VERSION "HNNBNNNYNNNNNNNNNNNNNNNNNNNNNNNNNNNNNNNNNN/4/%%%/4/'%**4NNN///"

NS_ :

BS_:

BU_: BAP_Tester BedienDisp_mi BedienDisp_vo_mi CDI ConMod_CD DashCAM Gateway_Max ICC_IO_Node LSH OCU RDK_RS3 Sound_MIB_ab_Gen3 STH ZR_MIB_EINSTIEG_ab_Gen3 ZR_MIB_OPTION_ab_Gen3 ZR_MIB_TOP_ab_Gen3

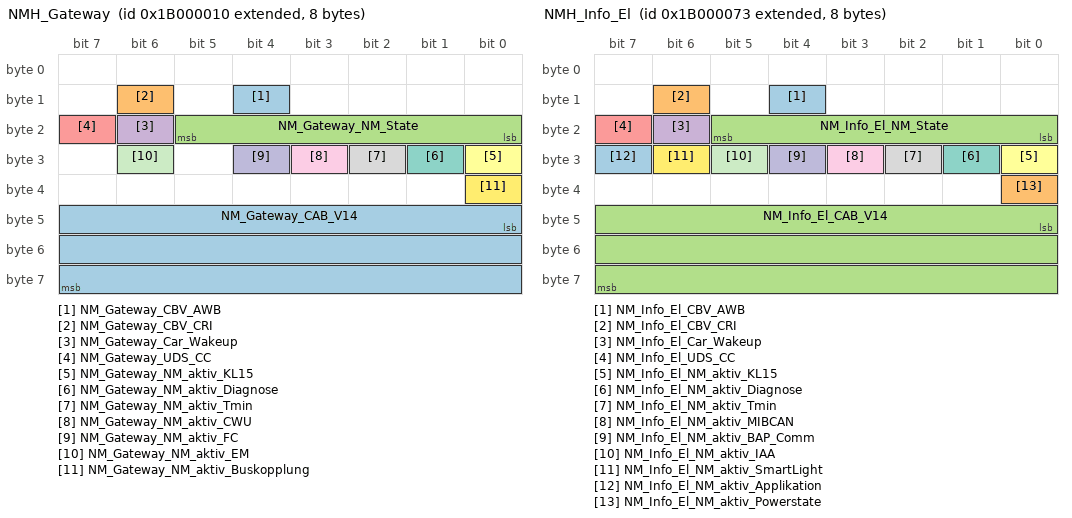
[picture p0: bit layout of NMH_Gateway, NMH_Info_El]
BO_ 2600468496 NMH_Gateway: 8 Gateway_Max
 SG_ NM_Gateway_CBV_AWB : 12|1@1+ (1.0,0.0) [0.0|1] ""  Vector__XXX
 SG_ NM_Gateway_CBV_CRI : 14|1@1+ (1.0,0.0) [0.0|1] ""  Vector__XXX
 SG_ NM_Gateway_NM_State : 16|6@1+ (1.0,0.0) [0.0|63] ""  BedienDisp_mi,BedienDisp_vo_mi,CDI,ConMod_CD,DashCAM,ICC_IO_Node,LSH,OCU,RDK_RS3,Sound_MIB_ab_Gen3,STH,ZR_MIB_EINSTIEG_ab_Gen3,ZR_MIB_OPTION_ab_Gen3,ZR_MIB_TOP_ab_Gen3
 SG_ NM_Gateway_Car_Wakeup : 22|1@1+ (1.0,0.0) [0.0|1] ""  ICC_IO_Node,ZR_MIB_EINSTIEG_ab_Gen3,ZR_MIB_OPTION_ab_Gen3,ZR_MIB_TOP_ab_Gen3
 SG_ NM_Gateway_UDS_CC : 23|1@1+ (1.0,0.0) [0.0|1] ""  Vector__XXX
 SG_ NM_Gateway_NM_aktiv_KL15 : 24|1@1+ (1.0,0.0) [0.0|1] ""  Vector__XXX
 SG_ NM_Gateway_NM_aktiv_Diagnose : 25|1@1+ (1.0,0.0) [0.0|1] ""  Vector__XXX
 SG_ NM_Gateway_NM_aktiv_Tmin : 26|1@1+ (1.0,0.0) [0.0|1] ""  Vector__XXX
 SG_ NM_Gateway_NM_aktiv_CWU : 27|1@1+ (1.0,0.0) [0.0|1] ""  Vector__XXX
 SG_ NM_Gateway_NM_aktiv_FC : 28|1@1+ (1.0,0.0) [0.0|1] ""  Vector__XXX
 SG_ NM_Gateway_NM_aktiv_EM : 30|1@1+ (1.0,0.0) [0.0|1] ""  Vector__XXX
 SG_ NM_Gateway_NM_aktiv_Buskopplung : 32|1@1+ (1.0,0.0) [0.0|1] ""  Vector__XXX
 SG_ NM_Gateway_CAB_V14 : 40|24@1+ (1.0,0.0) [0.0|16777215] ""  Vector__XXX

BO_ 2600468595 NMH_Info_El: 8 ICC_IO_Node
 SG_ NM_Info_El_CBV_AWB : 12|1@1+ (1.0,0.0) [0.0|1] ""  Gateway_Max
 SG_ NM_Info_El_CBV_CRI : 14|1@1+ (1.0,0.0) [0.0|1] ""  Gateway_Max
 SG_ NM_Info_El_NM_State : 16|6@1+ (1.0,0.0) [0.0|63] ""  BedienDisp_mi,BedienDisp_vo_mi,CDI,ConMod_CD,DashCAM,LSH,OCU,RDK_RS3,Sound_MIB_ab_Gen3,STH
 SG_ NM_Info_El_Car_Wakeup : 22|1@1+ (1.0,0.0) [0.0|1] ""  Gateway_Max
 SG_ NM_Info_El_UDS_CC : 23|1@1+ (1.0,0.0) [0.0|1] ""  Vector__XXX
 SG_ NM_Info_El_NM_aktiv_KL15 : 24|1@1+ (1.0,0.0) [0.0|1] ""  Vector__XXX
 SG_ NM_Info_El_NM_aktiv_Diagnose : 25|1@1+ (1.0,0.0) [0.0|1] ""  Vector__XXX
 SG_ NM_Info_El_NM_aktiv_Tmin : 26|1@1+ (1.0,0.0) [0.0|1] ""  Vector__XXX
 SG_ NM_Info_El_NM_aktiv_MIBCAN : 27|1@1+ (1.0,0.0) [0.0|1] ""  Vector__XXX
 SG_ NM_Info_El_NM_aktiv_BAP_Comm : 28|1@1+ (1.0,0.0) [0.0|1] ""  Vector__XXX
 SG_ NM_Info_El_NM_aktiv_IAA : 29|1@1+ (1.0,0.0) [0.0|1] ""  Vector__XXX
 SG_ NM_Info_El_NM_aktiv_SmartLight : 30|1@1+ (1.0,0.0) [0.0|1] ""  Vector__XXX
 SG_ NM_Info_El_NM_aktiv_Applikation : 31|1@1+ (1.0,0.0) [0.0|1] ""  Vector__XXX
 SG_ NM_Info_El_NM_aktiv_Powerstate : 32|1@1+ (1.0,0.0) [0.0|1] ""  Vector__XXX
 SG_ NM_Info_El_CAB_V14 : 40|24@1+ (1.0,0.0) [0.0|16777215] ""  Gateway_Max

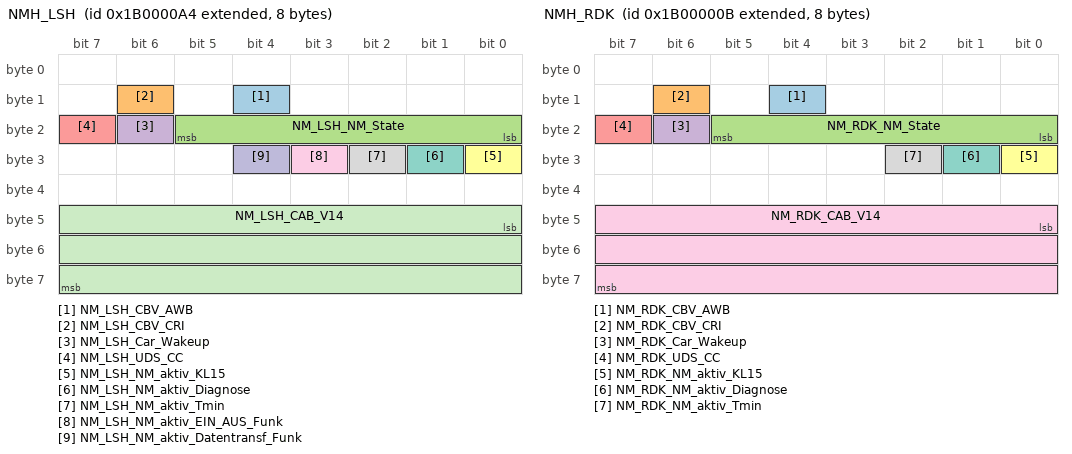
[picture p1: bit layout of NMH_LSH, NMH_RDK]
BO_ 2600468644 NMH_LSH: 8 LSH
 SG_ NM_LSH_CBV_AWB : 12|1@1+ (1.0,0.0) [0.0|1] ""  Gateway_Max
 SG_ NM_LSH_CBV_CRI : 14|1@1+ (1.0,0.0) [0.0|1] ""  Gateway_Max
 SG_ NM_LSH_NM_State : 16|6@1+ (1.0,0.0) [0.0|63] ""  BedienDisp_mi,BedienDisp_vo_mi,CDI,ConMod_CD,DashCAM,ICC_IO_Node,OCU,RDK_RS3,Sound_MIB_ab_Gen3,STH,ZR_MIB_EINSTIEG_ab_Gen3,ZR_MIB_OPTION_ab_Gen3,ZR_MIB_TOP_ab_Gen3
 SG_ NM_LSH_Car_Wakeup : 22|1@1+ (1.0,0.0) [0.0|1] ""  Gateway_Max
 SG_ NM_LSH_UDS_CC : 23|1@1+ (1.0,0.0) [0.0|1] ""  Vector__XXX
 SG_ NM_LSH_NM_aktiv_KL15 : 24|1@1+ (1.0,0.0) [0.0|1] ""  Vector__XXX
 SG_ NM_LSH_NM_aktiv_Diagnose : 25|1@1+ (1.0,0.0) [0.0|1] ""  Vector__XXX
 SG_ NM_LSH_NM_aktiv_Tmin : 26|1@1+ (1.0,0.0) [0.0|1] ""  Vector__XXX
 SG_ NM_LSH_NM_aktiv_EIN_AUS_Funk : 27|1@1+ (1.0,0.0) [0.0|1] ""  Vector__XXX
 SG_ NM_LSH_NM_aktiv_Datentransf_Funk : 28|1@1+ (1.0,0.0) [0.0|1] ""  Vector__XXX
 SG_ NM_LSH_CAB_V14 : 40|24@1+ (1.0,0.0) [0.0|16777215] ""  Gateway_Max

BO_ 2600468491 NMH_RDK: 8 RDK_RS3
 SG_ NM_RDK_CBV_AWB : 12|1@1+ (1.0,0.0) [0.0|1] ""  Gateway_Max
 SG_ NM_RDK_CBV_CRI : 14|1@1+ (1.0,0.0) [0.0|1] ""  Gateway_Max
 SG_ NM_RDK_NM_State : 16|6@1+ (1.0,0.0) [0.0|63] ""  BedienDisp_mi,BedienDisp_vo_mi,CDI,ConMod_CD,DashCAM,ICC_IO_Node,LSH,OCU,Sound_MIB_ab_Gen3,STH,ZR_MIB_EINSTIEG_ab_Gen3,ZR_MIB_OPTION_ab_Gen3,ZR_MIB_TOP_ab_Gen3
 SG_ NM_RDK_Car_Wakeup : 22|1@1+ (1.0,0.0) [0.0|1] ""  Gateway_Max
 SG_ NM_RDK_UDS_CC : 23|1@1+ (1.0,0.0) [0.0|1] ""  Vector__XXX
 SG_ NM_RDK_NM_aktiv_KL15 : 24|1@1+ (1.0,0.0) [0.0|1] ""  Vector__XXX
 SG_ NM_RDK_NM_aktiv_Diagnose : 25|1@1+ (1.0,0.0) [0.0|1] ""  Vector__XXX
 SG_ NM_RDK_NM_aktiv_Tmin : 26|1@1+ (1.0,0.0) [0.0|1] ""  Vector__XXX
 SG_ NM_RDK_CAB_V14 : 40|24@1+ (1.0,0.0) [0.0|16777215] ""  Gateway_Max

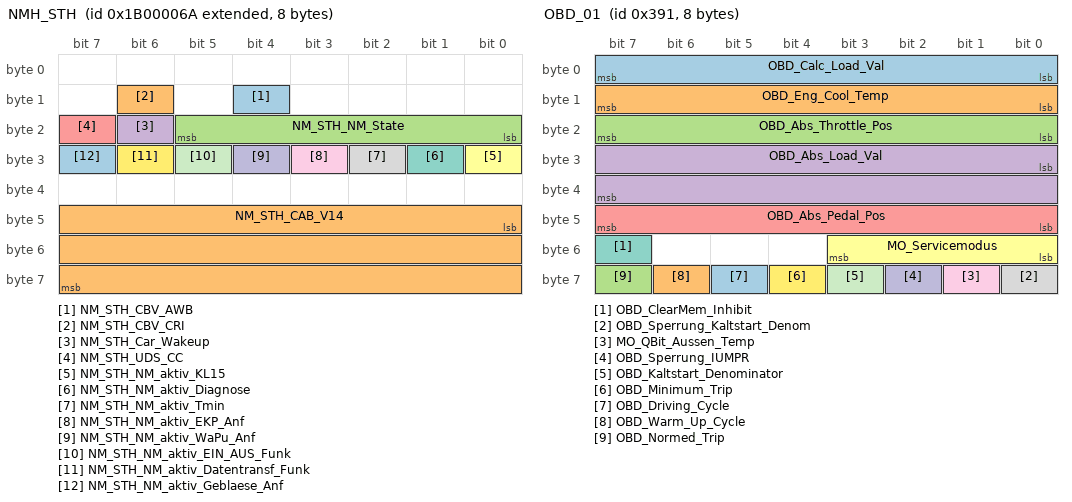
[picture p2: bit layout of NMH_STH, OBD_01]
BO_ 2600468586 NMH_STH: 8 STH
 SG_ NM_STH_CBV_AWB : 12|1@1+ (1.0,0.0) [0.0|1] ""  Gateway_Max
 SG_ NM_STH_CBV_CRI : 14|1@1+ (1.0,0.0) [0.0|1] ""  Gateway_Max
 SG_ NM_STH_NM_State : 16|6@1+ (1.0,0.0) [0.0|63] ""  BedienDisp_mi,BedienDisp_vo_mi,CDI,ConMod_CD,DashCAM,ICC_IO_Node,LSH,OCU,RDK_RS3,Sound_MIB_ab_Gen3,ZR_MIB_EINSTIEG_ab_Gen3,ZR_MIB_OPTION_ab_Gen3,ZR_MIB_TOP_ab_Gen3
 SG_ NM_STH_Car_Wakeup : 22|1@1+ (1.0,0.0) [0.0|1] ""  Gateway_Max
 SG_ NM_STH_UDS_CC : 23|1@1+ (1.0,0.0) [0.0|1] ""  Vector__XXX
 SG_ NM_STH_NM_aktiv_KL15 : 24|1@1+ (1.0,0.0) [0.0|1] ""  Vector__XXX
 SG_ NM_STH_NM_aktiv_Diagnose : 25|1@1+ (1.0,0.0) [0.0|1] ""  Vector__XXX
 SG_ NM_STH_NM_aktiv_Tmin : 26|1@1+ (1.0,0.0) [0.0|1] ""  Vector__XXX
 SG_ NM_STH_NM_aktiv_EKP_Anf : 27|1@1+ (1.0,0.0) [0.0|1] ""  Vector__XXX
 SG_ NM_STH_NM_aktiv_WaPu_Anf : 28|1@1+ (1.0,0.0) [0.0|1] ""  Vector__XXX
 SG_ NM_STH_NM_aktiv_EIN_AUS_Funk : 29|1@1+ (1.0,0.0) [0.0|1] ""  Vector__XXX
 SG_ NM_STH_NM_aktiv_Datentransf_Funk : 30|1@1+ (1.0,0.0) [0.0|1] ""  Vector__XXX
 SG_ NM_STH_NM_aktiv_Geblaese_Anf : 31|1@1+ (1.0,0.0) [0.0|1] ""  Vector__XXX
 SG_ NM_STH_CAB_V14 : 40|24@1+ (1.0,0.0) [0.0|16777215] ""  Gateway_Max

BO_ 2589283909 NR_01_CAL_Text_01: 8 Gateway_Max
 SG_ NR_01_CAL_Text_Request : 0|1@1+ (1.0,0.0) [0.0|1] ""  ZR_MIB_EINSTIEG_ab_Gen3,ZR_MIB_OPTION_ab_Gen3,ZR_MIB_TOP_ab_Gen3
 SG_ NR_01_CAL_Text_Data_1 : 8|56@1+ (1.0,0.0) [0.0|72057594037927935] ""  ZR_MIB_EINSTIEG_ab_Gen3,ZR_MIB_OPTION_ab_Gen3,ZR_MIB_TOP_ab_Gen3

BO_ 2589283910 NR_01_CAL_Text_02: 8 Gateway_Max
 SG_ NR_01_CAL_Text_Data_2 : 0|64@1+ (1.0,0.0) [0.0|18446744073709551615] ""  ZR_MIB_EINSTIEG_ab_Gen3,ZR_MIB_OPTION_ab_Gen3,ZR_MIB_TOP_ab_Gen3

BO_ 2589283911 NR_01_CAL_Text_03: 8 Gateway_Max
 SG_ NR_01_CAL_Text_Data_3 : 0|64@1+ (1.0,0.0) [0.0|18446744073709551615] ""  ZR_MIB_EINSTIEG_ab_Gen3,ZR_MIB_OPTION_ab_Gen3,ZR_MIB_TOP_ab_Gen3

BO_ 2589283912 NR_02_CAL_Text_01: 8 Gateway_Max
 SG_ NR_02_CAL_Text_Request : 0|1@1+ (1.0,0.0) [0.0|1] ""  ZR_MIB_EINSTIEG_ab_Gen3,ZR_MIB_OPTION_ab_Gen3,ZR_MIB_TOP_ab_Gen3
 SG_ NR_02_CAL_Text_Data_1 : 8|56@1+ (1.0,0.0) [0.0|72057594037927935] ""  ZR_MIB_EINSTIEG_ab_Gen3,ZR_MIB_OPTION_ab_Gen3,ZR_MIB_TOP_ab_Gen3

BO_ 2589283913 NR_02_CAL_Text_02: 8 Gateway_Max
 SG_ NR_02_CAL_Text_Data_2 : 0|64@1+ (1.0,0.0) [0.0|18446744073709551615] ""  ZR_MIB_EINSTIEG_ab_Gen3,ZR_MIB_OPTION_ab_Gen3,ZR_MIB_TOP_ab_Gen3

BO_ 2589283914 NR_02_CAL_Text_03: 8 Gateway_Max
 SG_ NR_02_CAL_Text_Data_3 : 0|64@1+ (1.0,0.0) [0.0|18446744073709551615] ""  ZR_MIB_EINSTIEG_ab_Gen3,ZR_MIB_OPTION_ab_Gen3,ZR_MIB_TOP_ab_Gen3

BO_ 2589283915 NR_03_CAL_Text_01: 8 Gateway_Max
 SG_ NR_03_CAL_Text_Request : 0|1@1+ (1.0,0.0) [0.0|1] ""  ZR_MIB_EINSTIEG_ab_Gen3,ZR_MIB_OPTION_ab_Gen3,ZR_MIB_TOP_ab_Gen3
 SG_ NR_03_CAL_Text_Data_1 : 8|56@1+ (1.0,0.0) [0.0|72057594037927935] ""  ZR_MIB_EINSTIEG_ab_Gen3,ZR_MIB_OPTION_ab_Gen3,ZR_MIB_TOP_ab_Gen3

BO_ 2589283916 NR_03_CAL_Text_02: 8 Gateway_Max
 SG_ NR_03_CAL_Text_Data_2 : 0|64@1+ (1.0,0.0) [0.0|18446744073709551615] ""  ZR_MIB_EINSTIEG_ab_Gen3,ZR_MIB_OPTION_ab_Gen3,ZR_MIB_TOP_ab_Gen3

BO_ 2589283917 NR_03_CAL_Text_03: 8 Gateway_Max
 SG_ NR_03_CAL_Text_Data_3 : 0|64@1+ (1.0,0.0) [0.0|18446744073709551615] ""  ZR_MIB_EINSTIEG_ab_Gen3,ZR_MIB_OPTION_ab_Gen3,ZR_MIB_TOP_ab_Gen3

BO_ 2589283918 NR_04_CAL_Text_01: 8 Gateway_Max
 SG_ NR_04_CAL_Text_Request : 0|1@1+ (1.0,0.0) [0.0|1] ""  ZR_MIB_EINSTIEG_ab_Gen3,ZR_MIB_OPTION_ab_Gen3,ZR_MIB_TOP_ab_Gen3
 SG_ NR_04_CAL_Text_Data_1 : 8|56@1+ (1.0,0.0) [0.0|72057594037927935] ""  ZR_MIB_EINSTIEG_ab_Gen3,ZR_MIB_OPTION_ab_Gen3,ZR_MIB_TOP_ab_Gen3

BO_ 2589283919 NR_04_CAL_Text_02: 8 Gateway_Max
 SG_ NR_04_CAL_Text_Data_2 : 0|64@1+ (1.0,0.0) [0.0|18446744073709551615] ""  ZR_MIB_EINSTIEG_ab_Gen3,ZR_MIB_OPTION_ab_Gen3,ZR_MIB_TOP_ab_Gen3

BO_ 2589283920 NR_04_CAL_Text_03: 8 Gateway_Max
 SG_ NR_04_CAL_Text_Data_3 : 0|64@1+ (1.0,0.0) [0.0|18446744073709551615] ""  ZR_MIB_EINSTIEG_ab_Gen3,ZR_MIB_OPTION_ab_Gen3,ZR_MIB_TOP_ab_Gen3

BO_ 2589284036 NR_05_CAL_Text_01: 8 Gateway_Max
 SG_ NR_05_CAL_Text_Request : 0|1@1+ (1.0,0.0) [0.0|1] ""  ZR_MIB_EINSTIEG_ab_Gen3,ZR_MIB_OPTION_ab_Gen3,ZR_MIB_TOP_ab_Gen3
 SG_ NR_05_CAL_Text_Data_1 : 8|56@1+ (1.0,0.0) [0.0|72057594037927935] ""  ZR_MIB_EINSTIEG_ab_Gen3,ZR_MIB_OPTION_ab_Gen3,ZR_MIB_TOP_ab_Gen3

BO_ 2589284037 NR_05_CAL_Text_02: 8 Gateway_Max
 SG_ NR_05_CAL_Text_Data_2 : 0|64@1+ (1.0,0.0) [0.0|18446744073709551615] ""  ZR_MIB_EINSTIEG_ab_Gen3,ZR_MIB_OPTION_ab_Gen3,ZR_MIB_TOP_ab_Gen3

BO_ 2589284038 NR_05_CAL_Text_03: 8 Gateway_Max
 SG_ NR_05_CAL_Text_Data_3 : 0|64@1+ (1.0,0.0) [0.0|18446744073709551615] ""  ZR_MIB_EINSTIEG_ab_Gen3,ZR_MIB_OPTION_ab_Gen3,ZR_MIB_TOP_ab_Gen3

BO_ 2589284039 NR_06_CAL_Text_01: 8 Gateway_Max
 SG_ NR_06_CAL_Text_Request : 0|1@1+ (1.0,0.0) [0.0|1] ""  ZR_MIB_EINSTIEG_ab_Gen3,ZR_MIB_OPTION_ab_Gen3,ZR_MIB_TOP_ab_Gen3
 SG_ NR_06_CAL_Text_Data_1 : 8|56@1+ (1.0,0.0) [0.0|72057594037927935] ""  ZR_MIB_EINSTIEG_ab_Gen3,ZR_MIB_OPTION_ab_Gen3,ZR_MIB_TOP_ab_Gen3

BO_ 2589284040 NR_06_CAL_Text_02: 8 Gateway_Max
 SG_ NR_06_CAL_Text_Data_2 : 0|64@1+ (1.0,0.0) [0.0|18446744073709551615] ""  ZR_MIB_EINSTIEG_ab_Gen3,ZR_MIB_OPTION_ab_Gen3,ZR_MIB_TOP_ab_Gen3

BO_ 2589284041 NR_06_CAL_Text_03: 8 Gateway_Max
 SG_ NR_06_CAL_Text_Data_3 : 0|64@1+ (1.0,0.0) [0.0|18446744073709551615] ""  ZR_MIB_EINSTIEG_ab_Gen3,ZR_MIB_OPTION_ab_Gen3,ZR_MIB_TOP_ab_Gen3

BO_ 913 OBD_01: 8 Gateway_Max
 SG_ OBD_Calc_Load_Val : 0|8@1+ (0.39215686274509803,0) [0E-17|99.99999999999999765] "Unit_PerCent"  OCU
 SG_ OBD_Eng_Cool_Temp : 8|8@1+ (1,-40) [-40|215] "Unit_DegreCelsi"  Vector__XXX
 SG_ OBD_Abs_Throttle_Pos : 16|8@1+ (0.39215686274509803,0) [0E-17|99.99999999999999765] "Unit_PerCent"  OCU
 SG_ OBD_Abs_Load_Val : 24|16@1+ (0.39215686274509803,0) [0E-17|25699.99999999999939605] "Unit_PerCent"  OCU
 SG_ OBD_Abs_Pedal_Pos : 40|8@1+ (0.39215686274509803,0) [0E-17|99.99999999999999765] "Unit_PerCent"  OCU
 SG_ MO_Servicemodus : 48|4@1+ (1.0,0.0) [0.0|15] ""  OCU
 SG_ OBD_ClearMem_Inhibit : 55|1@1+ (1.0,0.0) [0.0|1] ""  Vector__XXX
 SG_ OBD_Sperrung_Kaltstart_Denom : 56|1@1+ (1.0,0.0) [0.0|1] ""  Vector__XXX
 SG_ MO_QBit_Aussen_Temp : 57|1@1+ (1.0,0.0) [0.0|1] ""  OCU
 SG_ OBD_Sperrung_IUMPR : 58|1@1+ (1.0,0.0) [0.0|1] ""  Vector__XXX
 SG_ OBD_Kaltstart_Denominator : 59|1@1+ (1.0,0.0) [0.0|1] ""  ConMod_CD
 SG_ OBD_Minimum_Trip : 60|1@1+ (1.0,0.0) [0.0|1] ""  Vector__XXX
 SG_ OBD_Driving_Cycle : 61|1@1+ (1.0,0.0) [0.0|1] ""  BedienDisp_mi,ConMod_CD,DashCAM,ICC_IO_Node,ZR_MIB_EINSTIEG_ab_Gen3,ZR_MIB_OPTION_ab_Gen3,ZR_MIB_TOP_ab_Gen3
 SG_ OBD_Warm_Up_Cycle : 62|1@1+ (1.0,0.0) [0.0|1] ""  ConMod_CD,ICC_IO_Node,OCU
 SG_ OBD_Normed_Trip : 63|1@1+ (1.0,0.0) [0.0|1] ""  Vector__XXX

BO_ 2550399540 OBDC_BedienDisp_m_Req: 8 Gateway_Max
 SG_ OBDC_BedienDisp_m_Req_Data : 0|64@1+ (1.0,0.0) [0.0|18446744073709551615] ""  BedienDisp_mi

BO_ 2550530612 OBDC_BedienDisp_m_Resp: 8 BedienDisp_mi
 SG_ OBDC_BedienDisp_m_Resp_Data : 0|64@1+ (1.0,0.0) [0.0|18446744073709551615] ""  Gateway_Max

BO_ 2549875362 OBDC_BedienDisp_vm_Req: 8 Gateway_Max
 SG_ OBDC_BedienDisp_vm_Req_Data : 0|64@1+ (1.0,0.0) [0.0|18446744073709551615] ""  BedienDisp_vo_mi

BO_ 2550006434 OBDC_BedienDisp_vm_Resp: 8 BedienDisp_vo_mi
 SG_ OBDC_BedienDisp_vm_Resp_Data : 0|64@1+ (1.0,0.0) [0.0|18446744073709551615] ""  Gateway_Max

BO_ 2549875303 OBDC_eCall_Req: 8 Gateway_Max
 SG_ OBDC_eCall_Req_Data : 0|64@1+ (1.0,0.0) [0.0|18446744073709551615] ""  ConMod_CD,OCU

BO_ 2550006375 OBDC_eCall_Resp: 8 ConMod_CD
 SG_ OBDC_eCall_Resp_Data : 0|64@1+ (1.0,0.0) [0.0|18446744073709551615] ""  Gateway_Max

BO_ 2549940736 OBDC_Funktionaler_Req_All: 8 Gateway_Max
 SG_ OBDC_Funktionaler_Req_All_Data : 0|64@1+ (1.0,0.0) [0.0|18446744073709551615] ""  BedienDisp_mi,BedienDisp_vo_mi,ConMod_CD,ICC_IO_Node,LSH,OCU,RDK_RS3,STH,ZR_MIB_EINSTIEG_ab_Gen3,ZR_MIB_OPTION_ab_Gen3,ZR_MIB_TOP_ab_Gen3

BO_ 2549875315 OBDC_Info_El_Req: 8 Gateway_Max
 SG_ OBDC_Info_El_Req_Data : 0|64@1+ (1.0,0.0) [0.0|18446744073709551615] ""  ZR_MIB_EINSTIEG_ab_Gen3,ZR_MIB_OPTION_ab_Gen3,ZR_MIB_TOP_ab_Gen3

BO_ 2550006387 OBDC_Info_El_Resp: 8 ZR_MIB_EINSTIEG_ab_Gen3
 SG_ OBDC_Info_El_Resp_Data : 0|64@1+ (1.0,0.0) [0.0|18446744073709551615] ""  Gateway_Max

BO_ 2549875364 OBDC_LSH_Req: 8 Gateway_Max
 SG_ OBDC_LSH_Req_Data : 0|64@1+ (1.0,0.0) [0.0|18446744073709551615] ""  LSH

BO_ 2550006436 OBDC_LSH_Resp: 8 LSH
 SG_ OBDC_LSH_Resp_Data : 0|64@1+ (1.0,0.0) [0.0|18446744073709551615] ""  Gateway_Max

BO_ 2549875211 OBDC_RDK_Req: 8 Gateway_Max
 SG_ OBDC_RDK_Req_Data : 0|64@1+ (1.0,0.0) [0.0|18446744073709551615] ""  RDK_RS3

BO_ 2550006283 OBDC_RDK_Resp: 8 RDK_RS3
 SG_ OBDC_RDK_Resp_Data : 0|64@1+ (1.0,0.0) [0.0|18446744073709551615] ""  Gateway_Max

BO_ 2549903374 OBDC_SSN_ABT_1_Req: 8 Gateway_Max
 SG_ OBDC_SSN_ABT_1_Req_Data : 0|64@1+ (1.0,0.0) [0.0|18446744073709551615] ""  ICC_IO_Node,ZR_MIB_EINSTIEG_ab_Gen3,ZR_MIB_OPTION_ab_Gen3

BO_ 2550034446 OBDC_SSN_ABT_1_Resp: 8 ICC_IO_Node
 SG_ OBDC_SSN_ABT_1_Resp_Data : 0|64@1+ (1.0,0.0) [0.0|18446744073709551615] ""  Gateway_Max

BO_ 2549875306 OBDC_STH_Req: 8 Gateway_Max
 SG_ OBDC_STH_Req_Data : 0|64@1+ (1.0,0.0) [0.0|18446744073709551615] ""  STH

BO_ 2550006378 OBDC_STH_Resp: 8 STH
 SG_ OBDC_STH_Resp_Data : 0|64@1+ (1.0,0.0) [0.0|18446744073709551615] ""  Gateway_Max

BO_ 2549875309 OBDC_TV_Tuner_Req: 8 Gateway_Max
 SG_ OBDC_TV_Tuner_Req_Data : 0|64@1+ (1.0,0.0) [0.0|18446744073709551615] ""  ZR_MIB_TOP_ab_Gen3

BO_ 2550006381 OBDC_TV_Tuner_Resp: 8 ZR_MIB_TOP_ab_Gen3
 SG_ OBDC_TV_Tuner_Resp_Data : 0|64@1+ (1.0,0.0) [0.0|18446744073709551615] ""  Gateway_Max

BO_ 2549875365 OBDC_WLC1_Req: 8 Gateway_Max
 SG_ OBDC_WLC1_Req_Data : 0|64@1+ (1,0) [0|18446744073709551615] "Unit_None"  ZR_MIB_OPTION_ab_Gen3,ZR_MIB_TOP_ab_Gen3

BO_ 2550006437 OBDC_WLC1_Resp: 8 ZR_MIB_OPTION_ab_Gen3
 SG_ OBDC_WLC1_Resp_Data : 0|64@1+ (1,0) [0|18446744073709551615] "Unit_None"  Gateway_Max

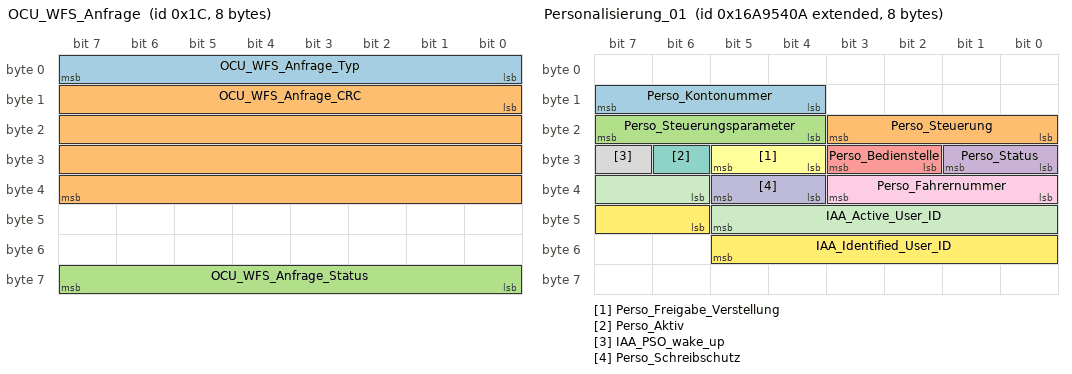
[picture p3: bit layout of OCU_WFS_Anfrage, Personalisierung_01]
BO_ 28 OCU_WFS_Anfrage: 8 OCU
 SG_ OCU_WFS_Anfrage_Typ : 0|8@1+ (1.0,0.0) [0.0|255] ""  Gateway_Max
 SG_ OCU_WFS_Anfrage_CRC : 8|32@1+ (1.0,0.0) [0.0|4294967295] ""  Gateway_Max
 SG_ OCU_WFS_Anfrage_Status : 56|8@1+ (1.0,0.0) [0.0|255] ""  Gateway_Max

BO_ 2589283656 ORU_01: 8 Gateway_Max
 SG_ ORU_Warnung : 58|2@1+ (1.0,0.0) [0.0|3] ""  ICC_IO_Node,ZR_MIB_EINSTIEG_ab_Gen3,ZR_MIB_OPTION_ab_Gen3,ZR_MIB_TOP_ab_Gen3
 SG_ ORU_Status : 61|3@1+ (1.0,0.0) [0.0|7] ""  ConMod_CD,ICC_IO_Node,OCU,ZR_MIB_EINSTIEG_ab_Gen3,ZR_MIB_OPTION_ab_Gen3,ZR_MIB_TOP_ab_Gen3

BO_ 2549909095 ORU_eCall_Req: 8 ICC_IO_Node
 SG_ ORU_eCall_Req_Data : 0|64@1+ (1.0,0.0) [0.0|18446744073709551615] ""  ConMod_CD

BO_ 2550040167 ORU_eCall_Resp: 8 ConMod_CD
 SG_ ORU_eCall_Resp_Data : 0|64@1+ (1.0,0.0) [0.0|18446744073709551615] ""  ICC_IO_Node

BO_ 1175 Parkhilfe_01: 8 Gateway_Max
 SG_ PH_Visualisierung : 0|3@1+ (1.0,0.0) [0.0|7] ""  Vector__XXX
 SG_ PDC_Tonausgabe_Front : 4|4@1+ (1.0,0.0) [0.0|15] ""  Vector__XXX
 SG_ PDC_Tonausgabe_Heck : 8|4@1+ (1.0,0.0) [0.0|15] ""  Vector__XXX
 SG_ PH_nachtr_Stopp_Anf : 12|1@1+ (1.0,0.0) [0.0|1] ""  Vector__XXX
 SG_ PH_Abschaltursache : 13|3@1+ (1.0,0.0) [0.0|7] ""  Vector__XXX
 SG_ PH_Opt_Anzeige_V_ein : 16|1@1+ (1.0,0.0) [0.0|1] ""  Vector__XXX
 SG_ PH_Opt_Anzeige_H_ein : 17|1@1+ (1.0,0.0) [0.0|1] ""  Vector__XXX
 SG_ PH_Opt_Anz_V_Hindernis : 18|1@1+ (1.0,0.0) [0.0|1] ""  Vector__XXX
 SG_ PH_Opt_Anz_H_Hindernis : 19|1@1+ (1.0,0.0) [0.0|1] ""  Vector__XXX
 SG_ PH_Tongeber_V_aktiv : 20|1@1+ (1.0,0.0) [0.0|1] ""  Vector__XXX
 SG_ PH_Tongeber_H_aktiv : 21|1@1+ (1.0,0.0) [0.0|1] ""  Vector__XXX
 SG_ PH_Tongeber_mute : 22|1@1+ (1.0,0.0) [0.0|1] ""  Vector__XXX
 SG_ PH_Anf_Audioabsenkung : 23|1@1+ (1.0,0.0) [0.0|1] ""  OCU,ZR_MIB_EINSTIEG_ab_Gen3,ZR_MIB_OPTION_ab_Gen3,ZR_MIB_TOP_ab_Gen3
 SG_ PH_Tongeber_H_verfuegbar : 24|1@1+ (1.0,0.0) [0.0|1] ""  Vector__XXX
 SG_ PLA_Anf_Aufschaltung_RVC : 25|1@1+ (1.0,0.0) [0.0|1] ""  Vector__XXX
 SG_ PH_Taster : 28|2@1+ (1.0,0.0) [0.0|3] ""  Vector__XXX
 SG_ PH_Anf_Verdeck : 30|2@1+ (1.0,0.0) [0.0|3] ""  Vector__XXX
 SG_ PH_Frequenz_hinten : 32|4@1+ (1,0) [0|15] ""  Vector__XXX
 SG_ PH_Lautstaerke_hinten : 36|4@1+ (1,0) [0|15] ""  Vector__XXX
 SG_ PH_Frequenz_vorn : 40|4@1+ (1,0) [0|15] ""  Vector__XXX
 SG_ PH_Lautstaerke_vorn : 44|4@1+ (1,0) [0|15] ""  Vector__XXX
 SG_ PH_StartStopp_Info : 49|2@1+ (1.0,0.0) [0.0|3] ""  Vector__XXX
 SG_ PH_Stoermeldung : 52|4@1+ (1.0,0.0) [0.0|15] ""  Vector__XXX
 SG_ PH_defekt : 56|1@1+ (1.0,0.0) [0.0|1] ""  Vector__XXX
 SG_ PH_gestoert : 57|1@1+ (1.0,0.0) [0.0|1] ""  Vector__XXX
 SG_ PH_Systemzustand : 58|3@1+ (1.0,0.0) [0.0|7] ""  Vector__XXX
 SG_ PH_Display_Kundenwunsch : 61|2@1+ (1.0,0.0) [0.0|3] ""  Vector__XXX

BO_ 1355 Parkhilfe_04: 8 Gateway_Max
 SG_ RBFMA_PaCo_BrakeIntervention : 0|3@1+ (1.0,0.0) [0.0|7] ""  OCU
 SG_ RBFMA_PaCo_MainState : 3|3@1+ (1.0,0.0) [0.0|7] ""  OCU
 SG_ RAB_PaCo_FunctionState : 6|3@1+ (1.0,0.0) [0.0|7] ""  Vector__XXX
 SG_ RBF_Anf_Meldungen : 9|3@1+ (1.0,0.0) [0.0|7] ""  Vector__XXX
 SG_ PH_Verschmutzungsmeldung : 12|4@1+ (1.0,0.0) [0.0|15] ""  OCU
 SG_ PH_Aufschaltursache : 16|5@1+ (1.0,0.0) [0.0|31] ""  Vector__XXX
 SG_ PH_Ton_Ausgabe : 21|3@1+ (1.0,0.0) [0.0|7] ""  OCU,ZR_MIB_EINSTIEG_ab_Gen3,ZR_MIB_OPTION_ab_Gen3,ZR_MIB_TOP_ab_Gen3
 SG_ PH_Ton_Pausenlaenge : 24|8@1+ (1.0,0.0) [0.0|255] ""  OCU,ZR_MIB_EINSTIEG_ab_Gen3,ZR_MIB_OPTION_ab_Gen3,ZR_MIB_TOP_ab_Gen3
 SG_ APSOPS_PaCo_ObstacleDetectRear : 32|3@1+ (1.0,0.0) [0.0|7] ""  OCU
 SG_ APSOPS_PaCo_ObstacleDetectFront : 35|3@1+ (1.0,0.0) [0.0|7] ""  OCU
 SG_ APSOPS_PaCo_Button : 38|2@1+ (1.0,0.0) [0.0|3] ""  OCU
 SG_ APSOPS_PaCo_MainState : 40|3@1+ (1.0,0.0) [0.0|7] ""  OCU
 SG_ APSOPS_PaCo_FunctionState : 43|3@1+ (1.0,0.0) [0.0|7] ""  OCU
 SG_ APSOPS_PaCo_ApproachingRear : 46|1@1+ (1.0,0.0) [0.0|1] ""  OCU
 SG_ APSOPS_PaCo_ApproachingFront : 47|1@1+ (1.0,0.0) [0.0|1] ""  OCU
 SG_ APS_PaCo_WarningTones : 48|1@1+ (1.0,0.0) [0.0|1] ""  OCU
 SG_ PH_Ton_Richtung : 49|3@1+ (1.0,0.0) [0.0|7] ""  OCU,ZR_MIB_EINSTIEG_ab_Gen3,ZR_MIB_OPTION_ab_Gen3,ZR_MIB_TOP_ab_Gen3
 SG_ PH_Ton_Lautstaerke : 52|3@1+ (1.0,0.0) [0.0|7] ""  OCU,ZR_MIB_EINSTIEG_ab_Gen3,ZR_MIB_OPTION_ab_Gen3,ZR_MIB_TOP_ab_Gen3
 SG_ PH_WAH_Meldung : 55|3@1+ (1.0,0.0) [0.0|7] ""  Vector__XXX
 SG_ RBF_PaCo_Anf_Meldungen : 58|3@1+ (1.0,0.0) [0.0|7] ""  Vector__XXX
 SG_ RBF_PMO_Bereich_erkannt : 61|1@1+ (1.0,0.0) [0.0|1] ""  Vector__XXX

BO_ 2527679498 Personalisierung_01: 8 Gateway_Max
 SG_ Perso_Kontonummer : 12|4@1+ (1.0,0.0) [0.0|15] ""  OCU,ZR_MIB_EINSTIEG_ab_Gen3,ZR_MIB_OPTION_ab_Gen3,ZR_MIB_TOP_ab_Gen3
 SG_ Perso_Steuerung : 16|4@1+ (1.0,0.0) [0.0|15] ""  OCU,ZR_MIB_EINSTIEG_ab_Gen3,ZR_MIB_OPTION_ab_Gen3,ZR_MIB_TOP_ab_Gen3
 SG_ Perso_Steuerungsparameter : 20|4@1+ (1.0,0.0) [0.0|15] ""  OCU,ZR_MIB_EINSTIEG_ab_Gen3,ZR_MIB_OPTION_ab_Gen3,ZR_MIB_TOP_ab_Gen3
 SG_ Perso_Status : 24|2@1+ (1.0,0.0) [0.0|3] ""  OCU,ZR_MIB_EINSTIEG_ab_Gen3,ZR_MIB_OPTION_ab_Gen3,ZR_MIB_TOP_ab_Gen3
 SG_ Perso_Bedienstelle : 26|2@1+ (1.0,0.0) [0.0|3] ""  OCU
 SG_ Perso_Freigabe_Verstellung : 28|2@1+ (1.0,0.0) [0.0|3] ""  OCU
 SG_ Perso_Aktiv : 30|1@1+ (1.0,0.0) [0.0|1] ""  OCU
 SG_ IAA_PSO_wake_up : 31|1@1+ (1.0,0.0) [0.0|1] ""  OCU,ZR_MIB_EINSTIEG_ab_Gen3,ZR_MIB_OPTION_ab_Gen3,ZR_MIB_TOP_ab_Gen3
 SG_ Perso_Fahrernummer : 32|4@1+ (1.0,0.0) [0.0|15] ""  OCU,ZR_MIB_TOP_ab_Gen3
 SG_ Perso_Schreibschutz : 36|2@1+ (1.0,0.0) [0.0|3] ""  OCU
 SG_ IAA_Active_User_ID : 38|8@1+ (1,0) [0|255] "Unit_None"  OCU,ZR_MIB_EINSTIEG_ab_Gen3,ZR_MIB_OPTION_ab_Gen3,ZR_MIB_TOP_ab_Gen3
 SG_ IAA_Identified_User_ID : 46|8@1+ (1,0) [0|255] "Unit_None"  OCU,ZR_MIB_EINSTIEG_ab_Gen3,ZR_MIB_OPTION_ab_Gen3,ZR_MIB_TOP_ab_Gen3

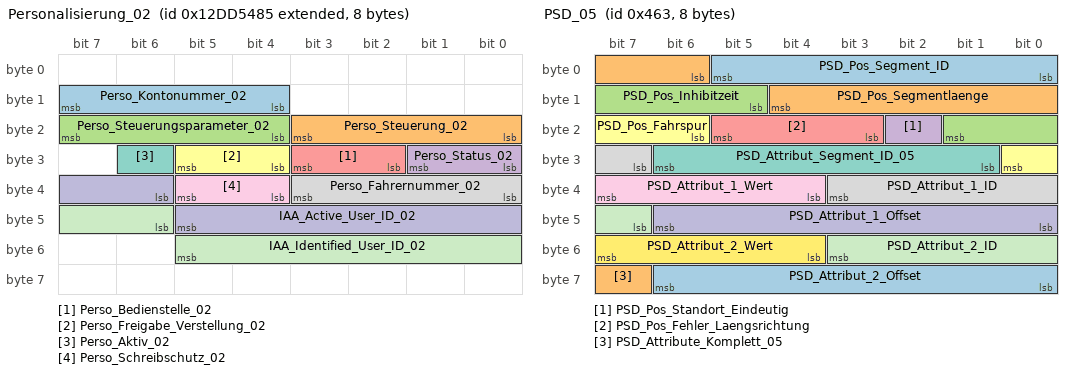
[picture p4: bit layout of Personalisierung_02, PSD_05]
BO_ 2463978629 Personalisierung_02: 8 Gateway_Max
 SG_ Perso_Kontonummer_02 : 12|4@1+ (1.0,0.0) [0.0|15] ""  Gateway_Max,ZR_MIB_EINSTIEG_ab_Gen3,ZR_MIB_TOP_ab_Gen3
 SG_ Perso_Steuerung_02 : 16|4@1+ (1.0,0.0) [0.0|15] ""  Gateway_Max,ZR_MIB_EINSTIEG_ab_Gen3,ZR_MIB_TOP_ab_Gen3
 SG_ Perso_Steuerungsparameter_02 : 20|4@1+ (1.0,0.0) [0.0|15] ""  Gateway_Max,ZR_MIB_EINSTIEG_ab_Gen3,ZR_MIB_TOP_ab_Gen3
 SG_ Perso_Status_02 : 24|2@1+ (1.0,0.0) [0.0|3] ""  Gateway_Max,ZR_MIB_EINSTIEG_ab_Gen3,ZR_MIB_TOP_ab_Gen3
 SG_ Perso_Bedienstelle_02 : 26|2@1+ (1.0,0.0) [0.0|3] ""  Gateway_Max
 SG_ Perso_Freigabe_Verstellung_02 : 28|2@1+ (1.0,0.0) [0.0|3] ""  Gateway_Max
 SG_ Perso_Aktiv_02 : 30|1@1+ (1.0,0.0) [0.0|1] ""  Gateway_Max
 SG_ Perso_Fahrernummer_02 : 32|4@1+ (1.0,0.0) [0.0|15] ""  Gateway_Max
 SG_ Perso_Schreibschutz_02 : 36|2@1+ (1.0,0.0) [0.0|3] ""  Gateway_Max
 SG_ IAA_Active_User_ID_02 : 38|8@1+ (1,0) [0|255] "Unit_None"  Gateway_Max,ZR_MIB_EINSTIEG_ab_Gen3,ZR_MIB_OPTION_ab_Gen3,ZR_MIB_TOP_ab_Gen3
 SG_ IAA_Identified_User_ID_02 : 46|8@1+ (1,0) [0|255] "Unit_None"  Gateway_Max,ZR_MIB_EINSTIEG_ab_Gen3,ZR_MIB_OPTION_ab_Gen3,ZR_MIB_TOP_ab_Gen3

BO_ 319 PreCrash_02: 8 Gateway_Max
 SG_ PreCrash_Charisma_FahrPr : 12|4@1+ (1.0,0.0) [0.0|15] ""  Vector__XXX
 SG_ PreCrash_Charisma_Status : 16|2@1+ (1.0,0.0) [0.0|3] ""  Vector__XXX
 SG_ PreCrash_Schiebedach_schliessen : 18|1@1+ (1.0,0.0) [0.0|1] ""  Vector__XXX
 SG_ PreCrash_Fenster_schliessen : 19|1@1+ (1.0,0.0) [0.0|1] ""  Vector__XXX
 SG_ PreCrash_Blinken : 20|3@1+ (1.0,0.0) [0.0|7] ""  Vector__XXX
 SG_ SC_PreSense_FCWP : 23|1@1+ (1.0,0.0) [0.0|1] ""  Vector__XXX
 SG_ PreCrash_Tueren_Verriegeln : 24|1@1+ (1.0,0.0) [0.0|1] ""  Vector__XXX
 SG_ PreCrash_FS_Laengsverstellung : 25|1@1+ (1.0,0.0) [0.0|1] ""  Vector__XXX
 SG_ PreCrash_Anforderung_AFR : 26|3@1+ (1.0,0.0) [0.0|7] ""  Vector__XXX
 SG_ SC_PreCrash_LED : 29|2@1+ (1.0,0.0) [0.0|3] ""  Vector__XXX
 SG_ PreCrash_FS_Pneumatik_ansteuern : 31|1@1+ (1.0,0.0) [0.0|1] ""  Vector__XXX
 SG_ PreCrash_BFS_Pneumatik_ansteuern : 32|1@1+ (1.0,0.0) [0.0|1] ""  Vector__XXX
 SG_ PreCrash_Fo_Pneumatik_ansteuern : 33|1@1+ (1.0,0.0) [0.0|1] ""  Vector__XXX
 SG_ PreCrash_FS_Sitzlehne_verfahren : 34|3@1+ (1.0,0.0) [0.0|7] ""  Vector__XXX
 SG_ PreCrash_BFS_Sitzlehne_verfahren : 37|3@1+ (1.0,0.0) [0.0|7] ""  Vector__XXX
 SG_ PreCrash_Fo_Sitzlehne_verfahren : 40|3@1+ (1.0,0.0) [0.0|7] ""  Vector__XXX
 SG_ PreCrash_FS_KSV_verfahren : 43|4@1+ (1.0,0.0) [0.0|15] ""  Vector__XXX
 SG_ PreCrash_BFS_KSV_verfahren : 47|4@1+ (1.0,0.0) [0.0|15] ""  Vector__XXX
 SG_ PreCrash_Fo_KSV_verfahren : 51|4@1+ (1.0,0.0) [0.0|15] ""  Vector__XXX
 SG_ PreCrash_BFS_Laengsverstellung : 55|1@1+ (1.0,0.0) [0.0|1] ""  Vector__XXX
 SG_ SC_PreCrash_Warnung : 56|4@1+ (1.0,0.0) [0.0|15] ""  OCU
 SG_ SC_PreCrash_Texte : 60|4@1+ (1.0,0.0) [0.0|15] ""  Vector__XXX

BO_ 1122 PSD_04: 8 ZR_MIB_EINSTIEG_ab_Gen3
 SG_ PSD_Segment_ID : 0|6@1+ (1,0) [2|63] ""  Gateway_Max,OCU
 SG_ PSD_Vorgaenger_Segment_ID : 6|6@1+ (1,0) [2|63] ""  Gateway_Max,OCU
 SG_ PSD_Segmentlaenge : 12|7@1+ (2,0) [0|254] "Unit_Meter"  Gateway_Max,OCU
 SG_ PSD_Strassenkategorie : 19|3@1+ (1.0,0.0) [0.0|7] ""  Gateway_Max,OCU
 SG_ PSD_Endkruemmung : 22|8@1+ (1,0) [0|254] "Unit_None"  Gateway_Max,OCU
 SG_ PSD_Endkruemmung_Vorz : 30|1@1+ (1.0,0.0) [0.0|1] ""  Gateway_Max,OCU
 SG_ PSD_Idenditaets_ID : 31|6@1+ (1,0) [2|63] ""  Gateway_Max,OCU
 SG_ PSD_ADAS_Qualitaet : 37|1@1+ (1.0,0.0) [0.0|1] ""  Gateway_Max,OCU
 SG_ PSD_wahrscheinlichster_Pfad : 38|1@1+ (1.0,0.0) [0.0|1] ""  Gateway_Max,OCU
 SG_ PSD_Geradester_Pfad : 39|1@1+ (1.0,0.0) [0.0|1] ""  Gateway_Max,OCU
 SG_ PSD_Fahrspuren_Anzahl : 40|3@1+ (1.0,0.0) [0.0|7] ""  Gateway_Max,OCU
 SG_ PSD_Bebauung : 43|1@1+ (1.0,0.0) [0.0|1] ""  Gateway_Max,OCU
 SG_ PSD_Segment_Komplett : 44|1@1+ (1.0,0.0) [0.0|1] ""  Gateway_Max,OCU
 SG_ PSD_Rampe : 45|2@1+ (1.0,0.0) [0.0|3] ""  Gateway_Max,OCU
 SG_ PSD_Anfangskruemmung : 47|8@1+ (1,0) [0|254] ""  Gateway_Max,OCU
 SG_ PSD_Anfangskruemmung_Vorz : 55|1@1+ (1.0,0.0) [0.0|1] ""  Gateway_Max,OCU
 SG_ PSD_Abzweigerichtung : 56|1@1+ (1.0,0.0) [0.0|1] ""  Gateway_Max,OCU
 SG_ PSD_Abzweigewinkel : 57|7@1+ (1.417323,0) [0.000000|180.000021] ""  Gateway_Max,OCU

BO_ 1123 PSD_05: 8 ZR_MIB_EINSTIEG_ab_Gen3
 SG_ PSD_Pos_Segment_ID : 0|6@1+ (1,0) [2|63] ""  Gateway_Max,OCU
 SG_ PSD_Pos_Segmentlaenge : 6|7@1+ (2,0) [0|254] "Unit_Meter"  Gateway_Max
 SG_ PSD_Pos_Inhibitzeit : 13|5@1+ (10,0) [0|310] "Unit_MilliSecon"  Gateway_Max
 SG_ PSD_Pos_Standort_Eindeutig : 18|1@1+ (1.0,0.0) [0.0|1] ""  Gateway_Max
 SG_ PSD_Pos_Fehler_Laengsrichtung : 19|3@1+ (1.0,0.0) [0.0|7] ""  Gateway_Max
 SG_ PSD_Pos_Fahrspur : 22|3@1+ (1.0,0.0) [0.0|7] ""  Gateway_Max,OCU
 SG_ PSD_Attribut_Segment_ID_05 : 25|6@1+ (1,0) [2|63] ""  Gateway_Max
 SG_ PSD_Attribut_1_ID : 31|5@1+ (1,0) [1|31] ""  Gateway_Max
 SG_ PSD_Attribut_1_Wert : 36|4@1+ (1,0) [0|15] "Unit_None"  Gateway_Max
 SG_ PSD_Attribut_1_Offset : 40|7@1+ (2,0) [0|254] "Unit_Meter"  Gateway_Max
 SG_ PSD_Attribut_2_ID : 47|5@1+ (1,0) [1|31] ""  Gateway_Max
 SG_ PSD_Attribut_2_Wert : 52|4@1+ (1,0) [0|15] "Unit_None"  Gateway_Max
 SG_ PSD_Attribut_2_Offset : 56|7@1+ (2,0) [0|254] "Unit_Meter"  Gateway_Max
 SG_ PSD_Attribute_Komplett_05 : 63|1@1+ (1.0,0.0) [0.0|1] ""  Gateway_Max

BO_ 1124 PSD_06: 8 ZR_MIB_EINSTIEG_ab_Gen3
 SG_ PSD_06_Mux M  : 0|3@1+ (1.0,0.0) [0.0|7] ""  Gateway_Max,OCU
 SG_ PSD_Sys_Segment_ID m0  : 3|6@1+ (1,0) [2|63] ""  Gateway_Max,OCU
 SG_ PSD_Attribut_Segment_ID m1  : 3|6@1+ (1,0) [2|63] ""  Gateway_Max,OCU
 SG_ PSD_Ges_Segment_ID m2  : 3|6@1+ (1,0) [2|63] ""  Gateway_Max,OCU
 SG_ PSD_Baum_Laenge_VZ m3  : 3|1@1+ (1.0,0.0) [0.0|1] ""  Gateway_Max,OCU
 SG_ PSD_Steigung_1_Segment_ID m4  : 3|6@1+ (1,0) [2|63] ""  Gateway_Max,OCU
 SG_ PSD_Baum_Laenge m3  : 4|25@1+ (0.00001,0) [0.00000|180.00000] "Unit_DegreOfArc"  Gateway_Max,OCU
 SG_ PSD_Sys_Laendercode m0  : 9|8@1+ (1,0) [0|255] "Unit_None"  Gateway_Max,OCU
 SG_ PSD_Attribut_3_ID m1  : 9|5@1+ (1,0) [1|31] ""  Gateway_Max,OCU
 SG_ PSD_Ges_Offset m2  : 9|7@1+ (2,0) [0|254] "Unit_Meter"  Gateway_Max,OCU
 SG_ PSD_Steigung_1_A_Steigung m4  : 9|7@1+ (0.12,0) [0.00|15.00] "Unit_PerCent"  Gateway_Max,OCU
 SG_ PSD_Attribut_3_Offset m1  : 14|7@1+ (2,0) [0|254] "Unit_Meter"  Gateway_Max,OCU
 SG_ PSD_Ges_Geschwindigkeit m2  : 16|5@1+ (1.0,0.0) [0.0|31] ""  Gateway_Max,OCU
 SG_ PSD_Steigung_1_A_Vorz m4  : 16|1@1+ (1.0,0.0) [0.0|1] ""  Gateway_Max,OCU
 SG_ PSD_Sys_Geschwindigkeit_Einheit m0  : 17|1@1+ (1.0,0.0) [0.0|1] ""  Gateway_Max,OCU
 SG_ PSD_Steigung_1_A_Offset m4  : 17|7@1+ (2,0) [0|254] "Unit_Meter"  Gateway_Max,OCU
 SG_ PSD_Sys_Verkehrsrichtung m0  : 18|1@1+ (1.0,0.0) [0.0|1] ""  Gateway_Max,OCU
 SG_ PSD_Sys_Geometrieguete m0  : 19|2@1+ (1.0,0.0) [0.0|3] ""  Gateway_Max,OCU
 SG_ PSD_Sys_Mapmatchingguete m0  : 21|2@1+ (1.0,0.0) [0.0|3] ""  Gateway_Max,OCU
 SG_ PSD_Attribut_3_Wert m1  : 21|4@1+ (1,0) [0|15] "Unit_None"  Gateway_Max,OCU
 SG_ PSD_Ges_Typ m2  : 21|2@1+ (1.0,0.0) [0.0|3] ""  Gateway_Max,OCU
 SG_ PSD_Sys_Alter_Karte m0  : 23|3@1+ (1.0,0.0) [0.0|7] ""  Gateway_Max,OCU
 SG_ PSD_Ges_Spur_Geschw_Begrenzung m2  : 23|6@1+ (1.0,0.0) [0.0|63] ""  Gateway_Max,OCU
 SG_ PSD_Steigung_1_B_Steigung m4  : 24|7@1+ (0.12,0) [0.00|15.00] "Unit_PerCent"  Gateway_Max,OCU
 SG_ PSD_Attribut_4_ID m1  : 25|5@1+ (1,0) [1|31] ""  Gateway_Max,OCU
 SG_ PSD_Sys_Zielfuehrung m0  : 26|1@1+ (1.0,0.0) [0.0|1] ""  Gateway_Max,OCU
 SG_ PSD_Sys_US_State m0  : 27|6@1+ (1.0,0.0) [0.0|63] ""  Gateway_Max,OCU
 SG_ PSD_Ges_Geschwindigkeit_Gespann m2  : 29|2@1+ (1.0,0.0) [0.0|3] ""  Gateway_Max,OCU
 SG_ PSD_Baum_Breite_VZ m3  : 29|1@1+ (1.0,0.0) [0.0|1] ""  Gateway_Max,OCU
 SG_ PSD_Attribut_4_Wert m1  : 30|4@1+ (1,0) [0|15] ""  Gateway_Max,OCU
 SG_ PSD_Baum_Breite m3  : 30|24@1+ (0.00001,0) [0.00000|90.00000] "Unit_DegreOfArc"  Gateway_Max,OCU
 SG_ PSD_Ges_Geschwindigkeit_Witter m2  : 31|2@1+ (1.0,0.0) [0.0|3] ""  Gateway_Max,OCU
 SG_ PSD_Steigung_1_B_Vorz m4  : 31|1@1+ (1.0,0.0) [0.0|1] ""  Gateway_Max,OCU
 SG_ PSD_Steigung_1_B_Offset m4  : 32|7@1+ (2,0) [0|254] "Unit_Meter"  Gateway_Max,OCU
 SG_ PSD_Sys_Quali_Geometrien m0  : 33|3@1+ (1,0) [0|7] "Unit_None"  Gateway_Max,OCU
 SG_ PSD_Ges_Geschwindigkeit_Tag_Anf m2  : 33|3@1+ (1.0,0.0) [0.0|7] ""  Gateway_Max,OCU
 SG_ PSD_Attribut_4_Offset m1  : 34|7@1+ (2,0) [0|254] "Unit_Meter"  Gateway_Max,OCU
 SG_ PSD_Sys_Quali_Ortsinfo m0  : 36|2@1+ (1,0) [0|3] "Unit_None"  Gateway_Max,OCU
 SG_ PSD_Ges_Geschwindigkeit_Tag_Ende m2  : 36|3@1+ (1.0,0.0) [0.0|7] ""  Gateway_Max,OCU
 SG_ PSD_Sys_Quali_verfuegbar m0  : 38|1@1+ (1.0,0.0) [0.0|1] ""  Gateway_Max,OCU
 SG_ PSD_Sys_Zielfuehrung_geaendert m0  : 39|1@1+ (1.0,0.0) [0.0|1] ""  Gateway_Max,OCU
 SG_ PSD_Ges_Geschwindigkeit_Std_Anf m2  : 39|5@1+ (1,0) [0|24] "Unit_Hours"  Gateway_Max,OCU
 SG_ PSD_Steigung_1_Attribute_kompl m4  : 39|1@1+ (1.0,0.0) [0.0|1] ""  Gateway_Max,OCU
 SG_ PSD_Sys_Geometrieguete_erweitert m0  : 40|8@1+ (1.0,0.0) [0.0|255] ""  Gateway_Max,OCU
 SG_ PSD_Steigung_2_Segment_ID m4  : 40|6@1+ (1,0) [2|63] ""  Gateway_Max,OCU
 SG_ PSD_Attribut_5_ID m1  : 41|5@1+ (1,0) [1|31] ""  Gateway_Max,OCU
 SG_ PSD_Ges_Geschwindigkeit_Std_Ende m2  : 44|5@1+ (1,0) [0|24] "Unit_Hours"  Gateway_Max,OCU
 SG_ PSD_Attribut_5_Offset m1  : 46|7@1+ (2,0) [0|254] "Unit_Meter"  Gateway_Max,OCU
 SG_ PSD_Steigung_2_Steigung m4  : 46|7@1+ (0.12,0) [0.00|15.00] "Unit_PerCent"  Gateway_Max,OCU
 SG_ PSD_Sys_Quali_sonstige_Attribute m0  : 48|3@1+ (1,0) [0|7] "Unit_None"  Gateway_Max,OCU
 SG_ PSD_Ges_Ueberholverbot m2  : 49|2@1+ (1.0,0.0) [0.0|3] ""  Gateway_Max,OCU
 SG_ PSD_Sys_Quali_Steigungen m0  : 51|3@1+ (1,0) [0|7] ""  Gateway_Max,OCU
 SG_ PSD_Ges_Wechselverkehrszeichen m2  : 51|3@1+ (1.0,0.0) [0.0|7] ""  Gateway_Max,OCU
 SG_ PSD_Attribut_5_Wert m1  : 53|4@1+ (1,0) [0|15] ""  Gateway_Max,OCU
 SG_ PSD_Steigung_2_Vorz m4  : 53|1@1+ (1.0,0.0) [0.0|1] ""  Gateway_Max,OCU
 SG_ PSD_Sys_Quali_Strassenkennz m0  : 54|3@1+ (1,0) [0|7] "Unit_None"  Gateway_Max,OCU
 SG_ PSD_Wechselverkehrszeichen_Typ m2  : 54|2@1+ (1.0,0.0) [0.0|3] ""  Gateway_Max,OCU
 SG_ PSD_Baum_Ausrichtung m3  : 54|10@1+ (0.3515625,0) [0E-7|359.6484375] "Unit_DegreOfArc"  Gateway_Max,OCU
 SG_ PSD_Steigung_2_Offset m4  : 54|7@1+ (2,0) [0|254] "Unit_Meter"  Gateway_Max,OCU
 SG_ PSD_Ges_Gesetzlich_Kategorie m2  : 56|3@1+ (1.0,0.0) [0.0|7] ""  Gateway_Max,OCU
 SG_ PSD_Sys_Quali_Tempolimits m0  : 57|3@1+ (1,0) [0|7] "Unit_None"  Gateway_Max,OCU
 SG_ PSD_Attribute_Komplett_06 m1  : 57|1@1+ (1.0,0.0) [0.0|1] ""  Gateway_Max,OCU
 SG_ PSD_Ges_Gesetzlich_Zusatz m2  : 59|2@1+ (1.0,0.0) [0.0|3] ""  Gateway_Max,OCU
 SG_ PSD_Sys_Quali_Vorfahrtsregelung m0  : 60|3@1+ (1,0) [0|7] "Unit_None"  Gateway_Max,OCU
 SG_ PSD_Ges_Verkehrszeichen_Quelle m2  : 61|2@1+ (1.0,0.0) [0.0|3] ""  Gateway_Max,OCU
 SG_ PSD_Steigung_2_Attribute_kompl m4  : 61|1@1+ (1.0,0.0) [0.0|1] ""  Gateway_Max,OCU
 SG_ PSD_Ges_Attribute_Komplett m2  : 63|1@1+ (1.0,0.0) [0.0|1] ""  Gateway_Max,OCU

BO_ 1125 PSD_LR_01: 8 ZR_MIB_EINSTIEG_ab_Gen3
 SG_ PSD_LR_Profil_Nummer : 0|2@1+ (1,0) [0|3] ""  Gateway_Max
 SG_ PSD_LR_01_MUX M  : 2|2@1+ (1.0,0.0) [0.0|3] ""  Gateway_Max
 SG_ PSD_LR_Profil_Laenge m0  : 4|14@1+ (0.25,0) [0.00|4095.75] "Unit_KiloMeter"  Gateway_Max
 SG_ PSD_LR_Koeffizientensatz_Nr m1  : 4|6@1+ (1,0) [0|63] ""  Gateway_Max
 SG_ PSD_LR_Attribut_1_Offset m2  : 4|12@1+ (0.0244140625,0) [0E-10|99.9755859375] "Unit_PerCent"  Gateway_Max
 SG_ PSD_LR_Steigung_1_Offset m3  : 4|12@1+ (0.0244140625,0) [0E-10|99.9755859375] "Unit_PerCent"  Gateway_Max
 SG_ PSD_LR_Koeff_1_Amp m1  : 10|9@1+ (0.01956947162,0) [0E-11|9.99999999782] "Unit_PerCent"  Gateway_Max
 SG_ PSD_LR_Attribut_1_Wert m2  : 16|8@1+ (1.0,0.0) [0.0|255] ""  Gateway_Max
 SG_ PSD_LR_Steigung_1_Vorz m3  : 16|1@1+ (1.0,0.0) [0.0|1] ""  Gateway_Max
 SG_ PSD_LR_Steigung_1_Wert m3  : 17|7@1+ (0.12,0) [0.00|15.24] "Unit_PerCent"  Gateway_Max
 SG_ PSD_LR_Fahrzeug_Pos m0  : 18|14@1+ (0.006103888,0) [0E-9|99.999997104] "Unit_PerCent"  Gateway_Max
 SG_ PSD_LR_Koeff_1_Phase m1  : 19|9@1+ (0.0122958616,0) [0E-10|6.2831852776] "Unit_DegreOfArc"  Gateway_Max
 SG_ PSD_LR_Attribut_2_Offset m2  : 24|12@1+ (0.0244140625,0) [0E-10|99.9755859375] "Unit_PerCent"  Gateway_Max
 SG_ PSD_LR_Steigung_2_Offset m3  : 24|12@1+ (0.0244140625,0) [0E-10|99.9755859375] "Unit_PerCent"  Gateway_Max
 SG_ PSD_LR_Koeff_2_Amp m1  : 28|9@1+ (0.01956947162,0) [0E-11|9.99999999782] "Unit_PerCent"  Gateway_Max
 SG_ PSD_LR_Globale_Steigung_Vorz m0  : 32|1@1+ (1.0,0.0) [0.0|1] ""  Gateway_Max
 SG_ PSD_LR_Globale_Steigung m0  : 33|19@1+ (0.00002861028406197,0) [0E-17|14.99999999999806539] "Unit_PerCent"  Gateway_Max
 SG_ PSD_LR_Attribut_2_Wert m2  : 36|8@1+ (1.0,0.0) [0.0|255] ""  Gateway_Max
 SG_ PSD_LR_Steigung_2_Vorz m3  : 36|1@1+ (1.0,0.0) [0.0|1] ""  Gateway_Max
 SG_ PSD_LR_Koeff_2_Phase m1  : 37|9@1+ (0.0122958616,0) [0E-10|6.2831852776] "Unit_DegreOfArc"  Gateway_Max
 SG_ PSD_LR_Steigung_2_Wert m3  : 37|7@1+ (0.12,0) [0.00|15.24] "Unit_PerCent"  Gateway_Max
 SG_ PSD_LR_Attribut_3_Offset m2  : 44|12@1+ (0.0244140625,0) [0E-10|99.9755859375] "Unit_PerCent"  Gateway_Max
 SG_ PSD_LR_Steigung_3_Offset m3  : 44|12@1+ (0.0244140625,0) [0E-10|99.9755859375] "Unit_PerCent"  Gateway_Max
 SG_ PSD_LR_Koeff_3_Amp m1  : 46|9@1+ (0.01956947162,0) [0E-11|9.99999999782] "Unit_PerCent"  Gateway_Max
 SG_ PSD_LR_Max_Koeff_Amp m0  : 52|11@1+ (2,0) [0|4094] "Unit_Meter"  Gateway_Max
 SG_ PSD_LR_Koeff_3_Phase m1  : 55|9@1+ (0.0122958616,0) [0E-10|6.2831852776] "Unit_DegreOfArc"  Gateway_Max
 SG_ PSD_LR_Attribut_3_Wert m2  : 56|8@1+ (1.0,0.0) [0.0|255] ""  Gateway_Max
 SG_ PSD_LR_Steigung_3_Vorz m3  : 56|1@1+ (1.0,0.0) [0.0|1] ""  Gateway_Max
 SG_ PSD_LR_Steigung_3_Wert m3  : 57|7@1+ (0.12,0) [0.00|15.24] "Unit_PerCent"  Gateway_Max
 SG_ PSD_LR_Reset m0  : 63|1@1+ (1.0,0.0) [0.0|1] ""  Gateway_Max

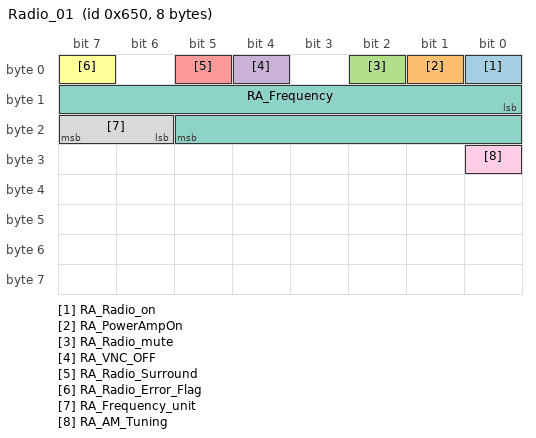
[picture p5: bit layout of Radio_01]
BO_ 1616 Radio_01: 8 Gateway_Max
 SG_ RA_Radio_on : 0|1@1+ (1,0) [0|1] ""  BedienDisp_vo_mi,Gateway_Max,OCU
 SG_ RA_PowerAmpOn : 1|1@1+ (1,0) [0|1] ""  Gateway_Max
 SG_ RA_Radio_mute : 2|1@1+ (1,0) [0|1] ""  Gateway_Max
 SG_ RA_VNC_OFF : 4|1@1+ (1,0) [0|1] ""  Gateway_Max
 SG_ RA_Radio_Surround : 5|1@1+ (1,0) [0|1] ""  Gateway_Max
 SG_ RA_Radio_Error_Flag : 7|1@1+ (1.0,0.0) [0.0|1] ""  Gateway_Max
 SG_ RA_Frequency : 8|14@1+ (1,0) [0|16383] "Unit_None"  Gateway_Max,OCU
 SG_ RA_Frequency_unit : 22|2@1+ (1.0,0.0) [0.0|3] ""  Gateway_Max
 SG_ RA_AM_Tuning : 24|1@1+ (1.0,0.0) [0.0|1] ""  Gateway_Max

BO_TX_BU_ 2600468595 :ICC_IO_Node,ZR_MIB_EINSTIEG_ab_Gen3,ZR_MIB_OPTION_ab_Gen3,ZR_MIB_TOP_ab_Gen3;
BO_TX_BU_ 2550006375 :ConMod_CD,OCU;
BO_TX_BU_ 2550006387 :ZR_MIB_EINSTIEG_ab_Gen3,ZR_MIB_OPTION_ab_Gen3,ZR_MIB_TOP_ab_Gen3;
BO_TX_BU_ 2550034446 :ICC_IO_Node,ZR_MIB_EINSTIEG_ab_Gen3,ZR_MIB_OPTION_ab_Gen3;
BO_TX_BU_ 2550006437 :ZR_MIB_OPTION_ab_Gen3,ZR_MIB_TOP_ab_Gen3;
BO_TX_BU_ 2463978629 :Gateway_Max,OCU;
BO_TX_BU_ 1122 :ZR_MIB_EINSTIEG_ab_Gen3,ZR_MIB_OPTION_ab_Gen3,ZR_MIB_TOP_ab_Gen3;
BO_TX_BU_ 1123 :ZR_MIB_EINSTIEG_ab_Gen3,ZR_MIB_OPTION_ab_Gen3,ZR_MIB_TOP_ab_Gen3;
BO_TX_BU_ 1124 :ZR_MIB_EINSTIEG_ab_Gen3,ZR_MIB_OPTION_ab_Gen3,ZR_MIB_TOP_ab_Gen3;
BO_TX_BU_ 1125 :ZR_MIB_EINSTIEG_ab_Gen3,ZR_MIB_OPTION_ab_Gen3,ZR_MIB_TOP_ab_Gen3;
BO_TX_BU_ 1616 :Gateway_Max,ZR_MIB_EINSTIEG_ab_Gen3,ZR_MIB_OPTION_ab_Gen3,ZR_MIB_TOP_ab_Gen3;
CM_ BO_ 2549940736 "VDC funktionaler Request auf CANHS";
CM_ BO_ 1175 "neue Struktur ab MQB ohne KD-Fehler";
CM_ BO_ 1355 "neue Struktur ab MQB ohne KD-Fehler";

CM_ SG_ 2600468496 NM_Gateway_CAB_V14 "CAB = Clusteraktivbits (V14)

Cluster CAB_01_Antrieb
-Innenraumklimatisierung starten
-Ladevorbedingung, Beginn des Ladens, Ende
-Lademodusänderung, Timer-Laden vs. Sofort Laden

Cluster CAB_02_Hybrid_Laden
-Laden an oder ausschalten
-Ladevorbedi";
CM_ SG_ 2600468496 NM_Gateway_Car_Wakeup "Car Wakeup (Subbusmaster wertet aus)

MQB: 
-Diagnose- oder Komponentenschutzmaster-Funktion weckt den schlafenden Subbus (z.B. MOST)

E3_Volumen:
- Diagnose aktiv -aktive Diagnosekommunikation am OBD-Stecker

MQBw_Baseline:
- Diagnose aktiv -akt";
CM_ SG_ 2600468496 NM_Gateway_CBV_AWB "Das Signal ist zu setzen, wenn das SG aktiv den Bus geweckt hat
0 = Passiver_WakeUp = SG hat das Netzwerk nicht aktiv geweckt
1 = Akitiver_WakeUp = SG hat das Netzwerk aktiv geweckt";
CM_ SG_ 2600468496 NM_Gateway_CBV_CRI "Das Signal ist dauerhaft gesetzt, wenn das NM-Layout Cluster- Anforderungen enthält";
CM_ SG_ 2600468496 NM_Gateway_NM_aktiv_Buskopplung "Nachlauf aufgrund Kopplung zweier Busse. z.B. K-CAN und K2-CAN";
CM_ SG_ 2600468496 NM_Gateway_NM_aktiv_CWU "Nachlauf aufgrund CWU Anforderung";
CM_ SG_ 2600468496 NM_Gateway_NM_aktiv_Diagnose "Diagnose befindet sich nach VW80124 in einer NonDefaultDiagnostic-Session, z.B. ExtendedDiagnostic-Session";
CM_ SG_ 2600468496 NM_Gateway_NM_aktiv_EM "Nachlauf aufgrund Energiemanagement";
CM_ SG_ 2600468496 NM_Gateway_NM_aktiv_FC "Nachlauf aufgrund Funktionscluster Anforderung";
CM_ SG_ 2600468496 NM_Gateway_NM_aktiv_KL15 "Steuergerät hat KL15-EIN erkannt";
CM_ SG_ 2600468496 NM_Gateway_NM_aktiv_Tmin "Mindestaktivzeit ist noch nicht abgelaufen (bei jedem Weckereignis wird die Mindestaktivzeit neu gestartet)";
CM_ SG_ 2600468496 NM_Gateway_NM_State "1 = Zustand Repeat Message (<-- Bus-Sleep Mode)
2 = Zustand Repeat Message (<-- Prepare Bus-Sleep Mode)
4 = Zustand Normal Operation (<-- Repeat Message)
8 = Zustand Normal Operation (<-- Ready Sleep)";
CM_ SG_ 2600468496 NM_Gateway_UDS_CC "Funktionseinschränkung aufgrund aktivem UDS-Communication Control, siehe VW80124";

CM_ SG_ 2600468595 NM_Info_El_CAB_V14 "CAB = Clusteraktivbits (V14)

Cluster - CAB_02_Hybrid
-Ausstiegspanel (Bedienmöglichkeit bei S-Kontakt EIN für maximal 60sec)

Cluster - CAB_03_Fahrwerk
-Ausstiegspanel (Bedienmöglichkeit bei S-Kontakt EIN für maximal 60sec)

Cluster - CAB_04_Fahr";
CM_ SG_ 2600468595 NM_Info_El_Car_Wakeup "Car Wakeup (Gateway wertet aus)

MLBevo:
- Remote Lock/Unlock
- Remote STH

MQB (MIB ab Gen3):
- OCU Download";
CM_ SG_ 2600468595 NM_Info_El_CBV_AWB "Das Signal ist zu setzen, wenn das SG aktiv den Bus geweckt hat
0 = Passiver_WakeUp = SG hat das Netzwerk nicht aktiv geweckt
1 = Akitiver_WakeUp = SG hat das Netzwerk aktiv geweckt";
CM_ SG_ 2600468595 NM_Info_El_CBV_CRI "Das Signal ist dauerhaft gesetzt, wenn das NM-Layout Cluster- Anforderungen enthält";
CM_ SG_ 2600468595 NM_Info_El_NM_aktiv_Applikation "Eine Applikationsanforderung fordert den Bus";
CM_ SG_ 2600468595 NM_Info_El_NM_aktiv_BAP_Comm "MQB:
CAN wird zum Betrieb des BAP CAN Verstärkers wachgehalten";
CM_ SG_ 2600468595 NM_Info_El_NM_aktiv_Diagnose "Diagnose befindet sich nach VW80124 in einer NonDefaultDiagnostic-Session, z.B. ExtendedDiagnostic-Session";
CM_ SG_ 2600468595 NM_Info_El_NM_aktiv_IAA "IAA: Nutzeridentifikation / Management ist aktiv";
CM_ SG_ 2600468595 NM_Info_El_NM_aktiv_KL15 "Steuergerät hat KL15-EIN erkannt";
CM_ SG_ 2600468595 NM_Info_El_NM_aktiv_MIBCAN "MIB-CAN länger als Mindestaktivzeit aktiv für: SWDL, TEL, Radio_On/Hour_Mode, Mute_Mode
TT3: ICAN länger als Mindestaktivzeit aktiv für MFL-Bedienung";
CM_ SG_ 2600468595 NM_Info_El_NM_aktiv_Powerstate "Dieser Bus wird auf Grund eines Powerstates (entsprechend Bus Handling in Power Management StateMachine) wachgehalten";
CM_ SG_ 2600468595 NM_Info_El_NM_aktiv_SmartLight "Aktivität der Smartlight Applikation im SG";
CM_ SG_ 2600468595 NM_Info_El_NM_aktiv_Tmin "Mindestaktivzeit ist noch nicht abgelaufen (bei jedem Weckereignis wird die Mindestaktivzeit neu gestartet)";
CM_ SG_ 2600468595 NM_Info_El_NM_State "1 = Zustand Repeat Message (<-- Bus-Sleep Mode)
2 = Zustand Repeat Message (<-- Prepare Bus-Sleep Mode)
4 = Zustand Normal Operation (<-- Repeat Message)
8 = Zustand Normal Operation (<-- Ready Sleep)";
CM_ SG_ 2600468595 NM_Info_El_UDS_CC "Funktionseinschränkung aufgrund aktivem UDS-Communication Control, siehe VW80124";

CM_ SG_ 2600468644 NM_LSH_CAB_V14 "CAB = Clusteraktivbits (V14)";
CM_ SG_ 2600468644 NM_LSH_Car_Wakeup "Car Wakeup (Gateway wertet aus)
MQB: 
- Luftstandheizung wurde per Funk ein oder ausgeschaltet
- Schwalltopf muss nachgefüllt werden
- neue Programmierung der Funkfernbedienung empfangen
- Luftstandheizung abschalten im Fehlerfall

MQB2020: 
- Luf";
CM_ SG_ 2600468644 NM_LSH_CBV_AWB "Das Signal ist zu setzen, wenn das SG aktiv den Bus geweckt hat";
CM_ SG_ 2600468644 NM_LSH_CBV_CRI "Das Signal ist dauerhaft gesetzt, wenn das NM-Layout dem neuen NM-Layout für Teilnetzbetrieb entspricht";
CM_ SG_ 2600468644 NM_LSH_NM_aktiv_Datentransf_Funk "Datentransfer über Funk (Timer-Umstellung) aktiv";
CM_ SG_ 2600468644 NM_LSH_NM_aktiv_Diagnose "Diagnose befindet sich nach VW80124 in einer NonDefaultDiagnostic-Session, z.B. ExtendedDiagnostic-Session";
CM_ SG_ 2600468644 NM_LSH_NM_aktiv_EIN_AUS_Funk "Funkbefehl LSH einschalten/ausschalten aktiv";
CM_ SG_ 2600468644 NM_LSH_NM_aktiv_KL15 "Steuergerät hat KL15-EIN erkannt";
CM_ SG_ 2600468644 NM_LSH_NM_aktiv_Tmin "Mindestaktivzeit ist noch nicht abgelaufen (bei jedem Weckereignis wird die Mindestaktivzeit neu gestartet)";
CM_ SG_ 2600468644 NM_LSH_NM_State "1 = Zustand Repeat Message (<-- Bus-Sleep Mode)
2 = Zustand Repeat Message (<-- Prepare Bus-Sleep Mode)
4 = Zustand Normal Operation (<-- Repeat Message)
8 = Zustand Normal Operation (<-- Ready Sleep)";
CM_ SG_ 2600468644 NM_LSH_UDS_CC "Funktionseinschränkung aufgrund aktivem UDS-Communication Control; siehe VW80124";

CM_ SG_ 2600468491 NM_RDK_CAB_V14 "CAB = Clusteraktivbits (V14)";
CM_ SG_ 2600468491 NM_RDK_Car_Wakeup "Car Wakeup (Gateway wertet aus)";
CM_ SG_ 2600468491 NM_RDK_CBV_AWB "Das Signal ist zu setzen, wenn das SG aktiv den Bus geweckt hat";
CM_ SG_ 2600468491 NM_RDK_CBV_CRI "Das Signal ist dauerhaft gesetzt, wenn das NM-Layout Cluster- Anforderungen enthält";
CM_ SG_ 2600468491 NM_RDK_NM_aktiv_Diagnose "Diagnose befindet sich nach VW80124 in einer NonDefaultDiagnostic-Session, z.B. ExtendedDiagnostic-Session";
CM_ SG_ 2600468491 NM_RDK_NM_aktiv_KL15 "Steuergerät hat KL15-EIN erkannt";
CM_ SG_ 2600468491 NM_RDK_NM_aktiv_Tmin "Mindestaktivzeit ist noch nicht abgelaufen (bei jedem Weckereignis wird die Mindestaktivzeit neu gestartet)";
CM_ SG_ 2600468491 NM_RDK_NM_State "1 = Zustand Repeat Message (<-- Bus-Sleep Mode)
2 = Zustand Repeat Message (<-- Prepare Bus-Sleep Mode)
4 = Zustand Normal Operation (<-- Repeat Message)
8 = Zustand Normal Operation (<-- Ready Sleep)";
CM_ SG_ 2600468491 NM_RDK_UDS_CC "Funktionseinschränkung aufgrund aktivem UDS-Communication Control, siehe VW80124";

CM_ SG_ 2600468586 NM_STH_CAB_V14 "CAB = Clusteraktivbits (V14)

CAB_01_Antrieb
WSH/LSH - Schwallkopf füllen (Schwallkopf mit Kraftstoff füllen) für 4 sec
WSH - Wasserpumpe ein (Wasserpumpe am Motor einschalten) für 4 sec

CAB_02_Hybrid_Laden
WSH/LSH - Standheizung an/aus (Funkfernb";
CM_ SG_ 2600468586 NM_STH_Car_Wakeup "Car Wakeup (Gateway wertet aus)

MQB: 
-Standheizung wurde per Funk ein oder ausgeschaltet
-Schwalltopf muß nachgefüllt werden
-Gebläse muß ein- oder ausgeschaltet werden
-neue Programmierung der Funkfernbedienung empfangen
-Standheizung abschalten";
CM_ SG_ 2600468586 NM_STH_CBV_AWB "Das Signal ist zu setzen, wenn das SG aktiv den Bus geweckt hat
0 = Passiver_WakeUp = SG hat das Netzwerk nicht aktiv geweckt
1 = Akitiver_WakeUp = SG hat das Netzwerk aktiv geweckt";
CM_ SG_ 2600468586 NM_STH_CBV_CRI "Das Signal ist dauerhaft gesetzt, wenn das NM-Layout Cluster- Anforderungen enthält";
CM_ SG_ 2600468586 NM_STH_NM_aktiv_Datentransf_Funk "Datentransfer über Funk (Timer-Umstellung) aktiv";
CM_ SG_ 2600468586 NM_STH_NM_aktiv_Diagnose "Diagnose befindet sich nach VW80124 in einer NonDefaultDiagnostic-Session, z.B. ExtendedDiagnostic-Session";
CM_ SG_ 2600468586 NM_STH_NM_aktiv_EIN_AUS_Funk "Funkbefehl STH einschalten/ausschalten aktiv";
CM_ SG_ 2600468586 NM_STH_NM_aktiv_EKP_Anf "EKP-Anforderung (Schwalltopf füllen) setzen/zurücknehmen";
CM_ SG_ 2600468586 NM_STH_NM_aktiv_Geblaese_Anf "Anforderung Klima-Gebläse aktiv";
CM_ SG_ 2600468586 NM_STH_NM_aktiv_KL15 "Steuergerät hat KL15-EIN erkannt";
CM_ SG_ 2600468586 NM_STH_NM_aktiv_Tmin "Mindestaktivzeit ist noch nicht abgelaufen (bei jedem Weckereignis wird die Mindestaktivzeit neu gestartet)";
CM_ SG_ 2600468586 NM_STH_NM_aktiv_WaPu_Anf "Wasserpumpe-Anforderung  setzen/zurücknehmen";
CM_ SG_ 2600468586 NM_STH_NM_State "1 = Zustand Repeat Message (<-- Bus-Sleep Mode)
2 = Zustand Repeat Message (<-- Prepare Bus-Sleep Mode)
4 = Zustand Normal Operation (<-- Repeat Message)
8 = Zustand Normal Operation (<-- Ready Sleep)";
CM_ SG_ 2600468586 NM_STH_UDS_CC "Funktionseinschränkung aufgrund aktivem UDS-Communication Control, siehe VW80124";

CM_ SG_ 2589283909 NR_01_CAL_Text_Data_1 "Information regarding the Initial sensor calibration of the NanoRadar in the Plant and Service do be displayed via HMI. Formatted as UTF-8 String, part 1 (Characters 0 to 6)";
CM_ SG_ 2589283909 NR_01_CAL_Text_Request "Triggers the Display via HMI of the characters in the signals  NR_01_CAL_Text_Data_<1 to 3> for the NanoRadar";

CM_ SG_ 2589283910 NR_01_CAL_Text_Data_2 "Information regarding the Initial sensor calibration of the NanoRadar in the Plant and Service do be displayed via HMI. Formatted as UTF-8 String, part 2 (Characters 7 to 14)";

CM_ SG_ 2589283911 NR_01_CAL_Text_Data_3 "Information regarding the Initial sensor calibration of the NanoRadar in the Plant and Service do be displayed via HMI. Formatted as UTF-8 String, part 3 (Characters 15 to 22)";

CM_ SG_ 2589283912 NR_02_CAL_Text_Data_1 "Information regarding the Initial sensor calibration of the NanoRadar in the Plant and Service do be displayed via HMI. Formatted as UTF-8 String, part 1 (Characters 0 to 6)";
CM_ SG_ 2589283912 NR_02_CAL_Text_Request "Triggers the Display via HMI of the characters in the signals  NR_02_CAL_Text_Data_<1 to 3> for the NanoRadar";

CM_ SG_ 2589283913 NR_02_CAL_Text_Data_2 "Information regarding the Initial sensor calibration of the NanoRadar in the Plant and Service do be displayed via HMI. Formatted as UTF-8 String, part 2 (Characters 7 to 14)";

CM_ SG_ 2589283914 NR_02_CAL_Text_Data_3 "Information regarding the Initial sensor calibration of the NanoRadar in the Plant and Service do be displayed via HMI. Formatted as UTF-8 String, part 3 (Characters 15 to 22)";

CM_ SG_ 2589283915 NR_03_CAL_Text_Data_1 "Information regarding the Initial sensor calibration of the NanoRadar in the Plant and Service do be displayed via HMI. Formatted as UTF-8 String, part 1 (Characters 0 to 6)";
CM_ SG_ 2589283915 NR_03_CAL_Text_Request "Triggers the Display via HMI of the characters in the signals  NR_03_CAL_Text_Data_<1 to 3> for the NanoRadar";

CM_ SG_ 2589283916 NR_03_CAL_Text_Data_2 "Information regarding the Initial sensor calibration of the NanoRadar in the Plant and Service do be displayed via HMI. Formatted as UTF-8 String, part 2 (Characters 7 to 14)";

CM_ SG_ 2589283917 NR_03_CAL_Text_Data_3 "Information regarding the Initial sensor calibration of the NanoRadar in the Plant and Service do be displayed via HMI. Formatted as UTF-8 String, part 3 (Characters 15 to 22)";

CM_ SG_ 2589283918 NR_04_CAL_Text_Data_1 "Information regarding the Initial sensor calibration of the NanoRadar in the Plant and Service do be displayed via HMI. Formatted as UTF-8 String, part 1 (Characters 0 to 6)";
CM_ SG_ 2589283918 NR_04_CAL_Text_Request "Triggers the Display via HMI of the characters in the signals  NR_04_CAL_Text_Data_<1 to 3> for the NanoRadar";

CM_ SG_ 2589283919 NR_04_CAL_Text_Data_2 "Information regarding the Initial sensor calibration of the NanoRadar in the Plant and Service do be displayed via HMI. Formatted as UTF-8 String, part 2 (Characters 7 to 14)";

CM_ SG_ 2589283920 NR_04_CAL_Text_Data_3 "Information regarding the Initial sensor calibration of the NanoRadar in the Plant and Service do be displayed via HMI. Formatted as UTF-8 String, part 3 (Characters 15 to 22)";

CM_ SG_ 2589284036 NR_05_CAL_Text_Data_1 "Information regarding the Initial sensor calibration of the NanoRadar in the Plant and Service do be displayed via HMI. Formatted as UTF-8 String, part 1 (Characters 0 to 6)";
CM_ SG_ 2589284036 NR_05_CAL_Text_Request "Triggers the Display via HMI of the characters in the signals  NR_05_CAL_Text_Data_<1 to 3> for the NanoRadar";

CM_ SG_ 2589284037 NR_05_CAL_Text_Data_2 "Information regarding the Initial sensor calibration of the NanoRadar in the Plant and Service do be displayed via HMI. Formatted as UTF-8 String, part 2 (Characters 7 to 14)";

CM_ SG_ 2589284038 NR_05_CAL_Text_Data_3 "Information regarding the Initial sensor calibration of the NanoRadar in the Plant and Service do be displayed via HMI. Formatted as UTF-8 String, part 3 (Characters 15 to 22)";

CM_ SG_ 2589284039 NR_06_CAL_Text_Data_1 "Information regarding the Initial sensor calibration of the NanoRadar in the Plant and Service do be displayed via HMI. Formatted as UTF-8 String, part 1 (Characters 0 to 6)";
CM_ SG_ 2589284039 NR_06_CAL_Text_Request "Triggers the Display via HMI of the characters in the signals  NR_06_CAL_Text_Data_<1 to 3> for the NanoRadar";

CM_ SG_ 2589284040 NR_06_CAL_Text_Data_2 "Information regarding the Initial sensor calibration of the NanoRadar in the Plant and Service do be displayed via HMI. Formatted as UTF-8 String, part 2 (Characters 7 to 14)";

CM_ SG_ 2589284041 NR_06_CAL_Text_Data_3 "Information regarding the Initial sensor calibration of the NanoRadar in the Plant and Service do be displayed via HMI. Formatted as UTF-8 String, part 3 (Characters 15 to 22)";

CM_ SG_ 913 MO_QBit_Aussen_Temp "QBit der Aussentemperatur. Gesetzt bei Ersatzwert, Init oder Fehler.";
CM_ SG_ 913 MO_Servicemodus "Ausgabe aktiver Service-Mode";
CM_ SG_ 913 OBD_Abs_Load_Val "Absolute Load Value

Übertragung von Meßgrößen an das Getriebesteuergerät für Freeze Frame Abspeicherung bei Getriebefehlern

PID $43 Absolute Load Value; 0 .. 25700%  mit 100/255 %/bit";
CM_ SG_ 913 OBD_Abs_Pedal_Pos "Absolute Pedal Position

Übertragung von Meßgrößen an das Getriebesteuergerät für Freeze Frame Abspeicherung bei Getriebefehlern

PID $49 Accelerator Pedal Position D; 0 .. 100% mit 100/255 %/bit";
CM_ SG_ 913 OBD_Abs_Throttle_Pos "Absolute Throttle Position

Übertragung von Meßgrößen an das Getriebesteuergerät für Freeze Frame Abspeicherung bei Getriebefehlern

PID $11 Absolute Throttle Position; 0 .. 100% mit 100/255 %/bit";
CM_ SG_ 913 OBD_Calc_Load_Val "Calculated Load Value

Übertragung von Meßgrößen an das Getriebesteuergerät für Freeze Frame Abspeicherung bei Getriebefehlern

PID $04 Calculated Load Value; 0 .. 100% mit 100/255 % per bit
";
CM_ SG_ 913 OBD_ClearMem_Inhibit "Bei FSP_Loeschen_zulässig müssen alle OBD-ECUs im Gesamtfahrzeug einen Service 04hex Request (Ereignisspeicher löschen) korrekt ausführen. 

In MLB-, MLBevo-, MQB-Fahrzeugkonzepten muss der MIL-Master/Motorsteuergerät bei Kl.15 ein, projektabhängig, kon";
CM_ SG_ 913 OBD_Driving_Cycle "Signalisierung Driving Cycle Qualifizierung - Trigger Ignition Cycle Counter";
CM_ SG_ 913 OBD_Eng_Cool_Temp "Engine Coolant Temperature

Übertragung von Meßgrößen an das Getriebesteuergerät für Freeze Frame Abspeicherung bei Getriebefehlern

PID $05 Engine Coolant Temperature; -40 .. +215°C mit 1°C/bit und 40°C Offset";
CM_ SG_ 913 OBD_Kaltstart_Denominator "Bestimmte Diagnosen werden nur unter Kaltstartbedingungen durchgeführt, der entsprechende Denominator bei IUMPR-pflichtigen Systemen wird anhand dieses vom MSG gebildeten Signals inkrementiert. (Entspricht EVAP-Denominator)";
CM_ SG_ 913 OBD_Minimum_Trip "Grundlage OBD-Gesetz CCR 1968.2 (d)(4.3) Denominator Specifications
Bildung des General Denominator 'Normed Trip':
 600 sec. (kumulativ) Zeit nach Motorstart
 300 sec. (kumulativ) mit Fahrzeuggeschwindigkeit > 25 mph (40 km/h)
 30 sec. (kontinuierlich";
CM_ SG_ 913 OBD_Normed_Trip "Gesetzlich definierte 'Normed Condition' erfüllt, 'General Denominator' darf erhöht werden";
CM_ SG_ 913 OBD_Sperrung_IUMPR "Wenn der General Denominator auf Grund eines Fehlers in den Eingangsgrößen gesperrt wird, wird diese Information über Bussystem als OBD-Statusinformation OBD_Sperrung_IUMPR für andere OBD-Steuergeräte bereitgestellt. 

Das MSG (MIL-Master) setzt dieses ";
CM_ SG_ 913 OBD_Sperrung_Kaltstart_Denom "Information vom MIL Master, dass die Bildung des EVAP Denominators  im Motor nicht möglich ist und damit der noECM-Denominator gesperrt werden darf.";
CM_ SG_ 913 OBD_Warm_Up_Cycle "Mit dem Warm-Up-Cycle wird der zentrale Verlernzähler vom Gateway inkrementiert";

CM_ SG_ 2550399540 OBDC_BedienDisp_m_Req_Data "TP-Kanal für den Onboard Datensammler";

CM_ SG_ 2550530612 OBDC_BedienDisp_m_Resp_Data "TP-Kanal für den Onboard Datensammler";

CM_ SG_ 2549940736 OBDC_Funktionaler_Req_All_Data "VDC funktionaler Request auf CANHS";

CM_ SG_ 2549875364 OBDC_LSH_Req_Data "Onboard Diagnose";

CM_ SG_ 2550006436 OBDC_LSH_Resp_Data "Onboard Diagnose";

CM_ SG_ 2549903374 OBDC_SSN_ABT_1_Req_Data "Request FID- zu NA- Kommunikation zw. OnboardDiagnoseClient und DK2F Sub-System-Knoten ABT_1";

CM_ SG_ 2550034446 OBDC_SSN_ABT_1_Resp_Data "Response FID- zu NA- Kommunikation zw. OnboardDiagnoseClient und DK2F Sub-System-Knoten ABT_1";

CM_ SG_ 2549875365 OBDC_WLC1_Req_Data "OBDC Strecke für WLC1 - Req Kanal";

CM_ SG_ 2550006437 OBDC_WLC1_Resp_Data "OBDC Strecke für WLC1 - Resp Kanal";

CM_ SG_ 28 OCU_WFS_Anfrage_CRC "OCU_WFS_Anfrage_CRC";
CM_ SG_ 28 OCU_WFS_Anfrage_Status "OCU_WFS_Anfrage_Status";
CM_ SG_ 28 OCU_WFS_Anfrage_Typ "OCU_WFS_Anfrage_Typ";

CM_ SG_ 2589283656 ORU_Status "Verteilung des internen ORU Zustandes";
CM_ SG_ 2589283656 ORU_Warnung "Wenn durch Störungen der Funktion Online Remote Update nicht sichergestellt ist, dass vor Kunde keine Funktionseinschränkungen auftreten, muss der Benutzer des Fahrzeugs entsprechend gewarnt werden.";

CM_ SG_ 2549909095 ORU_eCall_Req_Data "ORU Datenerhebung via ISO-TP";

CM_ SG_ 2550040167 ORU_eCall_Resp_Data "ORU Datenerhebung via ISO-TP";

CM_ SG_ 1175 PDC_Tonausgabe_Front "In Abhängigkeit der Systemaktivitäten werden unterschiedliche Tonwarnungen ausgegeben. 
Kombi spielt entsprechende WAV.-Datei über internen Audiomaster ab.

0 = kein Ton
1 = Intervallton 1
2 = Intervallton 2
3 = Intervallton 3
4 = Intervallton 4
5";
CM_ SG_ 1175 PDC_Tonausgabe_Heck "In Abhängigkeit der Systemaktivitäten werden unterschiedliche Tonwarnungen ausgegeben. 
Kombi spielt entsprechende WAV.-Datei über internen Audiomaster ab.

0 = kein Ton
1 = Intervallton 1
2 = Intervallton 2
3 = Intervallton 3
4 = Intervallton 4
5";
CM_ SG_ 1175 PH_Abschaltursache "Abschaltursache bleibt bis zur nächsten Aktivierung bzw. bis KL15 aus gesetzt
Im Fehlerfall (blinkende LED) wird '7' gesendet obwohl das System noch aktiv ist, bei 'geheiltem' Fehler wird sofort wieder der Zustand '0' gesendet";
CM_ SG_ 1175 PH_Anf_Audioabsenkung "Es gibt zwei unterschiedliche Nachlauftimer für dieses Bit:
1. normale Funktion
2. Demotonausgabe";
CM_ SG_ 1175 PH_Anf_Verdeck "Anforderung an ein Verdeck-System, die vom Fahrer angeforderte Öffnung/Schließung zu verhindern";
CM_ SG_ 1175 PH_defekt "Zeigt an das sich die Parkhilfe im Fehlerzustand befindet. Signal bleibt bis zur nächsten 'Gut-Aktivierung' gesetzt.
Spezialfall: Sensordefekt hinten bei Anhängerbetrieb. Anhänger wird abgesteckt Fehler wird gesetzt. Fehlerfall bleibt bis Behebung des De";
CM_ SG_ 1175 PH_Display_Kundenwunsch "Anzeige der bei Aktivierung verwendeten Parameter bzgl. Kundenwunsch Displayanziege. Änderungen werden erst bei erneuter Aktivierung aktualisiert.";
CM_ SG_ 1175 PH_Frequenz_hinten "Uebertragung der aktuell im APS Steuergeraet gespeicherten Werte fuer Tongeber Frequenz hinten
Anzeige der aktuell verwendeten Parameter (nicht zwingend die abgespeicherten - da Werte erst 2s nach der letzten Änderung gespeichert werden!)";
CM_ SG_ 1175 PH_Frequenz_vorn "Uebertragung der aktuell im APS Steuergeraet gespeicherten Werte fuer Tongeber Frequenz vorne
Anzeige der aktuell verwendeten Parameter (nicht zwingend die abgespeicherten - da Werte erst 2s nach der letzten Änderung gespeichert werden!)";
CM_ SG_ 1175 PH_gestoert "Eine Störung ist aufgetreten, der die Parkhilfe in einen 'gestört-Zustand' versetzt, z.B. massiver Fremdultraschall, Vereisung, Schnee.Derzeit nur für Störschall benutzt, da keinerlei andere Erkennung implementiert.";
CM_ SG_ 1175 PH_Lautstaerke_hinten "Uebertragung der aktuell im APS Steuergeraet gespeicherten Werte fuer Tongeber Lautstaerke hinten
Anzeige der aktuell verwendeten Parameter (nicht zwingend die abgespeicherten - da Werte erst 2s nach der letzten Änderung gespeichert werden!)";
CM_ SG_ 1175 PH_Lautstaerke_vorn "Uebertragung der aktuell im APS Steuergeraet gespeicherten Werte fuer Tongeber Lautstaerke vorn.
Anzeige der aktuell verwendeten Parameter (nicht zwingend die abgespeicherten - da Werte erst 2s nach der letzten Änderung gespeichert werden!)";
CM_ SG_ 1175 PH_nachtr_Stopp_Anf "Dieses Signal dient dem Motor als Trigger, dass ein nachträglicher Motorstopp eingeleitet werden kann, wenn es die Bedingungen des StSt Koordinators dies zulassen. ";
CM_ SG_ 1175 PH_Opt_Anz_H_Hindernis "mindestens 1 Segment wird für den hinteren Detekionsbereich dargestellt, also ein Hindernis ist im Detektionsbereich. Funktion nur bei gesicherter Rückmeldung vom ASG gegeben.";
CM_ SG_ 1175 PH_Opt_Anz_V_Hindernis "mindestens 1 Segment wird für den vorderen Detekionsbereich dargestellt, also ein Hindernis ist im Detektionsbereich. Funktion nur bei gesicherter Rückmeldung vom ASG gegeben.";
CM_ SG_ 1175 PH_Opt_Anzeige_H_ein "OPS hinten ist im Display aktiv bzw. Anzeigemodule hinten sind eingeschaltet. Funktion nur bei gesicherter Rückmeldung vom ASG gegeben.";
CM_ SG_ 1175 PH_Opt_Anzeige_V_ein "OPS vorne ist im Display aktiv bzw. Anzeigemodule vorne sind eingeschaltet. Funktion nur bei gesicherter Rückmeldung vom ASG gegeben.";
CM_ SG_ 1175 PH_StartStopp_Info "Stopp-Freigabe und Start-Anforderung an den Start-Stopp-Koordinator";
CM_ SG_ 1175 PH_Stoermeldung "Meldung einer Störung der PDC an das Kombi";
CM_ SG_ 1175 PH_Systemzustand "Aktivierungsursache wird für die Dauer der Aktivierung gemeldet.
Im Fehlerfall bei atkviem System wechselt das Signal auf '7'
(siehe auch 'Abschaltursache')";
CM_ SG_ 1175 PH_Taster "Taster Status (für RVC/TopView)";
CM_ SG_ 1175 PH_Tongeber_H_aktiv "Rohsignal für 'Tongeber hinten wird angesteuert', verlängerbar mit Nachlauftimer.
Bit wird nicht während des Stellgliedtests angesteuert.";
CM_ SG_ 1175 PH_Tongeber_H_verfuegbar "Tongeber ist für die Tonausgabe für externe Funktionen verfügbar. PDC ist aktiv und Tongeber ist nicht gestört.";
CM_ SG_ 1175 PH_Tongeber_mute "Die Akustikausgabe des Systems wird unterdrückt, z.B. Wählhebel in 'P', Parlbremse geschlossen (8-Kanal-System)";
CM_ SG_ 1175 PH_Tongeber_V_aktiv "Rohsignal für 'Tongeber vorne wird angesteuert', verlängerbar mit Nachlauftimer.
Bit wird nicht während des Stellgliedtests angesteuert.";
CM_ SG_ 1175 PH_Visualisierung "Signal zeigt den Partnersteuergeräten RearView/TopView/ARA/... den aktuellen Status der Visualisierung des OPS. Die Partnersteuergeräte können dadurch auch ihre Aufschaltung an dieses Signal koppeln.";
CM_ SG_ 1175 PLA_Anf_Aufschaltung_RVC "Anforderung der Aufschaltung RVC durch PLA";

CM_ SG_ 1355 APS_PaCo_WarningTones "Signalisierung, ob seitens der Kundenfunktion APS eine akustische Warntonausgabe möglich ist.

0 Not_Possible: Akustische Tonausgabe derzeit nicht möglich
1 Possible: Akustische Tonausgabe derzeit möglich";
CM_ SG_ 1355 APSOPS_PaCo_ApproachingFront "Signalisierung einer Annäherung an ein kritisches Hindernis im vorderen Fahrzeugbereich.

0 No_Obstacle_Approaching: APSOPS erkennt kein Hindernis vor dem Fahrzeug
1 Obstacle_Approaching: APSOPS erkennt ein Hindernis vor dem Fahrzeug";
CM_ SG_ 1355 APSOPS_PaCo_ApproachingRear "Signalisierung einer Annäherung an ein kritisches Hindernis im hinteren Fahrzeugbereich.

0 No_Obstacle_Approaching: APSOPS erkennt kein Hindernis hinter dem Fahrzeug
1 Obstacle_Approaching: APSOPS erkennt ein Hindernis hinter dem Fahrzeug";
CM_ SG_ 1355 APSOPS_PaCo_Button "Signalisierung eines gedrückten PDC-Hardkeys.

0 Init_Or_Not_Equipped: Init oder kein PDC-Hardkey vorhanden
1 Button_Not_Pressed: PDC-Hardkey ist nicht gedrückt
2 Button_Pressed_Debounced: PDC-Hardkey ist gedrückt (entprellt)
3 Error: Fehler";
CM_ SG_ 1355 APSOPS_PaCo_FunctionState "Signalisierung des Funktionszustandes von APSOPS.

0 No_Error: es liegt kein Fehler von APSOPS vor
1 Sensor_Defect: es liegt ein Fehler aufgrund eines Sensordefekts von APSOPS vor, der über Teilverfügbarkeit abgehandelt warden kann
2 Sensor_Contaminat";
CM_ SG_ 1355 APSOPS_PaCo_MainState "Hauptzustand der Kundenfunktion APSOPS.

0 Init: APSOPS befindet sich in der Initialisierung
1 InOperation_NoError: APSOPS befindet sich im Betrieb ohne Fehler
7 Fehler: APSOPS befindet sich im Fehlerzustand";
CM_ SG_ 1355 APSOPS_PaCo_ObstacleDetectFront "Signalisierung, wenn im vorderen Fahrzeugbereich Hindernisse detektiert werden. Der vordere Fahrzeugbereich umfasst alle Hindernisse vor dem Fahrzeug bis zur Fahrzeugmitte und damit auch die beiden vorderen seitlichen Sektoren. Es wird immer der Signalzus";
CM_ SG_ 1355 APSOPS_PaCo_ObstacleDetectRear "Signalisierung, wenn im hinteren Fahrzeugbereich Hindernisse detektiert werden. Der hintere Fahrzeugbereich umfasst alle Hindernisse hinter dem Fahrzeug bis zur Fahrzeugmitte und damit auch die beiden hinteren seitlichen Sektoren. Es wird immer der Signal";
CM_ SG_ 1355 PH_Aufschaltursache "Der Grund für die Aufschaltung der Einparkhilfe wird angegeben, z.B. bei der Aktivierung der Einparkhilfe durch eine andere Funktion, wird diese Funktion als Aktivierungsursache für die Dauer der Aktivierung gemeldet.
Das Signal wird den PH_Systemzustand";
CM_ SG_ 1355 PH_Ton_Ausgabe "Anforderung einer Tonausgabe beim MIB3 durch die Parkhilfe";
CM_ SG_ 1355 PH_Ton_Lautstaerke "Wunschlautstärke der Tonanforderung beim MIB3 durch die Parkhilfe.";
CM_ SG_ 1355 PH_Ton_Pausenlaenge "Pause zwischen den angeforderten Tönen beim MIB3 durch die Parkhilfe. Nur für Intervalltöne, nicht relevant für Dauerton und Quittierungston.";
CM_ SG_ 1355 PH_Ton_Richtung "Abspielrichtung des angeforderten Ton beim MIB3 durch die Parkhilfe";
CM_ SG_ 1355 PH_Verschmutzungsmeldung "Meldung einer Verschmutzung/Vereisung der PDC an das Kombi";
CM_ SG_ 1355 PH_WAH_Meldung "Steuert die HMI-Meldungen im Kombi für den Wiederanfahrhinweis";
CM_ SG_ 1355 RAB_PaCo_FunctionState "Signalisierung des Funktionszustandes des RA";
CM_ SG_ 1355 RBF_Anf_Meldungen "Über das Signal werden die RBF Meldungen von der Funktion RBF am Kombi angefordert. Ursprünglich waren die Meldungen in der PLA_Status_02 Botschaft. Da RBF auch nur mit PDC einsetzt wird ein neuse  Signal benötigt.";
CM_ SG_ 1355 RBF_PaCo_Anf_Meldungen "Über das Signal werden die RBF Meldungen von der Funktion RBF über den PaCo beim Infotainment bzw. Kombi angefordert.";
CM_ SG_ 1355 RBF_PMO_Bereich_erkannt "Dieses Signal gibt zentralisiert eine Auswertung  des RBF relevanten PMO Bereichs wieder, sodass Systempartner Verhalten anpassen können, die ein gesondertes PMO Verhalten abbilden sollen";
CM_ SG_ 1355 RBFMA_PaCo_BrakeIntervention "Signalisierung, ob die Kundenfunktion RBF/MA einen Bremseingriff ansteuert.

0 Inactive: RBF/MA steuert derzeit keinen Bremseingriff an
1 Active_Rear: RBF/MA steuert derzeit einen Bremseingriff aufgrund eines Hindernisses hinten an
2 Active_Front: RBF";
CM_ SG_ 1355 RBFMA_PaCo_MainState "Hauptzustand der Kundenfunktion RBF/MA

0 Init: RBF/MA befindet sich in der Initialisierung
1 InOperation_NoError: RBF/MA befindet sich im Betrieb ohne Fehler
2 Eingeschraenkt
7 Fehler: RBF/MA befindet sich im Fehlerzustand";

CM_ SG_ 2527679498 IAA_Active_User_ID "Signal gibt die IAA Nutzer ID des aktiven IAA Nutzers an.";
CM_ SG_ 2527679498 IAA_Identified_User_ID "Signal gibt die IAA Nutzer ID des vom BCM identifizierten IAA Nutzers an";
CM_ SG_ 2527679498 IAA_PSO_wake_up "Signal zum Wake_up der IAA und PSO Komponenten im Kombi und in der OCU";
CM_ SG_ 2527679498 Perso_Aktiv "Status Personalisierung für den Fahrer aktiviert/ deaktiviert (via HMI)";
CM_ SG_ 2527679498 Perso_Bedienstelle "Signal zeigt an, über welche Bedienstelle die Umschaltung des Benutzerkontos gestartet wurden.";
CM_ SG_ 2527679498 Perso_Fahrernummer "Signal gibt die jewels aktuelle Nummer des Fahrers für die Personalisierung an.
Nicht für AU736 und AU48x.";
CM_ SG_ 2527679498 Perso_Freigabe_Verstellung "Signal zeigt an, ob die Ergonomiefunktionen nach Umschaltung des Benutzerkontos verfahren dürfen.";
CM_ SG_ 2527679498 Perso_Kontonummer "Signal gibt die jewels aktuelle Kontonummer für die Personalisierung an.
Nicht für AU736 und AU48x.";
CM_ SG_ 2527679498 Perso_Schreibschutz "Signal zeigt an, ob der Schreibschutz der Personalisierung aktiv ist.";
CM_ SG_ 2527679498 Perso_Status "Codierstatus der Personalisierung
Nicht für AU736 und AU49x.";
CM_ SG_ 2527679498 Perso_Steuerung "Signal gibt einen Steuerungsbefehl an die Funktionsteilnehmer der Personalisierung.
Nicht für AU736 und AU49x.";
CM_ SG_ 2527679498 Perso_Steuerungsparameter "Signal gibt einen Parameter zum Steuerungsbefehl (Signal Perso_Steuerung) für die Personalisierung an.
Nicht für AU736 und AU49x.";

CM_ SG_ 2463978629 IAA_Active_User_ID_02 "Signal gibt die IAA Nutzer ID des aktiven IAA Nutzers an.";
CM_ SG_ 2463978629 IAA_Identified_User_ID_02 "Signal gibt die IAA Nutzer ID des vom BCM identifizierten IAA Nutzers an";
CM_ SG_ 2463978629 Perso_Aktiv_02 "Status Personalisierung für den Fahrer aktiviert/ deaktiviert (via HMI)";
CM_ SG_ 2463978629 Perso_Bedienstelle_02 "Signal zeigt an, über welche Bedienstelle die Umschaltung des Benutzerkontos gestartet wurden.";
CM_ SG_ 2463978629 Perso_Fahrernummer_02 "Signal gibt die jewels aktuelle Nummer des Fahrers für die Personalisierung an.
Nicht für AU736 und AU48x.";
CM_ SG_ 2463978629 Perso_Freigabe_Verstellung_02 "Signal zeigt an, ob die Ergonomiefunktionen nach Umschaltung des Benutzerkontos verfahren dürfen.";
CM_ SG_ 2463978629 Perso_Kontonummer_02 "Signal gibt die jewels aktuelle Kontonummer für die Personalisierung an.
Nicht für AU736 und AU48x.";
CM_ SG_ 2463978629 Perso_Schreibschutz_02 "Signal zeigt an, ob der Schreibschutz der Personalisierung aktiv ist.";
CM_ SG_ 2463978629 Perso_Status_02 "Codierstatus der Personalisierung
Nicht für AU736 und AU49x.";
CM_ SG_ 2463978629 Perso_Steuerung_02 "Signal gibt einen Steuerungsbefehl an die Funktionsteilnehmer der Personalisierung.
Nicht für AU736 und AU49x.";
CM_ SG_ 2463978629 Perso_Steuerungsparameter_02 "Signal gibt einen Parameter zum Steuerungsbefehl (Signal Perso_Steuerung) für die Personalisierung an.
Nicht für AU736 und AU49x.";

CM_ SG_ 319 PreCrash_Anforderung_AFR "Anforderungen der Funktion PrecrashSeite an Fahrwerksregelung";
CM_ SG_ 319 PreCrash_BFS_KSV_verfahren "Ansteuerung der Kopfstuetze Beifahrerseite durch die Funktion PreCrash

Signalwert 0x09 für vereinfachte Ansteuerung mit Logik im Sitz-SG (MQB37W)";
CM_ SG_ 319 PreCrash_BFS_Laengsverstellung "Ansteuerung der Laengsverstellung des Beifahrersitzes durch die PreCrash-Funktionen";
CM_ SG_ 319 PreCrash_BFS_Pneumatik_ansteuern "Ansteuerung des Beifahrersitzes durch die PreCrash-Funktionen";
CM_ SG_ 319 PreCrash_BFS_Sitzlehne_verfahren "Ansteuerung des Beifahrersitzes durch die PreCrash-Funktionen

Wert 0x06 und 0x07 für vereinfachte Ansteuerung Sitzlehne";
CM_ SG_ 319 PreCrash_Blinken "Safety Computer übermittelt Blinkverhalten bei einer PreCrash-Auslösung an den BCM2";
CM_ SG_ 319 PreCrash_Charisma_FahrPr "Aktuell eingestelltes Fahrprogramm der Funktion PreCrash";
CM_ SG_ 319 PreCrash_Charisma_Status "Verfügbarkeit der Funktion PreCrash für die Ansteuerung durch den Charisma_Koordinator";
CM_ SG_ 319 PreCrash_Fenster_schliessen "Anforderung Seitenscheiben schließen durch die Funktion PreCrash";
CM_ SG_ 319 PreCrash_Fo_KSV_verfahren "Ansteuerung der Kopfstuetzen im Fond durch die PreCrash-Funktionen";
CM_ SG_ 319 PreCrash_Fo_Pneumatik_ansteuern "Ansteuerung der Fondsitze durch die PreCrash-Funktionen";
CM_ SG_ 319 PreCrash_Fo_Sitzlehne_verfahren "Ansteuerung des Fondsitzes durch die PreCrash-Funktionen";
CM_ SG_ 319 PreCrash_FS_KSV_verfahren "Ansteuerung der Kopfstuetze Fahrerseite durch die PreCrash-Funktionen

Signalwert 0x09 für vereinfachte Ansteuerung mit Logik im Sitz-SG (MQB37W)";
CM_ SG_ 319 PreCrash_FS_Laengsverstellung "Ansteuerung der Laengsverstellung des Fahrersitzes durch die PreCrash-Funktionen";
CM_ SG_ 319 PreCrash_FS_Pneumatik_ansteuern "Ansteuerung des Fahrersitzes durch die PreCrash-Funktionen";
CM_ SG_ 319 PreCrash_FS_Sitzlehne_verfahren "Ansteuerung des Fahrersitzes durch die PreCrash-Funktionen

Wert 0x06 und 0x07 für vereinfachte Ansteuerung Sitzlehne";
CM_ SG_ 319 PreCrash_Schiebedach_schliessen "Anforderung Schiebedach schließen durch die Funktion PreCrash";
CM_ SG_ 319 PreCrash_Tueren_Verriegeln "Anforderung Türen Verriegeln durch die Funktion PreCrash";
CM_ SG_ 319 SC_PreCrash_LED "Ansteuerung LED-Leiste im Kombi durch SC";
CM_ SG_ 319 SC_PreCrash_Texte "Safety Computer übermittelt Systemstatus der PreCrash Funktionen an Kombi";
CM_ SG_ 319 SC_PreCrash_Warnung "Safety Computer übermittelt Warnung der PreCrash Funktionen an Kombi";
CM_ SG_ 319 SC_PreSense_FCWP "Mitteilung an das NightVision, auf welche Art von Objekt eine Warnung angefordert wird";

CM_ SG_ 1122 PSD_Abzweigerichtung "Richtung, in der die Abzweigung von der Hauptroute abzweigt
";
CM_ SG_ 1122 PSD_Abzweigewinkel "Winkel, unter dem die Abzweigung von der Hauptroute abzweigt.
";
CM_ SG_ 1122 PSD_ADAS_Qualitaet "ADAS Qualtität des Streckensegments.";
CM_ SG_ 1122 PSD_Anfangskruemmung "Startkrümmung der Klothoide des übermittelten abzweigenden Streckensegments. 
1/(1+0.155 * x^2) {1/m}'
";
CM_ SG_ 1122 PSD_Anfangskruemmung_Vorz "Vorzeichen für die Startkrümmung bei Abzweigungen
";
CM_ SG_ 1122 PSD_Bebauung "Segement befindet sich innerhalb bebauten Gebietes";
CM_ SG_ 1122 PSD_Endkruemmung "'Endkrümmung der Klotoide des übermittelten Streckensegments. Die Anfangskrümmung des folgenden Streckensegments entspricht der Endkrümmung dieses Segments. Krümmung = 1/(1+0.155 * x²) [1/m]

";
CM_ SG_ 1122 PSD_Fahrspuren_Anzahl "Anzahl der Fahrspuren in Fahrtrichtung
";
CM_ SG_ 1122 PSD_Geradester_Pfad "Segment ist Teil des geradesten Pfades";
CM_ SG_ 1122 PSD_Idenditaets_ID "Identifier auf ein Streckensegment, dass mit dem aktuell übertragenen geometrisch identisch ist.";
CM_ SG_ 1122 PSD_Segment_ID "Identifier des prädiktiven Streckensegments
";
CM_ SG_ 1122 PSD_Segment_Komplett "Zeigt, ob alle Attribute für das Segment übertragen worden sind
";
CM_ SG_ 1122 PSD_Segmentlaenge "Gesamtlänge des prädiktiven Streckensegments";
CM_ SG_ 1122 PSD_Strassenkategorie "Klassifizierung der Straße des beschriebenen Segments
";
CM_ SG_ 1122 PSD_Vorgaenger_Segment_ID "An dem Streckensegment mit diesem Identifier schließt sich das neue Segment mit der ID 'PSD_01_Segment_ID' an.
";
CM_ SG_ 1122 PSD_wahrscheinlichster_Pfad "Identifiziert den vom Navigationssystem berechneten wahrscheinlichsten Pfad des Fahrzeuges. ";

CM_ SG_ 1123 PSD_Attribut_1_ID "Identifier des ersten Attributes";
CM_ SG_ 1123 PSD_Attribut_1_Offset "Positionsoffset im Segment für die Position des Attributs";
CM_ SG_ 1123 PSD_Attribut_1_Wert "Wert des ersten Attributes";
CM_ SG_ 1123 PSD_Attribut_2_ID "Identifier des zweiten Attributes";
CM_ SG_ 1123 PSD_Attribut_2_Offset "Positionsoffset im Segment für die Position des Attributs";
CM_ SG_ 1123 PSD_Attribut_2_Wert "Wert des zweiten Attributes";
CM_ SG_ 1123 PSD_Attribut_Segment_ID_05 "Identifier des Streckensegments, für das die weiteren Attribute in der Botschaft gültig sind";
CM_ SG_ 1123 PSD_Attribute_Komplett_05 "Zeigt, ob alle Attribute für das Segment übertragen worden sind";
CM_ SG_ 1123 PSD_Pos_Fahrspur "Spur, auf der sich das Fahrzeug aktuell befindet";
CM_ SG_ 1123 PSD_Pos_Fehler_Laengsrichtung "Laengsfehler der Positionierung";
CM_ SG_ 1123 PSD_Pos_Inhibitzeit "Zeitspanne zwischen Generierung der PSD Daten im Navigationssystem und Versand der Daten auf den Most
";
CM_ SG_ 1123 PSD_Pos_Segment_ID "Identifier des Streckensegments, auf dem sich das Fahrzeug aktuell befindet
";
CM_ SG_ 1123 PSD_Pos_Segmentlaenge "Verbleibende Länge des Streckensegments, auf dem sich das Fahrzeug aktuell befindet
";
CM_ SG_ 1123 PSD_Pos_Standort_Eindeutig "Ist die Position des Fahrzeugs eindeutig dem aktuelle Segment zugeordnet, oder gibt es fahrbare alternative Segmente, die bei akteller GPS-Position ebenfalls als aktuelles Segment möglich wären.";

CM_ SG_ 1124 PSD_06_Mux "Multiplex Zähler für die PSD_06-Botschaft.
Die unterschiedlichen Muxe folgen keiner festen Reihenfolge. Je nach Inhalt des PSD-Protokolls an der aktuellen Position werden jeweils die notwendigen PSD6-Botschaften gesendet.";
CM_ SG_ 1124 PSD_Attribut_3_ID "Identifier des dritten Attributes";
CM_ SG_ 1124 PSD_Attribut_3_Offset "Positionsoffset im Segment für die Position des Attributs";
CM_ SG_ 1124 PSD_Attribut_3_Wert "Wert des dritten Attributes";
CM_ SG_ 1124 PSD_Attribut_4_ID "Typ von Attribut 4";
CM_ SG_ 1124 PSD_Attribut_4_Offset "Offset von Attribut 4";
CM_ SG_ 1124 PSD_Attribut_4_Wert "Wert von Attribut 4";
CM_ SG_ 1124 PSD_Attribut_5_ID "Typ von Attribut 5";
CM_ SG_ 1124 PSD_Attribut_5_Offset "Offset von Attribut 5";
CM_ SG_ 1124 PSD_Attribut_5_Wert "Wert von Attribut 5";
CM_ SG_ 1124 PSD_Attribut_Segment_ID "Identifier des Streckensegments,für das die weiteren Attribute in der Botschaft gültig sind";
CM_ SG_ 1124 PSD_Attribute_Komplett_06 "Zeigt, ob alle Attribute für das Segment übertragen worden sind
";
CM_ SG_ 1124 PSD_Baum_Ausrichtung "Ausrichtung des Fahrzeugsegments zu Nord";
CM_ SG_ 1124 PSD_Baum_Breite "WGS84 Breite des Fahrzeugsegments";
CM_ SG_ 1124 PSD_Baum_Breite_VZ "Vorzeichen WGS84 Breite des Fahrzeugsegments";
CM_ SG_ 1124 PSD_Baum_Laenge "WGS84 Laenge des Fahrzeugsegments";
CM_ SG_ 1124 PSD_Baum_Laenge_VZ "Vorzeichen WGS84 Laenge des Fahrzeugsegments";
CM_ SG_ 1124 PSD_Ges_Attribute_Komplett "Zeigt, ob alle Attribute für das Segment übertragen worden sind";
CM_ SG_ 1124 PSD_Ges_Geschwindigkeit_Gespann "Gilt diese Einschränkung der Geschwindigkeit für alle Fahrzeuge oder ausschließlich für PKW mit Gespann oder für LKW, Buss, etc.";
CM_ SG_ 1124 PSD_Ges_Geschwindigkeit_Std_Anf "Stunde, zu der die stündliche Geschwindigkeitsbegrenzung beginnt
0h.. 24h";
CM_ SG_ 1124 PSD_Ges_Geschwindigkeit_Std_Ende "Stunde, an der die stündliche Geschwindigkeitsbegrenzung endet
0h.. 24h";
CM_ SG_ 1124 PSD_Ges_Geschwindigkeit_Tag_Anf "Wochentag, an dem die tägliche Geschwindigkeitsbegrenzung beginnt";
CM_ SG_ 1124 PSD_Ges_Geschwindigkeit_Tag_Ende "Wochentag, an dem die tägliche Geschwindigkeitsbegrenzung endet";
CM_ SG_ 1124 PSD_Ges_Geschwindigkeit_Witter "Witterungsabhängigkeit der Geschwindigkeitsbegrenzung";
CM_ SG_ 1124 PSD_Ges_Gesetzlich_Kategorie "Kategorie für das legale Gebot";
CM_ SG_ 1124 PSD_Ges_Gesetzlich_Zusatz "Zusatz für das legale Gebot";
CM_ SG_ 1124 PSD_Ges_Offset "Positionsoffset im Segment für die Position des Attributs";
CM_ SG_ 1124 PSD_Ges_Segment_ID "Identifier des prädiktiven Streckensegments ab dem die Geschwindigkeitsbegrenzungen und mögliche Einschränkungen gelten.
";
CM_ SG_ 1124 PSD_Ges_Spur_Geschw_Begrenzung "Definition der Spuren, für die das übertragene Gebot gilt";
CM_ SG_ 1124 PSD_Ges_Typ "Typ der Geschwindigkeitsbegrenzung
";
CM_ SG_ 1124 PSD_Ges_Verkehrszeichen_Quelle "Quelle der Verkehrszeicheninformation";
CM_ SG_ 1124 PSD_Ges_Wechselverkehrszeichen "Am Beginn des Segments ist ein Wechselverkehrszeichen angebracht.";
CM_ SG_ 1124 PSD_Steigung_1_A_Offset "Positionsoffset im Segment für die Position der Steigung 1 A";
CM_ SG_ 1124 PSD_Steigung_1_A_Steigung "Steigung des Segments ab Offset 1A";
CM_ SG_ 1124 PSD_Steigung_1_A_Vorz "Vorzeichen für Steigung 1 A";
CM_ SG_ 1124 PSD_Steigung_1_Attribute_kompl "Alle Steigungsdaten für dieses Segment gesendet";
CM_ SG_ 1124 PSD_Steigung_1_B_Offset "Positionsoffset im Segment für die Position der Steigung 1 B";
CM_ SG_ 1124 PSD_Steigung_1_B_Steigung "Steigung des Segments ab Offset 1B";
CM_ SG_ 1124 PSD_Steigung_1_B_Vorz "Vorzeichen für Steigung 1 B";
CM_ SG_ 1124 PSD_Steigung_1_Segment_ID "Identifier des prädiktiven Streckensegments, zu dem die  ersten beiden Steigungswerte dieser Botschaft gehören";
CM_ SG_ 1124 PSD_Steigung_2_Attribute_kompl "Alle Steigungsdaten für dieses Segment gesendet";
CM_ SG_ 1124 PSD_Steigung_2_Offset "Positionsoffset im Segment für die Position der Steigung 2";
CM_ SG_ 1124 PSD_Steigung_2_Segment_ID "Identifier des prädiktiven Streckensegments, zu dem der dritte Steigungswert dieser Botschaft gehört";
CM_ SG_ 1124 PSD_Steigung_2_Steigung "Steigung des Segments ab Offset 2";
CM_ SG_ 1124 PSD_Steigung_2_Vorz "Vorzeichen für Steigung 2";
CM_ SG_ 1124 PSD_Sys_Alter_Karte "Alter der Karte";
CM_ SG_ 1124 PSD_Sys_Geometrieguete "Maß für die Güte der Klothoidengeometrie.";
CM_ SG_ 1124 PSD_Sys_Geometrieguete_erweitert "Güte der Kurvenrepräsentation der Klothoiden";
CM_ SG_ 1124 PSD_Sys_Geschwindigkeit_Einheit "Unterscheidung zwischen km/h und miles/h";
CM_ SG_ 1124 PSD_Sys_Laendercode "Ländercode";
CM_ SG_ 1124 PSD_Sys_Mapmatchingguete "Güte des Mapmatchings";
CM_ SG_ 1124 PSD_Sys_Quali_Geometrien "Qualität der Geometrien in dieser Region";
CM_ SG_ 1124 PSD_Sys_Quali_Ortsinfo "Qualität Ortsinformationen (Bebauung, Ortsschild) dieser Region";
CM_ SG_ 1124 PSD_Sys_Quali_sonstige_Attribute "Qualität sonstiger Attribute dieser Region";
CM_ SG_ 1124 PSD_Sys_Quali_Steigungen "Qualität der Steigungen dieser Region";
CM_ SG_ 1124 PSD_Sys_Quali_Strassenkennz "Qualität Straßenkennzeichnungen dieser Region";
CM_ SG_ 1124 PSD_Sys_Quali_Tempolimits "Qualität Tempolimits dieser Region";
CM_ SG_ 1124 PSD_Sys_Quali_verfuegbar "Karte enthält gültige Qualitätskriterien";
CM_ SG_ 1124 PSD_Sys_Quali_Vorfahrtsregelung "Qualität Vorfahrtsregelungen dieser Region";
CM_ SG_ 1124 PSD_Sys_Segment_ID "Identifier des prädiktiven Streckensegments ab dem die Systeminformationen gültig sind.
";
CM_ SG_ 1124 PSD_Sys_US_State "Name des USA-State";
CM_ SG_ 1124 PSD_Sys_Verkehrsrichtung "Unterscheidung zwischen Linksverkehr und Rechtsverkehr";
CM_ SG_ 1124 PSD_Sys_Zielfuehrung "Zielfuehrung im Navigationssystem. Damit lässt sich der wahrscheinlichste Pfad des Fahrzeuges zuverlässig angeben.";
CM_ SG_ 1124 PSD_Sys_Zielfuehrung_geaendert "Die Zielführung (Route) hat sich geändert hat ohne dass der Fahrer eine neue Zielführung gestartet hat";
CM_ SG_ 1124 PSD_Wechselverkehrszeichen_Typ "Typ des Wechselverkehrszeichen";

CM_ SG_ 1125 PSD_LR_01_MUX "Fehlende Beschreibung (Import)";
CM_ SG_ 1125 PSD_LR_Attribut_1_Offset "Relative Position für Attribut 1 im Profil.
Signal wird nur bei aktiver PSD-Funktion zyklisch gesendet.";
CM_ SG_ 1125 PSD_LR_Attribut_1_Wert "Wert von Attribut 1 (Definition siehe PSD Spec)
Signal wird nur bei aktiver PSD-Funktion zyklisch gesendet.";
CM_ SG_ 1125 PSD_LR_Attribut_2_Offset "Relative Position für Attribut 2 im Profil
Signal wird nur bei aktiver PSD-Funktion zyklisch gesendet.";
CM_ SG_ 1125 PSD_LR_Attribut_2_Wert "Wert von Attribut 2 (Definition siehe PSD Spec)
Signal wird nur bei aktiver PSD-Funktion zyklisch gesendet.";
CM_ SG_ 1125 PSD_LR_Attribut_3_Offset "Relative Position für Attribut 3 im Profil
Signal wird nur bei aktiver PSD-Funktion zyklisch gesendet.";
CM_ SG_ 1125 PSD_LR_Attribut_3_Wert "Wert von Attribut 3 (Definition siehe PSD Spec)
Signal wird nur bei aktiver PSD-Funktion zyklisch gesendet.";
CM_ SG_ 1125 PSD_LR_Fahrzeug_Pos "Position des Fahrzeug in % relativ zur Gesamtlaenge des Profils.
Signal wird nur bei aktiver PSD-Funktion zyklisch gesendet.";
CM_ SG_ 1125 PSD_LR_Globale_Steigung "Gesamtsteigung der in diesem  Profil übertragenen Strecke.
Signal wird nur bei aktiver PSD-Funktion zyklisch gesendet.";
CM_ SG_ 1125 PSD_LR_Globale_Steigung_Vorz "Vorzeichen für globale Steigung des Profils.
Signal wird nur bei aktiver PSD-Funktion zyklisch gesendet.";
CM_ SG_ 1125 PSD_LR_Koeff_1_Amp "Fehlende Beschreibung (Import)";
CM_ SG_ 1125 PSD_LR_Koeff_1_Phase "Phasenwert des ersten FFT-Koeffizienten.
Signal wird nur bei aktiver PSD-Funktion zyklisch gesendet.";
CM_ SG_ 1125 PSD_LR_Koeff_2_Amp "Fehlende Beschreibung (Import)";
CM_ SG_ 1125 PSD_LR_Koeff_2_Phase "Phasenwert des zweiten FFT-Koeffizienten.
Signal wird nur bei aktiver PSD-Funktion zyklisch gesendet.";
CM_ SG_ 1125 PSD_LR_Koeff_3_Amp "Fehlende Beschreibung (Import)";
CM_ SG_ 1125 PSD_LR_Koeff_3_Phase "Phasenwert des dritten FFT-Koeffizienten.
Signal wird nur bei aktiver PSD-Funktion zyklisch gesendet.";
CM_ SG_ 1125 PSD_LR_Koeffizientensatz_Nr "Nummer des aktuell übertragenen Koeffizientansatzes.
Signal wird nur bei aktiver PSD-Funktion zyklisch gesendet.";
CM_ SG_ 1125 PSD_LR_Max_Koeff_Amp "Maximale Höhe der übertragenen Amplitudenwerte.
Signal wird nur bei aktiver PSD-Funktion zyklisch gesendet.";
CM_ SG_ 1125 PSD_LR_Profil_Laenge "Gesamtlänge des übertragenen Profils.
Signal wird nur bei aktiver PSD-Funktion zyklisch gesendet.";
CM_ SG_ 1125 PSD_LR_Profil_Nummer "Nummer des aktuell übertragenen Profils";
CM_ SG_ 1125 PSD_LR_Reset "Reset-Signal, wenn der PSD-LR-Baum ungültig wird.
Signal wird nur bei aktiver PSD-Funktion zyklisch gesendet.";
CM_ SG_ 1125 PSD_LR_Steigung_1_Offset "Relative Position für die Steigung 1 im Profil.
Signal wird nur bei aktiver PSD-Funktion zyklisch gesendet.";
CM_ SG_ 1125 PSD_LR_Steigung_1_Vorz "Vorzeichen für Steigung 1.
Signal wird nur bei aktiver PSD-Funktion zyklisch gesendet.";
CM_ SG_ 1125 PSD_LR_Steigung_1_Wert "Mittlere Steigung zwischen dem Offset 1 und dem letzten Steigungswert.
Signal wird nur bei aktiver PSD-Funktion zyklisch gesendet.";
CM_ SG_ 1125 PSD_LR_Steigung_2_Offset "Relative Position für die Steigung 2 im Profil.
Signal wird nur bei aktiver PSD-Funktion zyklisch gesendet.";
CM_ SG_ 1125 PSD_LR_Steigung_2_Vorz "Vorzeichen für Steigung 2.
Signal wird nur bei aktiver PSD-Funktion zyklisch gesendet.";
CM_ SG_ 1125 PSD_LR_Steigung_2_Wert "Mittlere Steigung zwischen dem Offset 2 und dem letzten Steigungswert.
Signal wird nur bei aktiver PSD-Funktion zyklisch gesendet.";
CM_ SG_ 1125 PSD_LR_Steigung_3_Offset "Relative Position für die Steigung 3 im Profil.
Signal wird nur bei aktiver PSD-Funktion zyklisch gesendet.";
CM_ SG_ 1125 PSD_LR_Steigung_3_Vorz "Vorzeichen für Steigung 3.
Signal wird nur bei aktiver PSD-Funktion zyklisch gesendet.";
CM_ SG_ 1125 PSD_LR_Steigung_3_Wert "Mittlere Steigung zwischen dem Offset 3 und dem letzten Steigungswert.
Signal wird nur bei aktiver PSD-Funktion zyklisch gesendet.";

CM_ SG_ 1616 RA_AM_Tuning "Das Signal kennzeichnet einen aktiven AM Suchlauf. Während des Suchlaufes wird die Frequenz = 0 übertragen.
0 = frequency locked => Störquelle vermeidet die aktuelle Frequenz
1 = AM tuning in progress => Störquelle abschalten bzw.PWM Signal auf DC umsch";
CM_ SG_ 1616 RA_Frequency "Übermittlung der eingestellten Sendefrequenz AM oder FM, diese wird mit RA_Frequency_unit multipliziert.
Im DAB oder Hybrid/Online Mode wird die aktuelle FM-Alternativfrequenz oder, falls nicht vorhanden, die zuletzt gehörte Senderfrequenz übertragen (AM";
CM_ SG_ 1616 RA_Frequency_unit "Faktor für RA_Frequency
bei AM: Faktor 0 = 1kHz
sonst   Faktor 1 = 100kHz";
CM_ SG_ 1616 RA_PowerAmpOn "1 = Request for Amplifier; 0 = Amplifier mute/off";
CM_ SG_ 1616 RA_Radio_Error_Flag "1 = mindestens ein Kundendienstfehlerspeicher Eintrag vorhanden";
CM_ SG_ 1616 RA_Radio_mute "1=Radio is muted for telephone";
CM_ SG_ 1616 RA_Radio_on "1 = user perceived On";
CM_ SG_ 1616 RA_Radio_Surround "1 = Surround ON; 0 = Surround OFF
requests the Amp to switch Surroundmode";
CM_ SG_ 1616 RA_VNC_OFF "VNC = Vehicle Noice Cancellation;
1 = VNC OFF; 0 = VNC ON
requests the Amp to switch VNC off";
BA_DEF_REL_ BU_SG_REL_  "GenSigTimeoutTime" INT 0 65535;
BA_DEF_ BO_  "DiagRequest" ENUM "No", "Yes";
BA_DEF_ BO_  "DiagResponse" ENUM "No", "Yes";
BA_DEF_ BO_  "DiagState" ENUM "No", "Yes";
BA_DEF_ BO_  "GenMsgChkConstant" HEX 0 4095;
BA_DEF_ BO_  "GenMsgCycleTime" INT 0 65535;
BA_DEF_ BO_  "GenMsgCycleTimeFast" INT 0 65535;
BA_DEF_ BO_  "GenMsgDelayTime" INT 0 100000;
BA_DEF_ BO_  "GenMsgILSupport" ENUM "No", "Yes";
BA_DEF_ BO_  "GenMsgNrOfRepetition" INT 0 100;
BA_DEF_ BO_  "GenMsgPDUConstants" STRING;
BA_DEF_ BO_  "GenMsgSendType" ENUM "Cyclic", "not_used", "not_used", "not_used", "not_used", "not_used", "not_used", "IfActive", "NoMsgSendType";
BA_DEF_ BO_  "GenMsgStartDelayTime" INT 0 100000;
BA_DEF_ BO_  "NmMessage" ENUM "No", "Yes";
BA_DEF_ BO_  "NmhMessage" ENUM "No", "Yes";
BA_DEF_ BO_  "MsgType" ENUM "Application", "NM ", "NMH", "TP2.0", "ISO-TP ", "BAP", "EID", "KS", "XCP_PRE_CONFIGURED", "XCP_RUNTIME_CONFIGURED";
BA_DEF_ BO_  "VAGTP20_API" HEX 0 255;
BA_DEF_ BO_  "VAGTP20_DynConnection" ENUM "No", "Yes";
BA_DEF_ BO_  "VAGTP20_DynSetup" ENUM "No", "Yes";
BA_DEF_ BO_  "VAGTP20_StatConnection" ENUM "No", "Yes";
BA_DEF_ SG_  "GenSigActiveRepetitions" INT -2147483648 2147483647;
BA_DEF_ SG_  "GenSigInactiveValue" INT -2147483648 2147483647;
BA_DEF_ SG_  "GenSigSendType" ENUM "Cyclic", "OnWrite", "OnWriteWithRepetition", "OnChange", "OnChangeWithRepetition", "IfActive", "IfActiveWithRepetition", "NoSigSendType", "OnChangeAndIfActive", "OnChangeAndIfActiveWithRepetition";
BA_DEF_ SG_  "GenSigStartValue" INT -2147483648 2147483647;
BA_DEF_ SG_  "NWM-WakeupAllowed" ENUM "No", "Yes";
BA_DEF_ SG_  "GenSigFuncType" ENUM "NoFunction", "MsgCounter", "CRC-8", "XOR", "XOR-2", "DatedBit", "SW-Kl15", "CHK", "Constant", "Protocol", "CRC-8-SAE_J1850", "CRC-32", "DataLength", "DataID", "MsgCounter16", "SOK-Signatur", "Cluster";
BA_DEF_ SG_  "GenSigSwitchedByIgnition" ENUM "No", "Yes";
BA_DEF_ SG_  "Fehlerwert" HEX 0 2147483647;
BA_DEF_ SG_  "GenSigMissingSourceValue" HEX 0 2147483647;
BA_DEF_DEF_REL_  "GenSigTimeoutTime" 0;
BA_DEF_DEF_  "DiagRequest" "No";
BA_DEF_DEF_  "DiagResponse" "No";
BA_DEF_DEF_  "DiagState" "No";
BA_DEF_DEF_  "GenMsgChkConstant" 0;
BA_DEF_DEF_  "GenMsgCycleTime" 0;
BA_DEF_DEF_  "GenMsgCycleTimeFast" 0;
BA_DEF_DEF_  "GenMsgDelayTime" 0;
BA_DEF_DEF_  "GenMsgILSupport" "No";
BA_DEF_DEF_  "GenMsgNrOfRepetition" 0;
BA_DEF_DEF_  "GenMsgPDUConstants" "";
BA_DEF_DEF_  "GenMsgSendType" "NoMsgSendType";
BA_DEF_DEF_  "GenMsgStartDelayTime" 0;
BA_DEF_DEF_  "NmMessage" "No";
BA_DEF_DEF_  "NmhMessage" "No";
BA_DEF_DEF_  "MsgType" "Application";
BA_DEF_DEF_  "VAGTP20_API" 0;
BA_DEF_DEF_  "VAGTP20_DynConnection" "No";
BA_DEF_DEF_  "VAGTP20_DynSetup" "No";
BA_DEF_DEF_  "VAGTP20_StatConnection" "No";
BA_DEF_DEF_  "GenSigActiveRepetitions" 0;
BA_DEF_DEF_  "GenSigInactiveValue" 0;
BA_DEF_DEF_  "GenSigSendType" "NoSigSendType";
BA_DEF_DEF_  "GenSigStartValue" 0;
BA_DEF_DEF_  "NWM-WakeupAllowed" "No";
BA_DEF_DEF_  "GenSigFuncType" "NoFunction";
BA_DEF_DEF_  "GenSigSwitchedByIgnition" "Yes";
BA_DEF_DEF_  "Fehlerwert" 0;
BA_DEF_DEF_  "GenSigMissingSourceValue" 0;
BA_ "GenMsgCycleTime" BO_ 2600468496 200;
BA_ "GenMsgCycleTimeFast" BO_ 2600468496 10;
BA_ "NmhMessage" BO_ 2600468496 1;
BA_ "MsgType" BO_ 2600468496 2;
BA_ "GenMsgCycleTime" BO_ 2600468595 200;
BA_ "GenMsgCycleTimeFast" BO_ 2600468595 10;
BA_ "NmhMessage" BO_ 2600468595 1;
BA_ "MsgType" BO_ 2600468595 2;
BA_ "GenMsgCycleTime" BO_ 2600468644 200;
BA_ "GenMsgCycleTimeFast" BO_ 2600468644 10;
BA_ "NmhMessage" BO_ 2600468644 1;
BA_ "MsgType" BO_ 2600468644 2;
BA_ "GenMsgCycleTime" BO_ 2600468491 200;
BA_ "GenMsgCycleTimeFast" BO_ 2600468491 10;
BA_ "NmhMessage" BO_ 2600468491 1;
BA_ "MsgType" BO_ 2600468491 2;
BA_ "GenMsgCycleTime" BO_ 2600468586 200;
BA_ "GenMsgCycleTimeFast" BO_ 2600468586 10;
BA_ "NmhMessage" BO_ 2600468586 1;
BA_ "MsgType" BO_ 2600468586 2;
BA_ "GenMsgCycleTime" BO_ 2589283909 1000;
BA_ "GenMsgDelayTime" BO_ 2589283909 200;
BA_ "GenMsgILSupport" BO_ 2589283909 1;
BA_ "GenMsgSendType" BO_ 2589283909 0;
BA_ "GenMsgCycleTime" BO_ 2589283910 1000;
BA_ "GenMsgDelayTime" BO_ 2589283910 200;
BA_ "GenMsgILSupport" BO_ 2589283910 1;
BA_ "GenMsgSendType" BO_ 2589283910 0;
BA_ "GenMsgCycleTime" BO_ 2589283911 1000;
BA_ "GenMsgDelayTime" BO_ 2589283911 200;
BA_ "GenMsgILSupport" BO_ 2589283911 1;
BA_ "GenMsgSendType" BO_ 2589283911 0;
BA_ "GenMsgCycleTime" BO_ 2589283912 1000;
BA_ "GenMsgDelayTime" BO_ 2589283912 200;
BA_ "GenMsgILSupport" BO_ 2589283912 1;
BA_ "GenMsgSendType" BO_ 2589283912 0;
BA_ "GenMsgCycleTime" BO_ 2589283913 1000;
BA_ "GenMsgDelayTime" BO_ 2589283913 200;
BA_ "GenMsgILSupport" BO_ 2589283913 1;
BA_ "GenMsgSendType" BO_ 2589283913 0;
BA_ "GenMsgCycleTime" BO_ 2589283914 1000;
BA_ "GenMsgDelayTime" BO_ 2589283914 200;
BA_ "GenMsgILSupport" BO_ 2589283914 1;
BA_ "GenMsgSendType" BO_ 2589283914 0;
BA_ "GenMsgCycleTime" BO_ 2589283915 1000;
BA_ "GenMsgDelayTime" BO_ 2589283915 200;
BA_ "GenMsgILSupport" BO_ 2589283915 1;
BA_ "GenMsgSendType" BO_ 2589283915 0;
BA_ "GenMsgCycleTime" BO_ 2589283916 1000;
BA_ "GenMsgDelayTime" BO_ 2589283916 200;
BA_ "GenMsgILSupport" BO_ 2589283916 1;
BA_ "GenMsgSendType" BO_ 2589283916 0;
BA_ "GenMsgCycleTime" BO_ 2589283917 1000;
BA_ "GenMsgDelayTime" BO_ 2589283917 200;
BA_ "GenMsgILSupport" BO_ 2589283917 1;
BA_ "GenMsgSendType" BO_ 2589283917 0;
BA_ "GenMsgCycleTime" BO_ 2589283918 1000;
BA_ "GenMsgDelayTime" BO_ 2589283918 200;
BA_ "GenMsgILSupport" BO_ 2589283918 1;
BA_ "GenMsgSendType" BO_ 2589283918 0;
BA_ "GenMsgCycleTime" BO_ 2589283919 1000;
BA_ "GenMsgDelayTime" BO_ 2589283919 200;
BA_ "GenMsgILSupport" BO_ 2589283919 1;
BA_ "GenMsgSendType" BO_ 2589283919 0;
BA_ "GenMsgCycleTime" BO_ 2589283920 1000;
BA_ "GenMsgDelayTime" BO_ 2589283920 200;
BA_ "GenMsgILSupport" BO_ 2589283920 1;
BA_ "GenMsgSendType" BO_ 2589283920 0;
BA_ "GenMsgCycleTime" BO_ 2589284036 1000;
BA_ "GenMsgDelayTime" BO_ 2589284036 200;
BA_ "GenMsgILSupport" BO_ 2589284036 1;
BA_ "GenMsgSendType" BO_ 2589284036 0;
BA_ "GenMsgCycleTime" BO_ 2589284037 1000;
BA_ "GenMsgDelayTime" BO_ 2589284037 200;
BA_ "GenMsgILSupport" BO_ 2589284037 1;
BA_ "GenMsgSendType" BO_ 2589284037 0;
BA_ "GenMsgCycleTime" BO_ 2589284038 1000;
BA_ "GenMsgDelayTime" BO_ 2589284038 200;
BA_ "GenMsgILSupport" BO_ 2589284038 1;
BA_ "GenMsgSendType" BO_ 2589284038 0;
BA_ "GenMsgCycleTime" BO_ 2589284039 1000;
BA_ "GenMsgDelayTime" BO_ 2589284039 200;
BA_ "GenMsgILSupport" BO_ 2589284039 1;
BA_ "GenMsgSendType" BO_ 2589284039 0;
BA_ "GenMsgCycleTime" BO_ 2589284040 1000;
BA_ "GenMsgDelayTime" BO_ 2589284040 200;
BA_ "GenMsgILSupport" BO_ 2589284040 1;
BA_ "GenMsgSendType" BO_ 2589284040 0;
BA_ "GenMsgCycleTime" BO_ 2589284041 1000;
BA_ "GenMsgDelayTime" BO_ 2589284041 200;
BA_ "GenMsgILSupport" BO_ 2589284041 1;
BA_ "GenMsgSendType" BO_ 2589284041 0;
BA_ "GenMsgCycleTime" BO_ 913 100;
BA_ "GenMsgILSupport" BO_ 913 1;
BA_ "GenMsgSendType" BO_ 913 0;
BA_ "DiagRequest" BO_ 2550399540 1;
BA_ "MsgType" BO_ 2550399540 4;
BA_ "DiagResponse" BO_ 2550530612 1;
BA_ "MsgType" BO_ 2550530612 4;
BA_ "DiagRequest" BO_ 2549875362 1;
BA_ "MsgType" BO_ 2549875362 4;
BA_ "DiagResponse" BO_ 2550006434 1;
BA_ "MsgType" BO_ 2550006434 4;
BA_ "DiagRequest" BO_ 2549875303 1;
BA_ "MsgType" BO_ 2549875303 4;
BA_ "DiagResponse" BO_ 2550006375 1;
BA_ "MsgType" BO_ 2550006375 4;
BA_ "DiagState" BO_ 2549940736 1;
BA_ "MsgType" BO_ 2549940736 4;
BA_ "DiagRequest" BO_ 2549875315 1;
BA_ "MsgType" BO_ 2549875315 4;
BA_ "DiagResponse" BO_ 2550006387 1;
BA_ "MsgType" BO_ 2550006387 4;
BA_ "DiagRequest" BO_ 2549875364 1;
BA_ "MsgType" BO_ 2549875364 4;
BA_ "DiagResponse" BO_ 2550006436 1;
BA_ "MsgType" BO_ 2550006436 4;
BA_ "DiagRequest" BO_ 2549875211 1;
BA_ "MsgType" BO_ 2549875211 4;
BA_ "DiagResponse" BO_ 2550006283 1;
BA_ "MsgType" BO_ 2550006283 4;
BA_ "DiagRequest" BO_ 2549903374 1;
BA_ "MsgType" BO_ 2549903374 4;
BA_ "DiagResponse" BO_ 2550034446 1;
BA_ "MsgType" BO_ 2550034446 4;
BA_ "DiagRequest" BO_ 2549875306 1;
BA_ "MsgType" BO_ 2549875306 4;
BA_ "DiagResponse" BO_ 2550006378 1;
BA_ "MsgType" BO_ 2550006378 4;
BA_ "DiagRequest" BO_ 2549875309 1;
BA_ "MsgType" BO_ 2549875309 4;
BA_ "DiagResponse" BO_ 2550006381 1;
BA_ "MsgType" BO_ 2550006381 4;
BA_ "DiagRequest" BO_ 2549875365 1;
BA_ "MsgType" BO_ 2549875365 4;
BA_ "DiagResponse" BO_ 2550006437 1;
BA_ "MsgType" BO_ 2550006437 4;
BA_ "GenMsgCycleTime" BO_ 2589283656 500;
BA_ "GenMsgDelayTime" BO_ 2589283656 100;
BA_ "GenMsgILSupport" BO_ 2589283656 1;
BA_ "GenMsgSendType" BO_ 2589283656 0;
BA_ "MsgType" BO_ 2549909095 4;
BA_ "MsgType" BO_ 2550040167 4;
BA_ "GenMsgCycleTime" BO_ 1175 100;
BA_ "GenMsgDelayTime" BO_ 1175 50;
BA_ "GenMsgILSupport" BO_ 1175 1;
BA_ "GenMsgSendType" BO_ 1175 0;
BA_ "GenMsgCycleTime" BO_ 1355 500;
BA_ "GenMsgDelayTime" BO_ 1355 20;
BA_ "GenMsgILSupport" BO_ 1355 1;
BA_ "GenMsgSendType" BO_ 1355 0;
BA_ "GenMsgCycleTime" BO_ 2527679498 1000;
BA_ "GenMsgCycleTimeFast" BO_ 2527679498 200;
BA_ "GenMsgDelayTime" BO_ 2527679498 50;
BA_ "GenMsgILSupport" BO_ 2527679498 1;
BA_ "GenMsgNrOfRepetition" BO_ 2527679498 3;
BA_ "GenMsgSendType" BO_ 2527679498 0;
BA_ "GenMsgCycleTime" BO_ 2463978629 1000;
BA_ "GenMsgCycleTimeFast" BO_ 2463978629 200;
BA_ "GenMsgDelayTime" BO_ 2463978629 50;
BA_ "GenMsgILSupport" BO_ 2463978629 1;
BA_ "GenMsgNrOfRepetition" BO_ 2463978629 3;
BA_ "GenMsgSendType" BO_ 2463978629 0;
BA_ "GenMsgCycleTime" BO_ 319 200;
BA_ "GenMsgDelayTime" BO_ 319 20;
BA_ "GenMsgILSupport" BO_ 319 1;
BA_ "GenMsgPDUConstants" BO_ 319 "0x28,0x6e,0x5a,0xc6,0x52,0x65,0x85,0xa1,0xb8,0xe6,0x38,0x88,0xf8,0xb9,0x2b,0xb0";
BA_ "GenMsgSendType" BO_ 319 0;
BA_ "GenMsgCycleTime" BO_ 1122 150;
BA_ "GenMsgILSupport" BO_ 1122 1;
BA_ "GenMsgSendType" BO_ 1122 0;
BA_ "GenMsgCycleTime" BO_ 1123 150;
BA_ "GenMsgILSupport" BO_ 1123 1;
BA_ "GenMsgSendType" BO_ 1123 0;
BA_ "GenMsgCycleTime" BO_ 1124 150;
BA_ "GenMsgILSupport" BO_ 1124 1;
BA_ "GenMsgSendType" BO_ 1124 0;
BA_ "GenMsgCycleTime" BO_ 1125 450;
BA_ "GenMsgILSupport" BO_ 1125 1;
BA_ "GenMsgSendType" BO_ 1125 0;
BA_ "GenMsgCycleTime" BO_ 1616 1000;
BA_ "GenMsgDelayTime" BO_ 1616 50;
BA_ "GenMsgILSupport" BO_ 1616 1;
BA_ "GenMsgSendType" BO_ 1616 0;
BA_ "GenSigFuncType" SG_ 2600468496 NM_Gateway_CAB_V14 16;
BA_ "GenSigSwitchedByIgnition" SG_ 2600468496 NM_Gateway_CAB_V14 0;
BA_ "GenSigSwitchedByIgnition" SG_ 2600468496 NM_Gateway_Car_Wakeup 0;
BA_ "GenSigSwitchedByIgnition" SG_ 2600468496 NM_Gateway_CBV_AWB 0;
BA_ "GenSigSwitchedByIgnition" SG_ 2600468496 NM_Gateway_CBV_CRI 0;
BA_ "GenSigSwitchedByIgnition" SG_ 2600468496 NM_Gateway_NM_aktiv_Buskopplung 0;
BA_ "GenSigSwitchedByIgnition" SG_ 2600468496 NM_Gateway_NM_aktiv_CWU 0;
BA_ "GenSigSwitchedByIgnition" SG_ 2600468496 NM_Gateway_NM_aktiv_Diagnose 0;
BA_ "GenSigSwitchedByIgnition" SG_ 2600468496 NM_Gateway_NM_aktiv_EM 0;
BA_ "GenSigSwitchedByIgnition" SG_ 2600468496 NM_Gateway_NM_aktiv_FC 0;
BA_ "GenSigSwitchedByIgnition" SG_ 2600468496 NM_Gateway_NM_aktiv_KL15 0;
BA_ "GenSigSwitchedByIgnition" SG_ 2600468496 NM_Gateway_NM_aktiv_Tmin 0;
BA_ "GenSigSwitchedByIgnition" SG_ 2600468496 NM_Gateway_NM_State 0;
BA_ "GenSigSwitchedByIgnition" SG_ 2600468496 NM_Gateway_UDS_CC 0;
BA_ "GenSigFuncType" SG_ 2600468595 NM_Info_El_CAB_V14 16;
BA_ "GenSigSwitchedByIgnition" SG_ 2600468595 NM_Info_El_CAB_V14 0;
BA_ "GenSigSwitchedByIgnition" SG_ 2600468595 NM_Info_El_Car_Wakeup 0;
BA_ "GenSigSwitchedByIgnition" SG_ 2600468595 NM_Info_El_CBV_AWB 0;
BA_ "GenSigStartValue" SG_ 2600468595 NM_Info_El_CBV_CRI 1;
BA_ "GenSigSwitchedByIgnition" SG_ 2600468595 NM_Info_El_CBV_CRI 0;
BA_ "GenSigSwitchedByIgnition" SG_ 2600468595 NM_Info_El_NM_aktiv_Applikation 0;
BA_ "GenSigSwitchedByIgnition" SG_ 2600468595 NM_Info_El_NM_aktiv_BAP_Comm 0;
BA_ "GenSigSwitchedByIgnition" SG_ 2600468595 NM_Info_El_NM_aktiv_Diagnose 0;
BA_ "GenSigSwitchedByIgnition" SG_ 2600468595 NM_Info_El_NM_aktiv_IAA 0;
BA_ "GenSigSwitchedByIgnition" SG_ 2600468595 NM_Info_El_NM_aktiv_KL15 0;
BA_ "GenSigSwitchedByIgnition" SG_ 2600468595 NM_Info_El_NM_aktiv_MIBCAN 0;
BA_ "GenSigSwitchedByIgnition" SG_ 2600468595 NM_Info_El_NM_aktiv_Powerstate 0;
BA_ "GenSigSwitchedByIgnition" SG_ 2600468595 NM_Info_El_NM_aktiv_SmartLight 0;
BA_ "GenSigSwitchedByIgnition" SG_ 2600468595 NM_Info_El_NM_aktiv_Tmin 0;
BA_ "GenSigSwitchedByIgnition" SG_ 2600468595 NM_Info_El_NM_State 0;
BA_ "GenSigSwitchedByIgnition" SG_ 2600468595 NM_Info_El_UDS_CC 0;
BA_ "GenSigFuncType" SG_ 2600468644 NM_LSH_CAB_V14 16;
BA_ "GenSigSwitchedByIgnition" SG_ 2600468644 NM_LSH_CAB_V14 0;
BA_ "GenSigSwitchedByIgnition" SG_ 2600468644 NM_LSH_Car_Wakeup 0;
BA_ "GenSigSwitchedByIgnition" SG_ 2600468644 NM_LSH_CBV_AWB 0;
BA_ "GenSigSwitchedByIgnition" SG_ 2600468644 NM_LSH_CBV_CRI 0;
BA_ "GenSigSwitchedByIgnition" SG_ 2600468644 NM_LSH_NM_aktiv_Datentransf_Funk 0;
BA_ "GenSigSwitchedByIgnition" SG_ 2600468644 NM_LSH_NM_aktiv_Diagnose 0;
BA_ "GenSigSwitchedByIgnition" SG_ 2600468644 NM_LSH_NM_aktiv_EIN_AUS_Funk 0;
BA_ "GenSigSwitchedByIgnition" SG_ 2600468644 NM_LSH_NM_aktiv_KL15 0;
BA_ "GenSigSwitchedByIgnition" SG_ 2600468644 NM_LSH_NM_aktiv_Tmin 0;
BA_ "GenSigSwitchedByIgnition" SG_ 2600468644 NM_LSH_NM_State 0;
BA_ "GenSigSwitchedByIgnition" SG_ 2600468644 NM_LSH_UDS_CC 0;
BA_ "GenSigFuncType" SG_ 2600468491 NM_RDK_CAB_V14 16;
BA_ "GenSigSwitchedByIgnition" SG_ 2600468491 NM_RDK_CAB_V14 0;
BA_ "GenSigSwitchedByIgnition" SG_ 2600468491 NM_RDK_Car_Wakeup 0;
BA_ "GenSigSwitchedByIgnition" SG_ 2600468491 NM_RDK_CBV_AWB 0;
BA_ "GenSigSwitchedByIgnition" SG_ 2600468491 NM_RDK_CBV_CRI 0;
BA_ "GenSigSwitchedByIgnition" SG_ 2600468491 NM_RDK_NM_aktiv_Diagnose 0;
BA_ "GenSigSwitchedByIgnition" SG_ 2600468491 NM_RDK_NM_aktiv_KL15 0;
BA_ "GenSigSwitchedByIgnition" SG_ 2600468491 NM_RDK_NM_aktiv_Tmin 0;
BA_ "GenSigSwitchedByIgnition" SG_ 2600468491 NM_RDK_NM_State 0;
BA_ "GenSigSwitchedByIgnition" SG_ 2600468491 NM_RDK_UDS_CC 0;
BA_ "GenSigFuncType" SG_ 2600468586 NM_STH_CAB_V14 16;
BA_ "GenSigSwitchedByIgnition" SG_ 2600468586 NM_STH_CAB_V14 0;
BA_ "GenSigSwitchedByIgnition" SG_ 2600468586 NM_STH_Car_Wakeup 0;
BA_ "GenSigSwitchedByIgnition" SG_ 2600468586 NM_STH_NM_aktiv_Datentransf_Funk 0;
BA_ "GenSigSwitchedByIgnition" SG_ 2600468586 NM_STH_NM_aktiv_Diagnose 0;
BA_ "GenSigSwitchedByIgnition" SG_ 2600468586 NM_STH_NM_aktiv_EIN_AUS_Funk 0;
BA_ "GenSigSwitchedByIgnition" SG_ 2600468586 NM_STH_NM_aktiv_EKP_Anf 0;
BA_ "GenSigSwitchedByIgnition" SG_ 2600468586 NM_STH_NM_aktiv_Geblaese_Anf 0;
BA_ "GenSigSwitchedByIgnition" SG_ 2600468586 NM_STH_NM_aktiv_WaPu_Anf 0;
BA_ "GenSigSendType" SG_ 2589283909 NR_01_CAL_Text_Data_1 3;
BA_ "GenSigSendType" SG_ 2589283909 NR_01_CAL_Text_Request 3;
BA_ "GenSigSendType" SG_ 2589283910 NR_01_CAL_Text_Data_2 3;
BA_ "GenSigSendType" SG_ 2589283911 NR_01_CAL_Text_Data_3 3;
BA_ "GenSigSendType" SG_ 2589283912 NR_02_CAL_Text_Data_1 3;
BA_ "GenSigSendType" SG_ 2589283912 NR_02_CAL_Text_Request 3;
BA_ "GenSigSendType" SG_ 2589283913 NR_02_CAL_Text_Data_2 3;
BA_ "GenSigSendType" SG_ 2589283914 NR_02_CAL_Text_Data_3 3;
BA_ "GenSigSendType" SG_ 2589283915 NR_03_CAL_Text_Data_1 3;
BA_ "GenSigSendType" SG_ 2589283915 NR_03_CAL_Text_Request 3;
BA_ "GenSigSendType" SG_ 2589283916 NR_03_CAL_Text_Data_2 3;
BA_ "GenSigSendType" SG_ 2589283917 NR_03_CAL_Text_Data_3 3;
BA_ "GenSigSendType" SG_ 2589283918 NR_04_CAL_Text_Data_1 3;
BA_ "GenSigSendType" SG_ 2589283918 NR_04_CAL_Text_Request 3;
BA_ "GenSigSendType" SG_ 2589283919 NR_04_CAL_Text_Data_2 3;
BA_ "GenSigSendType" SG_ 2589283920 NR_04_CAL_Text_Data_3 3;
BA_ "GenSigSendType" SG_ 2589284036 NR_05_CAL_Text_Data_1 3;
BA_ "GenSigSendType" SG_ 2589284036 NR_05_CAL_Text_Request 3;
BA_ "GenSigSendType" SG_ 2589284037 NR_05_CAL_Text_Data_2 3;
BA_ "GenSigSendType" SG_ 2589284038 NR_05_CAL_Text_Data_3 3;
BA_ "GenSigSendType" SG_ 2589284039 NR_06_CAL_Text_Data_1 3;
BA_ "GenSigSendType" SG_ 2589284039 NR_06_CAL_Text_Request 3;
BA_ "GenSigSendType" SG_ 2589284040 NR_06_CAL_Text_Data_2 3;
BA_ "GenSigSendType" SG_ 2589284041 NR_06_CAL_Text_Data_3 3;
BA_ "GenSigSendType" SG_ 913 MO_QBit_Aussen_Temp 0;
BA_ "GenSigStartValue" SG_ 913 MO_QBit_Aussen_Temp 1;
BA_ "GenSigSwitchedByIgnition" SG_ 913 MO_QBit_Aussen_Temp 0;
BA_ "GenSigSendType" SG_ 913 MO_Servicemodus 0;
BA_ "GenSigSwitchedByIgnition" SG_ 913 MO_Servicemodus 0;
BA_ "GenSigSendType" SG_ 913 OBD_Abs_Load_Val 0;
BA_ "GenSigStartValue" SG_ 913 OBD_Abs_Load_Val 65535;
BA_ "GenSigSwitchedByIgnition" SG_ 913 OBD_Abs_Load_Val 0;
BA_ "GenSigSendType" SG_ 913 OBD_Abs_Pedal_Pos 0;
BA_ "GenSigStartValue" SG_ 913 OBD_Abs_Pedal_Pos 255;
BA_ "GenSigSwitchedByIgnition" SG_ 913 OBD_Abs_Pedal_Pos 0;
BA_ "GenSigSendType" SG_ 913 OBD_Abs_Throttle_Pos 0;
BA_ "GenSigStartValue" SG_ 913 OBD_Abs_Throttle_Pos 255;
BA_ "GenSigSwitchedByIgnition" SG_ 913 OBD_Abs_Throttle_Pos 0;
BA_ "GenSigSendType" SG_ 913 OBD_Calc_Load_Val 0;
BA_ "GenSigStartValue" SG_ 913 OBD_Calc_Load_Val 255;
BA_ "GenSigSwitchedByIgnition" SG_ 913 OBD_Calc_Load_Val 0;
BA_ "GenSigSendType" SG_ 913 OBD_ClearMem_Inhibit 0;
BA_ "GenSigSwitchedByIgnition" SG_ 913 OBD_ClearMem_Inhibit 0;
BA_ "GenSigSendType" SG_ 913 OBD_Driving_Cycle 0;
BA_ "GenSigSwitchedByIgnition" SG_ 913 OBD_Driving_Cycle 0;
BA_ "GenSigSendType" SG_ 913 OBD_Eng_Cool_Temp 0;
BA_ "GenSigStartValue" SG_ 913 OBD_Eng_Cool_Temp 255;
BA_ "GenSigSwitchedByIgnition" SG_ 913 OBD_Eng_Cool_Temp 0;
BA_ "GenSigSendType" SG_ 913 OBD_Kaltstart_Denominator 0;
BA_ "GenSigSwitchedByIgnition" SG_ 913 OBD_Kaltstart_Denominator 0;
BA_ "GenSigSendType" SG_ 913 OBD_Minimum_Trip 0;
BA_ "GenSigSwitchedByIgnition" SG_ 913 OBD_Minimum_Trip 0;
BA_ "GenSigSendType" SG_ 913 OBD_Normed_Trip 0;
BA_ "GenSigSwitchedByIgnition" SG_ 913 OBD_Normed_Trip 0;
BA_ "GenSigSendType" SG_ 913 OBD_Sperrung_IUMPR 0;
BA_ "GenSigSwitchedByIgnition" SG_ 913 OBD_Sperrung_IUMPR 0;
BA_ "GenSigSendType" SG_ 913 OBD_Sperrung_Kaltstart_Denom 0;
BA_ "GenSigSwitchedByIgnition" SG_ 913 OBD_Sperrung_Kaltstart_Denom 0;
BA_ "GenSigSendType" SG_ 913 OBD_Warm_Up_Cycle 0;
BA_ "GenSigSwitchedByIgnition" SG_ 913 OBD_Warm_Up_Cycle 0;
BA_ "GenSigSendType" SG_ 2550399540 OBDC_BedienDisp_m_Req_Data 3;
BA_ "GenSigFuncType" SG_ 2550399540 OBDC_BedienDisp_m_Req_Data 9;
BA_ "GenSigSwitchedByIgnition" SG_ 2550399540 OBDC_BedienDisp_m_Req_Data 0;
BA_ "GenSigSendType" SG_ 2550530612 OBDC_BedienDisp_m_Resp_Data 3;
BA_ "GenSigFuncType" SG_ 2550530612 OBDC_BedienDisp_m_Resp_Data 9;
BA_ "GenSigSwitchedByIgnition" SG_ 2550530612 OBDC_BedienDisp_m_Resp_Data 0;
BA_ "GenSigSendType" SG_ 2549875362 OBDC_BedienDisp_vm_Req_Data 3;
BA_ "GenSigFuncType" SG_ 2549875362 OBDC_BedienDisp_vm_Req_Data 9;
BA_ "GenSigSwitchedByIgnition" SG_ 2549875362 OBDC_BedienDisp_vm_Req_Data 0;
BA_ "GenSigSendType" SG_ 2550006434 OBDC_BedienDisp_vm_Resp_Data 3;
BA_ "GenSigFuncType" SG_ 2550006434 OBDC_BedienDisp_vm_Resp_Data 9;
BA_ "GenSigSwitchedByIgnition" SG_ 2550006434 OBDC_BedienDisp_vm_Resp_Data 0;
BA_ "GenSigSendType" SG_ 2549875303 OBDC_eCall_Req_Data 3;
BA_ "GenSigFuncType" SG_ 2549875303 OBDC_eCall_Req_Data 9;
BA_ "GenSigSwitchedByIgnition" SG_ 2549875303 OBDC_eCall_Req_Data 0;
BA_ "GenSigSendType" SG_ 2550006375 OBDC_eCall_Resp_Data 3;
BA_ "GenSigFuncType" SG_ 2550006375 OBDC_eCall_Resp_Data 9;
BA_ "GenSigSwitchedByIgnition" SG_ 2550006375 OBDC_eCall_Resp_Data 0;
BA_ "GenSigSendType" SG_ 2549940736 OBDC_Funktionaler_Req_All_Data 3;
BA_ "GenSigFuncType" SG_ 2549940736 OBDC_Funktionaler_Req_All_Data 9;
BA_ "GenSigSwitchedByIgnition" SG_ 2549940736 OBDC_Funktionaler_Req_All_Data 0;
BA_ "GenSigSendType" SG_ 2549875315 OBDC_Info_El_Req_Data 3;
BA_ "GenSigFuncType" SG_ 2549875315 OBDC_Info_El_Req_Data 9;
BA_ "GenSigSwitchedByIgnition" SG_ 2549875315 OBDC_Info_El_Req_Data 0;
BA_ "GenSigSendType" SG_ 2550006387 OBDC_Info_El_Resp_Data 3;
BA_ "GenSigFuncType" SG_ 2550006387 OBDC_Info_El_Resp_Data 9;
BA_ "GenSigSwitchedByIgnition" SG_ 2550006387 OBDC_Info_El_Resp_Data 0;
BA_ "GenSigSendType" SG_ 2549875364 OBDC_LSH_Req_Data 3;
BA_ "GenSigFuncType" SG_ 2549875364 OBDC_LSH_Req_Data 9;
BA_ "GenSigSwitchedByIgnition" SG_ 2549875364 OBDC_LSH_Req_Data 0;
BA_ "GenSigSendType" SG_ 2550006436 OBDC_LSH_Resp_Data 3;
BA_ "GenSigFuncType" SG_ 2550006436 OBDC_LSH_Resp_Data 9;
BA_ "GenSigSwitchedByIgnition" SG_ 2550006436 OBDC_LSH_Resp_Data 0;
BA_ "GenSigSendType" SG_ 2549875211 OBDC_RDK_Req_Data 3;
BA_ "GenSigFuncType" SG_ 2549875211 OBDC_RDK_Req_Data 9;
BA_ "GenSigSwitchedByIgnition" SG_ 2549875211 OBDC_RDK_Req_Data 0;
BA_ "GenSigSendType" SG_ 2550006283 OBDC_RDK_Resp_Data 3;
BA_ "GenSigFuncType" SG_ 2550006283 OBDC_RDK_Resp_Data 9;
BA_ "GenSigSwitchedByIgnition" SG_ 2550006283 OBDC_RDK_Resp_Data 0;
BA_ "GenSigSendType" SG_ 2549903374 OBDC_SSN_ABT_1_Req_Data 3;
BA_ "GenSigFuncType" SG_ 2549903374 OBDC_SSN_ABT_1_Req_Data 9;
BA_ "GenSigSwitchedByIgnition" SG_ 2549903374 OBDC_SSN_ABT_1_Req_Data 0;
BA_ "GenSigSendType" SG_ 2550034446 OBDC_SSN_ABT_1_Resp_Data 3;
BA_ "GenSigFuncType" SG_ 2550034446 OBDC_SSN_ABT_1_Resp_Data 9;
BA_ "GenSigSwitchedByIgnition" SG_ 2550034446 OBDC_SSN_ABT_1_Resp_Data 0;
BA_ "GenSigSendType" SG_ 2549875306 OBDC_STH_Req_Data 3;
BA_ "GenSigFuncType" SG_ 2549875306 OBDC_STH_Req_Data 9;
BA_ "GenSigSwitchedByIgnition" SG_ 2549875306 OBDC_STH_Req_Data 0;
BA_ "GenSigSendType" SG_ 2550006378 OBDC_STH_Resp_Data 3;
BA_ "GenSigFuncType" SG_ 2550006378 OBDC_STH_Resp_Data 9;
BA_ "GenSigSwitchedByIgnition" SG_ 2550006378 OBDC_STH_Resp_Data 0;
BA_ "GenSigSendType" SG_ 2549875309 OBDC_TV_Tuner_Req_Data 3;
BA_ "GenSigFuncType" SG_ 2549875309 OBDC_TV_Tuner_Req_Data 9;
BA_ "GenSigSwitchedByIgnition" SG_ 2549875309 OBDC_TV_Tuner_Req_Data 0;
BA_ "GenSigSendType" SG_ 2550006381 OBDC_TV_Tuner_Resp_Data 3;
BA_ "GenSigFuncType" SG_ 2550006381 OBDC_TV_Tuner_Resp_Data 9;
BA_ "GenSigSwitchedByIgnition" SG_ 2550006381 OBDC_TV_Tuner_Resp_Data 0;
BA_ "GenSigSendType" SG_ 2549875365 OBDC_WLC1_Req_Data 3;
BA_ "GenSigFuncType" SG_ 2549875365 OBDC_WLC1_Req_Data 9;
BA_ "GenSigSwitchedByIgnition" SG_ 2549875365 OBDC_WLC1_Req_Data 0;
BA_ "GenSigSendType" SG_ 2550006437 OBDC_WLC1_Resp_Data 3;
BA_ "GenSigFuncType" SG_ 2550006437 OBDC_WLC1_Resp_Data 9;
BA_ "GenSigSwitchedByIgnition" SG_ 2550006437 OBDC_WLC1_Resp_Data 0;
BA_ "GenSigSwitchedByIgnition" SG_ 28 OCU_WFS_Anfrage_CRC 0;
BA_ "GenSigSwitchedByIgnition" SG_ 28 OCU_WFS_Anfrage_Status 0;
BA_ "GenSigSwitchedByIgnition" SG_ 28 OCU_WFS_Anfrage_Typ 0;
BA_ "GenSigSendType" SG_ 2589283656 ORU_Status 3;
BA_ "GenSigSwitchedByIgnition" SG_ 2589283656 ORU_Status 0;
BA_ "GenSigSendType" SG_ 2589283656 ORU_Warnung 3;
BA_ "GenSigSwitchedByIgnition" SG_ 2589283656 ORU_Warnung 0;
BA_ "GenSigSendType" SG_ 2549909095 ORU_eCall_Req_Data 3;
BA_ "GenSigFuncType" SG_ 2549909095 ORU_eCall_Req_Data 9;
BA_ "GenSigSwitchedByIgnition" SG_ 2549909095 ORU_eCall_Req_Data 0;
BA_ "GenSigSendType" SG_ 2550040167 ORU_eCall_Resp_Data 3;
BA_ "GenSigFuncType" SG_ 2550040167 ORU_eCall_Resp_Data 9;
BA_ "GenSigSwitchedByIgnition" SG_ 2550040167 ORU_eCall_Resp_Data 0;
BA_ "GenSigSendType" SG_ 1175 PDC_Tonausgabe_Front 3;
BA_ "GenSigSendType" SG_ 1175 PDC_Tonausgabe_Heck 3;
BA_ "GenSigSendType" SG_ 1175 PH_Abschaltursache 3;
BA_ "GenSigSendType" SG_ 1175 PH_Anf_Audioabsenkung 3;
BA_ "GenSigSendType" SG_ 1175 PH_Anf_Verdeck 3;
BA_ "GenSigSendType" SG_ 1175 PH_defekt 3;
BA_ "GenSigSendType" SG_ 1175 PH_Display_Kundenwunsch 3;
BA_ "GenSigSendType" SG_ 1175 PH_Frequenz_hinten 3;
BA_ "GenSigSendType" SG_ 1175 PH_Frequenz_vorn 3;
BA_ "GenSigSendType" SG_ 1175 PH_gestoert 3;
BA_ "GenSigSendType" SG_ 1175 PH_Lautstaerke_hinten 3;
BA_ "GenSigSendType" SG_ 1175 PH_Lautstaerke_vorn 3;
BA_ "GenSigSendType" SG_ 1175 PH_nachtr_Stopp_Anf 3;
BA_ "GenSigSendType" SG_ 1175 PH_Opt_Anz_H_Hindernis 3;
BA_ "GenSigSendType" SG_ 1175 PH_Opt_Anz_V_Hindernis 3;
BA_ "GenSigSendType" SG_ 1175 PH_Opt_Anzeige_H_ein 3;
BA_ "GenSigSendType" SG_ 1175 PH_Opt_Anzeige_V_ein 3;
BA_ "GenSigSendType" SG_ 1175 PH_StartStopp_Info 3;
BA_ "GenSigSendType" SG_ 1175 PH_Stoermeldung 3;
BA_ "GenSigSendType" SG_ 1175 PH_Systemzustand 3;
BA_ "GenSigSendType" SG_ 1175 PH_Taster 3;
BA_ "Fehlerwert" SG_ 1175 PH_Taster 3;
BA_ "GenSigSendType" SG_ 1175 PH_Tongeber_H_aktiv 3;
BA_ "GenSigSendType" SG_ 1175 PH_Tongeber_H_verfuegbar 3;
BA_ "GenSigSendType" SG_ 1175 PH_Tongeber_mute 3;
BA_ "GenSigSendType" SG_ 1175 PH_Tongeber_V_aktiv 3;
BA_ "GenSigSendType" SG_ 1175 PH_Visualisierung 3;
BA_ "GenSigStartValue" SG_ 1175 PH_Visualisierung 6;
BA_ "Fehlerwert" SG_ 1175 PH_Visualisierung 7;
BA_ "GenSigSendType" SG_ 1175 PLA_Anf_Aufschaltung_RVC 3;
BA_ "GenSigSendType" SG_ 1355 APS_PaCo_WarningTones 3;
BA_ "GenSigSwitchedByIgnition" SG_ 1355 APS_PaCo_WarningTones 0;
BA_ "GenSigSendType" SG_ 1355 APSOPS_PaCo_ApproachingFront 3;
BA_ "GenSigSwitchedByIgnition" SG_ 1355 APSOPS_PaCo_ApproachingFront 0;
BA_ "GenSigSendType" SG_ 1355 APSOPS_PaCo_ApproachingRear 3;
BA_ "GenSigSwitchedByIgnition" SG_ 1355 APSOPS_PaCo_ApproachingRear 0;
BA_ "GenSigSendType" SG_ 1355 APSOPS_PaCo_Button 3;
BA_ "GenSigSwitchedByIgnition" SG_ 1355 APSOPS_PaCo_Button 0;
BA_ "GenSigSendType" SG_ 1355 APSOPS_PaCo_FunctionState 3;
BA_ "GenSigSwitchedByIgnition" SG_ 1355 APSOPS_PaCo_FunctionState 0;
BA_ "GenSigSendType" SG_ 1355 APSOPS_PaCo_MainState 3;
BA_ "GenSigSwitchedByIgnition" SG_ 1355 APSOPS_PaCo_MainState 0;
BA_ "Fehlerwert" SG_ 1355 APSOPS_PaCo_MainState 7;
BA_ "GenSigSendType" SG_ 1355 APSOPS_PaCo_ObstacleDetectFront 3;
BA_ "GenSigSwitchedByIgnition" SG_ 1355 APSOPS_PaCo_ObstacleDetectFront 0;
BA_ "GenSigSendType" SG_ 1355 APSOPS_PaCo_ObstacleDetectRear 3;
BA_ "GenSigSwitchedByIgnition" SG_ 1355 APSOPS_PaCo_ObstacleDetectRear 0;
BA_ "GenSigSendType" SG_ 1355 PH_Aufschaltursache 3;
BA_ "GenSigSendType" SG_ 1355 PH_Ton_Ausgabe 3;
BA_ "Fehlerwert" SG_ 1355 PH_Ton_Ausgabe 7;
BA_ "GenSigSendType" SG_ 1355 PH_Ton_Lautstaerke 3;
BA_ "GenSigSendType" SG_ 1355 PH_Ton_Pausenlaenge 3;
BA_ "Fehlerwert" SG_ 1355 PH_Ton_Pausenlaenge 127;
BA_ "GenSigSendType" SG_ 1355 PH_Ton_Richtung 3;
BA_ "GenSigSendType" SG_ 1355 PH_Verschmutzungsmeldung 3;
BA_ "GenSigSendType" SG_ 1355 PH_WAH_Meldung 3;
BA_ "GenSigSendType" SG_ 1355 RAB_PaCo_FunctionState 3;
BA_ "GenSigSwitchedByIgnition" SG_ 1355 RAB_PaCo_FunctionState 0;
BA_ "GenSigSendType" SG_ 1355 RBF_Anf_Meldungen 3;
BA_ "GenSigSendType" SG_ 1355 RBF_PaCo_Anf_Meldungen 3;
BA_ "GenSigSendType" SG_ 1355 RBF_PMO_Bereich_erkannt 3;
BA_ "GenSigSendType" SG_ 1355 RBFMA_PaCo_BrakeIntervention 3;
BA_ "GenSigSwitchedByIgnition" SG_ 1355 RBFMA_PaCo_BrakeIntervention 0;
BA_ "GenSigSendType" SG_ 1355 RBFMA_PaCo_MainState 3;
BA_ "GenSigSwitchedByIgnition" SG_ 1355 RBFMA_PaCo_MainState 0;
BA_ "Fehlerwert" SG_ 1355 RBFMA_PaCo_MainState 7;
BA_ "GenSigSendType" SG_ 2527679498 IAA_Active_User_ID 4;
BA_ "GenSigSwitchedByIgnition" SG_ 2527679498 IAA_Active_User_ID 0;
BA_ "GenSigSendType" SG_ 2527679498 IAA_Identified_User_ID 4;
BA_ "GenSigSwitchedByIgnition" SG_ 2527679498 IAA_Identified_User_ID 0;
BA_ "GenSigSendType" SG_ 2527679498 IAA_PSO_wake_up 4;
BA_ "GenSigSwitchedByIgnition" SG_ 2527679498 IAA_PSO_wake_up 0;
BA_ "GenSigSendType" SG_ 2527679498 Perso_Aktiv 4;
BA_ "GenSigSwitchedByIgnition" SG_ 2527679498 Perso_Aktiv 0;
BA_ "GenSigSendType" SG_ 2527679498 Perso_Bedienstelle 4;
BA_ "GenSigSwitchedByIgnition" SG_ 2527679498 Perso_Bedienstelle 0;
BA_ "GenSigSendType" SG_ 2527679498 Perso_Fahrernummer 4;
BA_ "GenSigSwitchedByIgnition" SG_ 2527679498 Perso_Fahrernummer 0;
BA_ "GenSigSendType" SG_ 2527679498 Perso_Freigabe_Verstellung 4;
BA_ "GenSigSwitchedByIgnition" SG_ 2527679498 Perso_Freigabe_Verstellung 0;
BA_ "GenSigSendType" SG_ 2527679498 Perso_Kontonummer 4;
BA_ "GenSigSwitchedByIgnition" SG_ 2527679498 Perso_Kontonummer 0;
BA_ "GenSigSendType" SG_ 2527679498 Perso_Schreibschutz 4;
BA_ "GenSigSwitchedByIgnition" SG_ 2527679498 Perso_Schreibschutz 0;
BA_ "GenSigSendType" SG_ 2527679498 Perso_Status 1;
BA_ "GenSigSwitchedByIgnition" SG_ 2527679498 Perso_Status 0;
BA_ "GenSigSendType" SG_ 2527679498 Perso_Steuerung 4;
BA_ "GenSigSwitchedByIgnition" SG_ 2527679498 Perso_Steuerung 0;
BA_ "GenSigSendType" SG_ 2527679498 Perso_Steuerungsparameter 4;
BA_ "GenSigSwitchedByIgnition" SG_ 2527679498 Perso_Steuerungsparameter 0;
BA_ "GenSigSendType" SG_ 2463978629 IAA_Active_User_ID_02 4;
BA_ "GenSigSwitchedByIgnition" SG_ 2463978629 IAA_Active_User_ID_02 0;
BA_ "GenSigSendType" SG_ 2463978629 IAA_Identified_User_ID_02 4;
BA_ "GenSigSwitchedByIgnition" SG_ 2463978629 IAA_Identified_User_ID_02 0;
BA_ "GenSigSendType" SG_ 2463978629 Perso_Aktiv_02 4;
BA_ "GenSigSwitchedByIgnition" SG_ 2463978629 Perso_Aktiv_02 0;
BA_ "GenSigSendType" SG_ 2463978629 Perso_Bedienstelle_02 4;
BA_ "GenSigSwitchedByIgnition" SG_ 2463978629 Perso_Bedienstelle_02 0;
BA_ "GenSigSendType" SG_ 2463978629 Perso_Fahrernummer_02 4;
BA_ "GenSigSwitchedByIgnition" SG_ 2463978629 Perso_Fahrernummer_02 0;
BA_ "GenSigSendType" SG_ 2463978629 Perso_Freigabe_Verstellung_02 4;
BA_ "GenSigSwitchedByIgnition" SG_ 2463978629 Perso_Freigabe_Verstellung_02 0;
BA_ "GenSigSendType" SG_ 2463978629 Perso_Kontonummer_02 4;
BA_ "GenSigSwitchedByIgnition" SG_ 2463978629 Perso_Kontonummer_02 0;
BA_ "GenSigSendType" SG_ 2463978629 Perso_Schreibschutz_02 4;
BA_ "GenSigSwitchedByIgnition" SG_ 2463978629 Perso_Schreibschutz_02 0;
BA_ "GenSigSendType" SG_ 2463978629 Perso_Status_02 1;
BA_ "GenSigSwitchedByIgnition" SG_ 2463978629 Perso_Status_02 0;
BA_ "GenSigSendType" SG_ 2463978629 Perso_Steuerung_02 4;
BA_ "GenSigSwitchedByIgnition" SG_ 2463978629 Perso_Steuerung_02 0;
BA_ "GenSigSendType" SG_ 2463978629 Perso_Steuerungsparameter_02 4;
BA_ "GenSigSwitchedByIgnition" SG_ 2463978629 Perso_Steuerungsparameter_02 0;
BA_ "GenSigSendType" SG_ 319 PreCrash_Anforderung_AFR 3;
BA_ "GenSigStartValue" SG_ 319 PreCrash_Anforderung_AFR 7;
BA_ "GenSigSwitchedByIgnition" SG_ 319 PreCrash_Anforderung_AFR 0;
BA_ "GenSigSendType" SG_ 319 PreCrash_BFS_KSV_verfahren 3;
BA_ "GenSigSwitchedByIgnition" SG_ 319 PreCrash_BFS_KSV_verfahren 0;
BA_ "GenSigSendType" SG_ 319 PreCrash_BFS_Laengsverstellung 3;
BA_ "GenSigSwitchedByIgnition" SG_ 319 PreCrash_BFS_Laengsverstellung 0;
BA_ "GenSigSendType" SG_ 319 PreCrash_BFS_Pneumatik_ansteuern 3;
BA_ "GenSigSwitchedByIgnition" SG_ 319 PreCrash_BFS_Pneumatik_ansteuern 0;
BA_ "GenSigSendType" SG_ 319 PreCrash_BFS_Sitzlehne_verfahren 3;
BA_ "GenSigSwitchedByIgnition" SG_ 319 PreCrash_BFS_Sitzlehne_verfahren 0;
BA_ "GenSigSendType" SG_ 319 PreCrash_Blinken 3;
BA_ "GenSigSendType" SG_ 319 PreCrash_Charisma_FahrPr 0;
BA_ "GenSigSendType" SG_ 319 PreCrash_Charisma_Status 0;
BA_ "GenSigSendType" SG_ 319 PreCrash_Fenster_schliessen 3;
BA_ "GenSigSendType" SG_ 319 PreCrash_Fo_KSV_verfahren 3;
BA_ "GenSigSendType" SG_ 319 PreCrash_Fo_Pneumatik_ansteuern 3;
BA_ "GenSigSendType" SG_ 319 PreCrash_Fo_Sitzlehne_verfahren 3;
BA_ "GenSigSwitchedByIgnition" SG_ 319 PreCrash_Fo_Sitzlehne_verfahren 0;
BA_ "GenSigSendType" SG_ 319 PreCrash_FS_KSV_verfahren 3;
BA_ "GenSigSwitchedByIgnition" SG_ 319 PreCrash_FS_KSV_verfahren 0;
BA_ "GenSigSendType" SG_ 319 PreCrash_FS_Laengsverstellung 3;
BA_ "GenSigSwitchedByIgnition" SG_ 319 PreCrash_FS_Laengsverstellung 0;
BA_ "GenSigSendType" SG_ 319 PreCrash_FS_Pneumatik_ansteuern 3;
BA_ "GenSigSwitchedByIgnition" SG_ 319 PreCrash_FS_Pneumatik_ansteuern 0;
BA_ "GenSigSendType" SG_ 319 PreCrash_FS_Sitzlehne_verfahren 3;
BA_ "GenSigSwitchedByIgnition" SG_ 319 PreCrash_FS_Sitzlehne_verfahren 0;
BA_ "GenSigSendType" SG_ 319 PreCrash_Schiebedach_schliessen 3;
BA_ "GenSigSendType" SG_ 319 PreCrash_Tueren_Verriegeln 3;
BA_ "GenSigSwitchedByIgnition" SG_ 319 PreCrash_Tueren_Verriegeln 0;
BA_ "GenSigSendType" SG_ 319 SC_PreCrash_LED 3;
BA_ "GenSigSwitchedByIgnition" SG_ 319 SC_PreCrash_LED 0;
BA_ "GenSigSendType" SG_ 319 SC_PreCrash_Texte 3;
BA_ "GenSigSwitchedByIgnition" SG_ 319 SC_PreCrash_Texte 0;
BA_ "GenSigSendType" SG_ 319 SC_PreCrash_Warnung 3;
BA_ "GenSigSwitchedByIgnition" SG_ 319 SC_PreCrash_Warnung 0;
BA_ "GenSigSendType" SG_ 319 SC_PreSense_FCWP 3;
BA_ "GenSigSwitchedByIgnition" SG_ 319 SC_PreSense_FCWP 0;
BA_ "GenSigSendType" SG_ 1122 PSD_Abzweigerichtung 0;
BA_ "GenSigSwitchedByIgnition" SG_ 1122 PSD_Abzweigerichtung 0;
BA_ "GenSigSendType" SG_ 1122 PSD_Abzweigewinkel 0;
BA_ "GenSigSwitchedByIgnition" SG_ 1122 PSD_Abzweigewinkel 0;
BA_ "GenSigSendType" SG_ 1122 PSD_ADAS_Qualitaet 0;
BA_ "GenSigSendType" SG_ 1122 PSD_Anfangskruemmung 0;
BA_ "GenSigSwitchedByIgnition" SG_ 1122 PSD_Anfangskruemmung 0;
BA_ "GenSigSendType" SG_ 1122 PSD_Anfangskruemmung_Vorz 0;
BA_ "GenSigSwitchedByIgnition" SG_ 1122 PSD_Anfangskruemmung_Vorz 0;
BA_ "GenSigSendType" SG_ 1122 PSD_Bebauung 0;
BA_ "GenSigSendType" SG_ 1122 PSD_Endkruemmung 0;
BA_ "GenSigSendType" SG_ 1122 PSD_Endkruemmung_Vorz 0;
BA_ "GenSigSendType" SG_ 1122 PSD_Fahrspuren_Anzahl 0;
BA_ "GenSigStartValue" SG_ 1122 PSD_Fahrspuren_Anzahl 1;
BA_ "GenSigSwitchedByIgnition" SG_ 1122 PSD_Fahrspuren_Anzahl 0;
BA_ "GenSigSendType" SG_ 1122 PSD_Geradester_Pfad 0;
BA_ "GenSigSendType" SG_ 1122 PSD_Idenditaets_ID 0;
BA_ "Fehlerwert" SG_ 1122 PSD_Idenditaets_ID 1;
BA_ "GenSigSendType" SG_ 1122 PSD_Rampe 0;
BA_ "GenSigSendType" SG_ 1122 PSD_Segment_ID 0;
BA_ "GenSigSendType" SG_ 1122 PSD_Segment_Komplett 0;
BA_ "GenSigSwitchedByIgnition" SG_ 1122 PSD_Segment_Komplett 0;
BA_ "GenSigSendType" SG_ 1122 PSD_Segmentlaenge 0;
BA_ "GenSigSendType" SG_ 1122 PSD_Strassenkategorie 0;
BA_ "GenSigStartValue" SG_ 1122 PSD_Strassenkategorie 7;
BA_ "GenSigSwitchedByIgnition" SG_ 1122 PSD_Strassenkategorie 0;
BA_ "GenSigSendType" SG_ 1122 PSD_Vorgaenger_Segment_ID 0;
BA_ "GenSigSendType" SG_ 1122 PSD_wahrscheinlichster_Pfad 0;
BA_ "GenSigSendType" SG_ 1123 PSD_Attribut_1_ID 0;
BA_ "GenSigSendType" SG_ 1123 PSD_Attribut_1_Offset 0;
BA_ "GenSigSendType" SG_ 1123 PSD_Attribut_1_Wert 0;
BA_ "GenSigSendType" SG_ 1123 PSD_Attribut_2_ID 0;
BA_ "GenSigSendType" SG_ 1123 PSD_Attribut_2_Offset 0;
BA_ "GenSigSendType" SG_ 1123 PSD_Attribut_2_Wert 0;
BA_ "GenSigSendType" SG_ 1123 PSD_Attribut_Segment_ID_05 0;
BA_ "Fehlerwert" SG_ 1123 PSD_Attribut_Segment_ID_05 1;
BA_ "GenSigSendType" SG_ 1123 PSD_Attribute_Komplett_05 0;
BA_ "GenSigSendType" SG_ 1123 PSD_Pos_Fahrspur 0;
BA_ "GenSigSendType" SG_ 1123 PSD_Pos_Fehler_Laengsrichtung 0;
BA_ "GenSigSendType" SG_ 1123 PSD_Pos_Inhibitzeit 0;
BA_ "GenSigSendType" SG_ 1123 PSD_Pos_Segment_ID 0;
BA_ "GenSigSendType" SG_ 1123 PSD_Pos_Segmentlaenge 0;
BA_ "GenSigSendType" SG_ 1123 PSD_Pos_Standort_Eindeutig 0;
BA_ "GenSigSwitchedByIgnition" SG_ 1123 PSD_Pos_Standort_Eindeutig 0;
BA_ "GenSigSendType" SG_ 1124 PSD_06_Mux 0;
BA_ "NWM-WakeupAllowed" SG_ 1124 PSD_06_Mux 1;
BA_ "GenSigSwitchedByIgnition" SG_ 1124 PSD_06_Mux 0;
BA_ "Fehlerwert" SG_ 1124 PSD_Attribut_Segment_ID 1;
BA_ "GenSigSwitchedByIgnition" SG_ 1124 PSD_Attribute_Komplett_06 0;
BA_ "GenSigStartValue" SG_ 1124 PSD_Ges_Typ 3;
BA_ "GenSigSwitchedByIgnition" SG_ 1124 PSD_Ges_Typ 0;
BA_ "GenSigSwitchedByIgnition" SG_ 1124 PSD_Steigung_1_Attribute_kompl 0;
BA_ "Fehlerwert" SG_ 1124 PSD_Steigung_1_Segment_ID 1;
BA_ "GenSigSwitchedByIgnition" SG_ 1124 PSD_Steigung_2_Attribute_kompl 0;
BA_ "Fehlerwert" SG_ 1124 PSD_Steigung_2_Segment_ID 1;
BA_ "GenSigSendType" SG_ 1125 PSD_LR_01_MUX 0;
BA_ "GenSigSendType" SG_ 1125 PSD_LR_Profil_Nummer 0;
BA_ "GenSigSwitchedByIgnition" SG_ 1125 PSD_LR_Steigung_3_Vorz 0;
BA_ "GenSigSendType" SG_ 1616 RA_AM_Tuning 3;
BA_ "GenSigSwitchedByIgnition" SG_ 1616 RA_AM_Tuning 0;
BA_ "GenSigSendType" SG_ 1616 RA_Frequency 3;
BA_ "GenSigSwitchedByIgnition" SG_ 1616 RA_Frequency 0;
BA_ "GenSigSendType" SG_ 1616 RA_Frequency_unit 3;
BA_ "GenSigSwitchedByIgnition" SG_ 1616 RA_Frequency_unit 0;
BA_ "GenSigSendType" SG_ 1616 RA_PowerAmpOn 3;
BA_ "GenSigSwitchedByIgnition" SG_ 1616 RA_PowerAmpOn 0;
BA_ "GenSigSendType" SG_ 1616 RA_Radio_Error_Flag 3;
BA_ "GenSigSwitchedByIgnition" SG_ 1616 RA_Radio_Error_Flag 0;
BA_ "GenSigSendType" SG_ 1616 RA_Radio_mute 3;
BA_ "GenSigSwitchedByIgnition" SG_ 1616 RA_Radio_mute 0;
BA_ "GenSigSendType" SG_ 1616 RA_Radio_on 3;
BA_ "GenSigSwitchedByIgnition" SG_ 1616 RA_Radio_on 0;
BA_ "GenSigSendType" SG_ 1616 RA_Radio_Surround 3;
BA_ "GenSigSwitchedByIgnition" SG_ 1616 RA_Radio_Surround 0;
BA_ "GenSigSendType" SG_ 1616 RA_VNC_OFF 3;
BA_ "GenSigSwitchedByIgnition" SG_ 1616 RA_VNC_OFF 0;
BA_REL_ "GenSigTimeoutTime" BU_SG_REL_ BedienDisp_mi SG_ 2600468496 NM_Gateway_NM_State 2000;
BA_REL_ "GenSigTimeoutTime" BU_SG_REL_ BedienDisp_mi SG_ 2600468595 NM_Info_El_NM_State 2000;
BA_REL_ "GenSigTimeoutTime" BU_SG_REL_ BedienDisp_mi SG_ 2600468644 NM_LSH_NM_State 2000;
BA_REL_ "GenSigTimeoutTime" BU_SG_REL_ BedienDisp_mi SG_ 2600468491 NM_RDK_NM_State 2000;
BA_REL_ "GenSigTimeoutTime" BU_SG_REL_ BedienDisp_mi SG_ 2600468586 NM_STH_NM_State 2000;
BA_REL_ "GenSigTimeoutTime" BU_SG_REL_ BedienDisp_mi SG_ 913 OBD_Driving_Cycle 1000;
BA_REL_ "GenSigTimeoutTime" BU_SG_REL_ BedienDisp_vo_mi SG_ 2600468496 NM_Gateway_NM_State 2000;
BA_REL_ "GenSigTimeoutTime" BU_SG_REL_ BedienDisp_vo_mi SG_ 2600468595 NM_Info_El_NM_State 2000;
BA_REL_ "GenSigTimeoutTime" BU_SG_REL_ BedienDisp_vo_mi SG_ 2600468644 NM_LSH_NM_State 2000;
BA_REL_ "GenSigTimeoutTime" BU_SG_REL_ BedienDisp_vo_mi SG_ 2600468491 NM_RDK_NM_State 2000;
BA_REL_ "GenSigTimeoutTime" BU_SG_REL_ BedienDisp_vo_mi SG_ 2600468586 NM_STH_NM_State 2000;
BA_REL_ "GenSigTimeoutTime" BU_SG_REL_ BedienDisp_vo_mi SG_ 1616 RA_Radio_on 5000;
BA_REL_ "GenSigTimeoutTime" BU_SG_REL_ CDI SG_ 2600468496 NM_Gateway_NM_State 2000;
BA_REL_ "GenSigTimeoutTime" BU_SG_REL_ CDI SG_ 2600468595 NM_Info_El_NM_State 2000;
BA_REL_ "GenSigTimeoutTime" BU_SG_REL_ CDI SG_ 2600468644 NM_LSH_NM_State 2000;
BA_REL_ "GenSigTimeoutTime" BU_SG_REL_ CDI SG_ 2600468491 NM_RDK_NM_State 2000;
BA_REL_ "GenSigTimeoutTime" BU_SG_REL_ CDI SG_ 2600468586 NM_STH_NM_State 2000;
BA_REL_ "GenSigTimeoutTime" BU_SG_REL_ ConMod_CD SG_ 2600468496 NM_Gateway_NM_State 2000;
BA_REL_ "GenSigTimeoutTime" BU_SG_REL_ ConMod_CD SG_ 2600468595 NM_Info_El_NM_State 2000;
BA_REL_ "GenSigTimeoutTime" BU_SG_REL_ ConMod_CD SG_ 2600468644 NM_LSH_NM_State 2000;
BA_REL_ "GenSigTimeoutTime" BU_SG_REL_ ConMod_CD SG_ 2600468491 NM_RDK_NM_State 2000;
BA_REL_ "GenSigTimeoutTime" BU_SG_REL_ ConMod_CD SG_ 2600468586 NM_STH_NM_State 2000;
BA_REL_ "GenSigTimeoutTime" BU_SG_REL_ ConMod_CD SG_ 913 OBD_Kaltstart_Denominator 1000;
BA_REL_ "GenSigTimeoutTime" BU_SG_REL_ ConMod_CD SG_ 913 OBD_Driving_Cycle 1000;
BA_REL_ "GenSigTimeoutTime" BU_SG_REL_ ConMod_CD SG_ 913 OBD_Warm_Up_Cycle 1000;
BA_REL_ "GenSigTimeoutTime" BU_SG_REL_ ConMod_CD SG_ 2589283656 ORU_Status 5000;
BA_REL_ "GenSigTimeoutTime" BU_SG_REL_ DashCAM SG_ 2600468496 NM_Gateway_NM_State 2000;
BA_REL_ "GenSigTimeoutTime" BU_SG_REL_ DashCAM SG_ 2600468595 NM_Info_El_NM_State 2000;
BA_REL_ "GenSigTimeoutTime" BU_SG_REL_ DashCAM SG_ 2600468644 NM_LSH_NM_State 2000;
BA_REL_ "GenSigTimeoutTime" BU_SG_REL_ DashCAM SG_ 2600468491 NM_RDK_NM_State 2000;
BA_REL_ "GenSigTimeoutTime" BU_SG_REL_ DashCAM SG_ 2600468586 NM_STH_NM_State 2000;
BA_REL_ "GenSigTimeoutTime" BU_SG_REL_ DashCAM SG_ 913 OBD_Driving_Cycle 1000;
BA_REL_ "GenSigTimeoutTime" BU_SG_REL_ Gateway_Max SG_ 2600468595 NM_Info_El_CBV_AWB 2000;
BA_REL_ "GenSigTimeoutTime" BU_SG_REL_ Gateway_Max SG_ 2600468595 NM_Info_El_CBV_CRI 2000;
BA_REL_ "GenSigTimeoutTime" BU_SG_REL_ Gateway_Max SG_ 2600468595 NM_Info_El_Car_Wakeup 2000;
BA_REL_ "GenSigTimeoutTime" BU_SG_REL_ Gateway_Max SG_ 2600468595 NM_Info_El_CAB_V14 2000;
BA_REL_ "GenSigTimeoutTime" BU_SG_REL_ Gateway_Max SG_ 2600468644 NM_LSH_CBV_AWB 2000;
BA_REL_ "GenSigTimeoutTime" BU_SG_REL_ Gateway_Max SG_ 2600468644 NM_LSH_CBV_CRI 2000;
BA_REL_ "GenSigTimeoutTime" BU_SG_REL_ Gateway_Max SG_ 2600468644 NM_LSH_Car_Wakeup 2000;
BA_REL_ "GenSigTimeoutTime" BU_SG_REL_ Gateway_Max SG_ 2600468644 NM_LSH_CAB_V14 2000;
BA_REL_ "GenSigTimeoutTime" BU_SG_REL_ Gateway_Max SG_ 2600468491 NM_RDK_CBV_AWB 2000;
BA_REL_ "GenSigTimeoutTime" BU_SG_REL_ Gateway_Max SG_ 2600468491 NM_RDK_CBV_CRI 2000;
BA_REL_ "GenSigTimeoutTime" BU_SG_REL_ Gateway_Max SG_ 2600468491 NM_RDK_Car_Wakeup 2000;
BA_REL_ "GenSigTimeoutTime" BU_SG_REL_ Gateway_Max SG_ 2600468491 NM_RDK_CAB_V14 2000;
BA_REL_ "GenSigTimeoutTime" BU_SG_REL_ Gateway_Max SG_ 2600468586 NM_STH_CBV_AWB 2000;
BA_REL_ "GenSigTimeoutTime" BU_SG_REL_ Gateway_Max SG_ 2600468586 NM_STH_CBV_CRI 2000;
BA_REL_ "GenSigTimeoutTime" BU_SG_REL_ Gateway_Max SG_ 2600468586 NM_STH_Car_Wakeup 2000;
BA_REL_ "GenSigTimeoutTime" BU_SG_REL_ Gateway_Max SG_ 2600468586 NM_STH_CAB_V14 2000;
BA_REL_ "GenSigTimeoutTime" BU_SG_REL_ Gateway_Max SG_ 1122 PSD_Segment_ID 1500;
BA_REL_ "GenSigTimeoutTime" BU_SG_REL_ Gateway_Max SG_ 1122 PSD_Vorgaenger_Segment_ID 1500;
BA_REL_ "GenSigTimeoutTime" BU_SG_REL_ Gateway_Max SG_ 1122 PSD_Segmentlaenge 1500;
BA_REL_ "GenSigTimeoutTime" BU_SG_REL_ Gateway_Max SG_ 1122 PSD_Strassenkategorie 1500;
BA_REL_ "GenSigTimeoutTime" BU_SG_REL_ Gateway_Max SG_ 1122 PSD_Endkruemmung 1500;
BA_REL_ "GenSigTimeoutTime" BU_SG_REL_ Gateway_Max SG_ 1122 PSD_Endkruemmung_Vorz 1500;
BA_REL_ "GenSigTimeoutTime" BU_SG_REL_ Gateway_Max SG_ 1122 PSD_Idenditaets_ID 1500;
BA_REL_ "GenSigTimeoutTime" BU_SG_REL_ Gateway_Max SG_ 1122 PSD_ADAS_Qualitaet 1500;
BA_REL_ "GenSigTimeoutTime" BU_SG_REL_ Gateway_Max SG_ 1122 PSD_wahrscheinlichster_Pfad 1500;
BA_REL_ "GenSigTimeoutTime" BU_SG_REL_ Gateway_Max SG_ 1122 PSD_Geradester_Pfad 1500;
BA_REL_ "GenSigTimeoutTime" BU_SG_REL_ Gateway_Max SG_ 1122 PSD_Fahrspuren_Anzahl 1500;
BA_REL_ "GenSigTimeoutTime" BU_SG_REL_ Gateway_Max SG_ 1122 PSD_Bebauung 1500;
BA_REL_ "GenSigTimeoutTime" BU_SG_REL_ Gateway_Max SG_ 1122 PSD_Segment_Komplett 1500;
BA_REL_ "GenSigTimeoutTime" BU_SG_REL_ Gateway_Max SG_ 1122 PSD_Rampe 1500;
BA_REL_ "GenSigTimeoutTime" BU_SG_REL_ Gateway_Max SG_ 1122 PSD_Anfangskruemmung 1500;
BA_REL_ "GenSigTimeoutTime" BU_SG_REL_ Gateway_Max SG_ 1122 PSD_Anfangskruemmung_Vorz 1500;
BA_REL_ "GenSigTimeoutTime" BU_SG_REL_ Gateway_Max SG_ 1122 PSD_Abzweigerichtung 1500;
BA_REL_ "GenSigTimeoutTime" BU_SG_REL_ Gateway_Max SG_ 1122 PSD_Abzweigewinkel 1500;
BA_REL_ "GenSigTimeoutTime" BU_SG_REL_ Gateway_Max SG_ 1123 PSD_Pos_Segment_ID 1500;
BA_REL_ "GenSigTimeoutTime" BU_SG_REL_ Gateway_Max SG_ 1123 PSD_Pos_Segmentlaenge 1500;
BA_REL_ "GenSigTimeoutTime" BU_SG_REL_ Gateway_Max SG_ 1123 PSD_Pos_Inhibitzeit 1500;
BA_REL_ "GenSigTimeoutTime" BU_SG_REL_ Gateway_Max SG_ 1123 PSD_Pos_Standort_Eindeutig 1500;
BA_REL_ "GenSigTimeoutTime" BU_SG_REL_ Gateway_Max SG_ 1123 PSD_Pos_Fehler_Laengsrichtung 1500;
BA_REL_ "GenSigTimeoutTime" BU_SG_REL_ Gateway_Max SG_ 1123 PSD_Pos_Fahrspur 1500;
BA_REL_ "GenSigTimeoutTime" BU_SG_REL_ Gateway_Max SG_ 1123 PSD_Attribut_Segment_ID_05 1500;
BA_REL_ "GenSigTimeoutTime" BU_SG_REL_ Gateway_Max SG_ 1123 PSD_Attribut_1_ID 1500;
BA_REL_ "GenSigTimeoutTime" BU_SG_REL_ Gateway_Max SG_ 1123 PSD_Attribut_1_Wert 1500;
BA_REL_ "GenSigTimeoutTime" BU_SG_REL_ Gateway_Max SG_ 1123 PSD_Attribut_1_Offset 1500;
BA_REL_ "GenSigTimeoutTime" BU_SG_REL_ Gateway_Max SG_ 1123 PSD_Attribut_2_ID 1500;
BA_REL_ "GenSigTimeoutTime" BU_SG_REL_ Gateway_Max SG_ 1123 PSD_Attribut_2_Wert 1500;
BA_REL_ "GenSigTimeoutTime" BU_SG_REL_ Gateway_Max SG_ 1123 PSD_Attribut_2_Offset 1500;
BA_REL_ "GenSigTimeoutTime" BU_SG_REL_ Gateway_Max SG_ 1123 PSD_Attribute_Komplett_05 1500;
BA_REL_ "GenSigTimeoutTime" BU_SG_REL_ Gateway_Max SG_ 1124 PSD_06_Mux 1500;
BA_REL_ "GenSigTimeoutTime" BU_SG_REL_ Gateway_Max SG_ 1124 PSD_Sys_Segment_ID 1500;
BA_REL_ "GenSigTimeoutTime" BU_SG_REL_ Gateway_Max SG_ 1124 PSD_Attribut_Segment_ID 1500;
BA_REL_ "GenSigTimeoutTime" BU_SG_REL_ Gateway_Max SG_ 1124 PSD_Ges_Segment_ID 1500;
BA_REL_ "GenSigTimeoutTime" BU_SG_REL_ Gateway_Max SG_ 1124 PSD_Baum_Laenge_VZ 1500;
BA_REL_ "GenSigTimeoutTime" BU_SG_REL_ Gateway_Max SG_ 1124 PSD_Steigung_1_Segment_ID 1500;
BA_REL_ "GenSigTimeoutTime" BU_SG_REL_ Gateway_Max SG_ 1124 PSD_Baum_Laenge 1500;
BA_REL_ "GenSigTimeoutTime" BU_SG_REL_ Gateway_Max SG_ 1124 PSD_Sys_Laendercode 1500;
BA_REL_ "GenSigTimeoutTime" BU_SG_REL_ Gateway_Max SG_ 1124 PSD_Attribut_3_ID 1500;
BA_REL_ "GenSigTimeoutTime" BU_SG_REL_ Gateway_Max SG_ 1124 PSD_Ges_Offset 1500;
BA_REL_ "GenSigTimeoutTime" BU_SG_REL_ Gateway_Max SG_ 1124 PSD_Steigung_1_A_Steigung 1500;
BA_REL_ "GenSigTimeoutTime" BU_SG_REL_ Gateway_Max SG_ 1124 PSD_Attribut_3_Offset 1500;
BA_REL_ "GenSigTimeoutTime" BU_SG_REL_ Gateway_Max SG_ 1124 PSD_Ges_Geschwindigkeit 1500;
BA_REL_ "GenSigTimeoutTime" BU_SG_REL_ Gateway_Max SG_ 1124 PSD_Steigung_1_A_Vorz 1500;
BA_REL_ "GenSigTimeoutTime" BU_SG_REL_ Gateway_Max SG_ 1124 PSD_Sys_Geschwindigkeit_Einheit 1500;
BA_REL_ "GenSigTimeoutTime" BU_SG_REL_ Gateway_Max SG_ 1124 PSD_Steigung_1_A_Offset 1500;
BA_REL_ "GenSigTimeoutTime" BU_SG_REL_ Gateway_Max SG_ 1124 PSD_Sys_Verkehrsrichtung 1500;
BA_REL_ "GenSigTimeoutTime" BU_SG_REL_ Gateway_Max SG_ 1124 PSD_Sys_Geometrieguete 1500;
BA_REL_ "GenSigTimeoutTime" BU_SG_REL_ Gateway_Max SG_ 1124 PSD_Sys_Mapmatchingguete 1500;
BA_REL_ "GenSigTimeoutTime" BU_SG_REL_ Gateway_Max SG_ 1124 PSD_Attribut_3_Wert 1500;
BA_REL_ "GenSigTimeoutTime" BU_SG_REL_ Gateway_Max SG_ 1124 PSD_Ges_Typ 1500;
BA_REL_ "GenSigTimeoutTime" BU_SG_REL_ Gateway_Max SG_ 1124 PSD_Sys_Alter_Karte 1500;
BA_REL_ "GenSigTimeoutTime" BU_SG_REL_ Gateway_Max SG_ 1124 PSD_Ges_Spur_Geschw_Begrenzung 1500;
BA_REL_ "GenSigTimeoutTime" BU_SG_REL_ Gateway_Max SG_ 1124 PSD_Steigung_1_B_Steigung 1500;
BA_REL_ "GenSigTimeoutTime" BU_SG_REL_ Gateway_Max SG_ 1124 PSD_Attribut_4_ID 1500;
BA_REL_ "GenSigTimeoutTime" BU_SG_REL_ Gateway_Max SG_ 1124 PSD_Sys_Zielfuehrung 1500;
BA_REL_ "GenSigTimeoutTime" BU_SG_REL_ Gateway_Max SG_ 1124 PSD_Sys_US_State 1500;
BA_REL_ "GenSigTimeoutTime" BU_SG_REL_ Gateway_Max SG_ 1124 PSD_Ges_Geschwindigkeit_Gespann 1500;
BA_REL_ "GenSigTimeoutTime" BU_SG_REL_ Gateway_Max SG_ 1124 PSD_Baum_Breite_VZ 1500;
BA_REL_ "GenSigTimeoutTime" BU_SG_REL_ Gateway_Max SG_ 1124 PSD_Attribut_4_Wert 1500;
BA_REL_ "GenSigTimeoutTime" BU_SG_REL_ Gateway_Max SG_ 1124 PSD_Baum_Breite 1500;
BA_REL_ "GenSigTimeoutTime" BU_SG_REL_ Gateway_Max SG_ 1124 PSD_Ges_Geschwindigkeit_Witter 1500;
BA_REL_ "GenSigTimeoutTime" BU_SG_REL_ Gateway_Max SG_ 1124 PSD_Steigung_1_B_Vorz 1500;
BA_REL_ "GenSigTimeoutTime" BU_SG_REL_ Gateway_Max SG_ 1124 PSD_Steigung_1_B_Offset 1500;
BA_REL_ "GenSigTimeoutTime" BU_SG_REL_ Gateway_Max SG_ 1124 PSD_Sys_Quali_Geometrien 1500;
BA_REL_ "GenSigTimeoutTime" BU_SG_REL_ Gateway_Max SG_ 1124 PSD_Ges_Geschwindigkeit_Tag_Anf 1500;
BA_REL_ "GenSigTimeoutTime" BU_SG_REL_ Gateway_Max SG_ 1124 PSD_Attribut_4_Offset 1500;
BA_REL_ "GenSigTimeoutTime" BU_SG_REL_ Gateway_Max SG_ 1124 PSD_Sys_Quali_Ortsinfo 1500;
BA_REL_ "GenSigTimeoutTime" BU_SG_REL_ Gateway_Max SG_ 1124 PSD_Ges_Geschwindigkeit_Tag_Ende 1500;
BA_REL_ "GenSigTimeoutTime" BU_SG_REL_ Gateway_Max SG_ 1124 PSD_Sys_Quali_verfuegbar 1500;
BA_REL_ "GenSigTimeoutTime" BU_SG_REL_ Gateway_Max SG_ 1124 PSD_Sys_Zielfuehrung_geaendert 1500;
BA_REL_ "GenSigTimeoutTime" BU_SG_REL_ Gateway_Max SG_ 1124 PSD_Ges_Geschwindigkeit_Std_Anf 1500;
BA_REL_ "GenSigTimeoutTime" BU_SG_REL_ Gateway_Max SG_ 1124 PSD_Steigung_1_Attribute_kompl 1500;
BA_REL_ "GenSigTimeoutTime" BU_SG_REL_ Gateway_Max SG_ 1124 PSD_Sys_Geometrieguete_erweitert 1500;
BA_REL_ "GenSigTimeoutTime" BU_SG_REL_ Gateway_Max SG_ 1124 PSD_Steigung_2_Segment_ID 1500;
BA_REL_ "GenSigTimeoutTime" BU_SG_REL_ Gateway_Max SG_ 1124 PSD_Attribut_5_ID 1500;
BA_REL_ "GenSigTimeoutTime" BU_SG_REL_ Gateway_Max SG_ 1124 PSD_Ges_Geschwindigkeit_Std_Ende 1500;
BA_REL_ "GenSigTimeoutTime" BU_SG_REL_ Gateway_Max SG_ 1124 PSD_Attribut_5_Offset 1500;
BA_REL_ "GenSigTimeoutTime" BU_SG_REL_ Gateway_Max SG_ 1124 PSD_Steigung_2_Steigung 1500;
BA_REL_ "GenSigTimeoutTime" BU_SG_REL_ Gateway_Max SG_ 1124 PSD_Sys_Quali_sonstige_Attribute 1500;
BA_REL_ "GenSigTimeoutTime" BU_SG_REL_ Gateway_Max SG_ 1124 PSD_Ges_Ueberholverbot 1500;
BA_REL_ "GenSigTimeoutTime" BU_SG_REL_ Gateway_Max SG_ 1124 PSD_Sys_Quali_Steigungen 1500;
BA_REL_ "GenSigTimeoutTime" BU_SG_REL_ Gateway_Max SG_ 1124 PSD_Ges_Wechselverkehrszeichen 1500;
BA_REL_ "GenSigTimeoutTime" BU_SG_REL_ Gateway_Max SG_ 1124 PSD_Attribut_5_Wert 1500;
BA_REL_ "GenSigTimeoutTime" BU_SG_REL_ Gateway_Max SG_ 1124 PSD_Steigung_2_Vorz 1500;
BA_REL_ "GenSigTimeoutTime" BU_SG_REL_ Gateway_Max SG_ 1124 PSD_Sys_Quali_Strassenkennz 1500;
BA_REL_ "GenSigTimeoutTime" BU_SG_REL_ Gateway_Max SG_ 1124 PSD_Wechselverkehrszeichen_Typ 1500;
BA_REL_ "GenSigTimeoutTime" BU_SG_REL_ Gateway_Max SG_ 1124 PSD_Baum_Ausrichtung 1500;
BA_REL_ "GenSigTimeoutTime" BU_SG_REL_ Gateway_Max SG_ 1124 PSD_Steigung_2_Offset 1500;
BA_REL_ "GenSigTimeoutTime" BU_SG_REL_ Gateway_Max SG_ 1124 PSD_Ges_Gesetzlich_Kategorie 1500;
BA_REL_ "GenSigTimeoutTime" BU_SG_REL_ Gateway_Max SG_ 1124 PSD_Sys_Quali_Tempolimits 1500;
BA_REL_ "GenSigTimeoutTime" BU_SG_REL_ Gateway_Max SG_ 1124 PSD_Attribute_Komplett_06 1500;
BA_REL_ "GenSigTimeoutTime" BU_SG_REL_ Gateway_Max SG_ 1124 PSD_Ges_Gesetzlich_Zusatz 1500;
BA_REL_ "GenSigTimeoutTime" BU_SG_REL_ Gateway_Max SG_ 1124 PSD_Sys_Quali_Vorfahrtsregelung 1500;
BA_REL_ "GenSigTimeoutTime" BU_SG_REL_ Gateway_Max SG_ 1124 PSD_Ges_Verkehrszeichen_Quelle 1500;
BA_REL_ "GenSigTimeoutTime" BU_SG_REL_ Gateway_Max SG_ 1124 PSD_Steigung_2_Attribute_kompl 1500;
BA_REL_ "GenSigTimeoutTime" BU_SG_REL_ Gateway_Max SG_ 1124 PSD_Ges_Attribute_Komplett 1500;
BA_REL_ "GenSigTimeoutTime" BU_SG_REL_ ICC_IO_Node SG_ 2600468496 NM_Gateway_NM_State 2000;
BA_REL_ "GenSigTimeoutTime" BU_SG_REL_ ICC_IO_Node SG_ 2600468496 NM_Gateway_Car_Wakeup 2000;
BA_REL_ "GenSigTimeoutTime" BU_SG_REL_ ICC_IO_Node SG_ 2600468644 NM_LSH_NM_State 2000;
BA_REL_ "GenSigTimeoutTime" BU_SG_REL_ ICC_IO_Node SG_ 2600468491 NM_RDK_NM_State 2000;
BA_REL_ "GenSigTimeoutTime" BU_SG_REL_ ICC_IO_Node SG_ 2600468586 NM_STH_NM_State 2000;
BA_REL_ "GenSigTimeoutTime" BU_SG_REL_ ICC_IO_Node SG_ 913 OBD_Driving_Cycle 1000;
BA_REL_ "GenSigTimeoutTime" BU_SG_REL_ ICC_IO_Node SG_ 913 OBD_Warm_Up_Cycle 1000;
BA_REL_ "GenSigTimeoutTime" BU_SG_REL_ ICC_IO_Node SG_ 2589283656 ORU_Status 5000;
BA_REL_ "GenSigTimeoutTime" BU_SG_REL_ LSH SG_ 2600468496 NM_Gateway_NM_State 2000;
BA_REL_ "GenSigTimeoutTime" BU_SG_REL_ LSH SG_ 2600468595 NM_Info_El_NM_State 2000;
BA_REL_ "GenSigTimeoutTime" BU_SG_REL_ LSH SG_ 2600468491 NM_RDK_NM_State 2000;
BA_REL_ "GenSigTimeoutTime" BU_SG_REL_ LSH SG_ 2600468586 NM_STH_NM_State 2000;
BA_REL_ "GenSigTimeoutTime" BU_SG_REL_ OCU SG_ 2600468496 NM_Gateway_NM_State 2000;
BA_REL_ "GenSigTimeoutTime" BU_SG_REL_ OCU SG_ 2600468595 NM_Info_El_NM_State 2000;
BA_REL_ "GenSigTimeoutTime" BU_SG_REL_ OCU SG_ 2600468644 NM_LSH_NM_State 2000;
BA_REL_ "GenSigTimeoutTime" BU_SG_REL_ OCU SG_ 2600468491 NM_RDK_NM_State 2000;
BA_REL_ "GenSigTimeoutTime" BU_SG_REL_ OCU SG_ 2600468586 NM_STH_NM_State 2000;
BA_REL_ "GenSigTimeoutTime" BU_SG_REL_ OCU SG_ 913 OBD_Calc_Load_Val 1000;
BA_REL_ "GenSigTimeoutTime" BU_SG_REL_ OCU SG_ 913 OBD_Abs_Throttle_Pos 1000;
BA_REL_ "GenSigTimeoutTime" BU_SG_REL_ OCU SG_ 913 OBD_Abs_Load_Val 1000;
BA_REL_ "GenSigTimeoutTime" BU_SG_REL_ OCU SG_ 913 OBD_Abs_Pedal_Pos 1000;
BA_REL_ "GenSigTimeoutTime" BU_SG_REL_ OCU SG_ 913 MO_Servicemodus 1000;
BA_REL_ "GenSigTimeoutTime" BU_SG_REL_ OCU SG_ 913 MO_QBit_Aussen_Temp 1000;
BA_REL_ "GenSigTimeoutTime" BU_SG_REL_ OCU SG_ 913 OBD_Warm_Up_Cycle 1000;
BA_REL_ "GenSigTimeoutTime" BU_SG_REL_ OCU SG_ 2589283656 ORU_Status 5000;
BA_REL_ "GenSigTimeoutTime" BU_SG_REL_ OCU SG_ 1175 PH_Anf_Audioabsenkung 1000;
BA_REL_ "GenSigTimeoutTime" BU_SG_REL_ OCU SG_ 1355 RBFMA_PaCo_BrakeIntervention 5000;
BA_REL_ "GenSigTimeoutTime" BU_SG_REL_ OCU SG_ 1355 RBFMA_PaCo_MainState 5000;
BA_REL_ "GenSigTimeoutTime" BU_SG_REL_ OCU SG_ 1355 PH_Verschmutzungsmeldung 5000;
BA_REL_ "GenSigTimeoutTime" BU_SG_REL_ OCU SG_ 1355 PH_Ton_Ausgabe 5000;
BA_REL_ "GenSigTimeoutTime" BU_SG_REL_ OCU SG_ 1355 PH_Ton_Pausenlaenge 5000;
BA_REL_ "GenSigTimeoutTime" BU_SG_REL_ OCU SG_ 1355 APSOPS_PaCo_ObstacleDetectRear 5000;
BA_REL_ "GenSigTimeoutTime" BU_SG_REL_ OCU SG_ 1355 APSOPS_PaCo_ObstacleDetectFront 5000;
BA_REL_ "GenSigTimeoutTime" BU_SG_REL_ OCU SG_ 1355 APSOPS_PaCo_Button 5000;
BA_REL_ "GenSigTimeoutTime" BU_SG_REL_ OCU SG_ 1355 APSOPS_PaCo_MainState 5000;
BA_REL_ "GenSigTimeoutTime" BU_SG_REL_ OCU SG_ 1355 APSOPS_PaCo_FunctionState 5000;
BA_REL_ "GenSigTimeoutTime" BU_SG_REL_ OCU SG_ 1355 APSOPS_PaCo_ApproachingRear 5000;
BA_REL_ "GenSigTimeoutTime" BU_SG_REL_ OCU SG_ 1355 APSOPS_PaCo_ApproachingFront 5000;
BA_REL_ "GenSigTimeoutTime" BU_SG_REL_ OCU SG_ 1355 APS_PaCo_WarningTones 5000;
BA_REL_ "GenSigTimeoutTime" BU_SG_REL_ OCU SG_ 1355 PH_Ton_Richtung 5000;
BA_REL_ "GenSigTimeoutTime" BU_SG_REL_ OCU SG_ 1355 PH_Ton_Lautstaerke 5000;
BA_REL_ "GenSigTimeoutTime" BU_SG_REL_ OCU SG_ 2527679498 Perso_Kontonummer 5000;
BA_REL_ "GenSigTimeoutTime" BU_SG_REL_ OCU SG_ 2527679498 Perso_Steuerung 5000;
BA_REL_ "GenSigTimeoutTime" BU_SG_REL_ OCU SG_ 2527679498 Perso_Steuerungsparameter 5000;
BA_REL_ "GenSigTimeoutTime" BU_SG_REL_ OCU SG_ 2527679498 Perso_Status 5000;
BA_REL_ "GenSigTimeoutTime" BU_SG_REL_ OCU SG_ 2527679498 Perso_Bedienstelle 5000;
BA_REL_ "GenSigTimeoutTime" BU_SG_REL_ OCU SG_ 2527679498 Perso_Freigabe_Verstellung 5000;
BA_REL_ "GenSigTimeoutTime" BU_SG_REL_ OCU SG_ 2527679498 Perso_Aktiv 5000;
BA_REL_ "GenSigTimeoutTime" BU_SG_REL_ OCU SG_ 2527679498 IAA_PSO_wake_up 5000;
BA_REL_ "GenSigTimeoutTime" BU_SG_REL_ OCU SG_ 2527679498 Perso_Fahrernummer 5000;
BA_REL_ "GenSigTimeoutTime" BU_SG_REL_ OCU SG_ 2527679498 Perso_Schreibschutz 5000;
BA_REL_ "GenSigTimeoutTime" BU_SG_REL_ OCU SG_ 2527679498 IAA_Active_User_ID 5000;
BA_REL_ "GenSigTimeoutTime" BU_SG_REL_ OCU SG_ 2527679498 IAA_Identified_User_ID 5000;
BA_REL_ "GenSigTimeoutTime" BU_SG_REL_ OCU SG_ 319 SC_PreCrash_Warnung 2000;
BA_REL_ "GenSigTimeoutTime" BU_SG_REL_ OCU SG_ 1122 PSD_Segment_ID 1500;
BA_REL_ "GenSigTimeoutTime" BU_SG_REL_ OCU SG_ 1122 PSD_Vorgaenger_Segment_ID 1500;
BA_REL_ "GenSigTimeoutTime" BU_SG_REL_ OCU SG_ 1122 PSD_Segmentlaenge 1500;
BA_REL_ "GenSigTimeoutTime" BU_SG_REL_ OCU SG_ 1122 PSD_Strassenkategorie 1500;
BA_REL_ "GenSigTimeoutTime" BU_SG_REL_ OCU SG_ 1122 PSD_Endkruemmung 1500;
BA_REL_ "GenSigTimeoutTime" BU_SG_REL_ OCU SG_ 1122 PSD_Endkruemmung_Vorz 1500;
BA_REL_ "GenSigTimeoutTime" BU_SG_REL_ OCU SG_ 1122 PSD_Idenditaets_ID 1500;
BA_REL_ "GenSigTimeoutTime" BU_SG_REL_ OCU SG_ 1122 PSD_ADAS_Qualitaet 1500;
BA_REL_ "GenSigTimeoutTime" BU_SG_REL_ OCU SG_ 1122 PSD_wahrscheinlichster_Pfad 1500;
BA_REL_ "GenSigTimeoutTime" BU_SG_REL_ OCU SG_ 1122 PSD_Geradester_Pfad 1500;
BA_REL_ "GenSigTimeoutTime" BU_SG_REL_ OCU SG_ 1122 PSD_Fahrspuren_Anzahl 1500;
BA_REL_ "GenSigTimeoutTime" BU_SG_REL_ OCU SG_ 1122 PSD_Bebauung 1500;
BA_REL_ "GenSigTimeoutTime" BU_SG_REL_ OCU SG_ 1122 PSD_Segment_Komplett 1500;
BA_REL_ "GenSigTimeoutTime" BU_SG_REL_ OCU SG_ 1122 PSD_Rampe 1500;
BA_REL_ "GenSigTimeoutTime" BU_SG_REL_ OCU SG_ 1122 PSD_Anfangskruemmung 1500;
BA_REL_ "GenSigTimeoutTime" BU_SG_REL_ OCU SG_ 1122 PSD_Anfangskruemmung_Vorz 1500;
BA_REL_ "GenSigTimeoutTime" BU_SG_REL_ OCU SG_ 1122 PSD_Abzweigerichtung 1500;
BA_REL_ "GenSigTimeoutTime" BU_SG_REL_ OCU SG_ 1122 PSD_Abzweigewinkel 1500;
BA_REL_ "GenSigTimeoutTime" BU_SG_REL_ OCU SG_ 1123 PSD_Pos_Segment_ID 1500;
BA_REL_ "GenSigTimeoutTime" BU_SG_REL_ OCU SG_ 1123 PSD_Pos_Fahrspur 1500;
BA_REL_ "GenSigTimeoutTime" BU_SG_REL_ OCU SG_ 1124 PSD_06_Mux 1500;
BA_REL_ "GenSigTimeoutTime" BU_SG_REL_ OCU SG_ 1124 PSD_Sys_Segment_ID 1500;
BA_REL_ "GenSigTimeoutTime" BU_SG_REL_ OCU SG_ 1124 PSD_Attribut_Segment_ID 1500;
BA_REL_ "GenSigTimeoutTime" BU_SG_REL_ OCU SG_ 1124 PSD_Ges_Segment_ID 1500;
BA_REL_ "GenSigTimeoutTime" BU_SG_REL_ OCU SG_ 1124 PSD_Baum_Laenge_VZ 1500;
BA_REL_ "GenSigTimeoutTime" BU_SG_REL_ OCU SG_ 1124 PSD_Steigung_1_Segment_ID 1500;
BA_REL_ "GenSigTimeoutTime" BU_SG_REL_ OCU SG_ 1124 PSD_Baum_Laenge 1500;
BA_REL_ "GenSigTimeoutTime" BU_SG_REL_ OCU SG_ 1124 PSD_Sys_Laendercode 1500;
BA_REL_ "GenSigTimeoutTime" BU_SG_REL_ OCU SG_ 1124 PSD_Attribut_3_ID 1500;
BA_REL_ "GenSigTimeoutTime" BU_SG_REL_ OCU SG_ 1124 PSD_Ges_Offset 1500;
BA_REL_ "GenSigTimeoutTime" BU_SG_REL_ OCU SG_ 1124 PSD_Steigung_1_A_Steigung 1500;
BA_REL_ "GenSigTimeoutTime" BU_SG_REL_ OCU SG_ 1124 PSD_Attribut_3_Offset 1500;
BA_REL_ "GenSigTimeoutTime" BU_SG_REL_ OCU SG_ 1124 PSD_Ges_Geschwindigkeit 1500;
BA_REL_ "GenSigTimeoutTime" BU_SG_REL_ OCU SG_ 1124 PSD_Steigung_1_A_Vorz 1500;
BA_REL_ "GenSigTimeoutTime" BU_SG_REL_ OCU SG_ 1124 PSD_Sys_Geschwindigkeit_Einheit 1500;
BA_REL_ "GenSigTimeoutTime" BU_SG_REL_ OCU SG_ 1124 PSD_Steigung_1_A_Offset 1500;
BA_REL_ "GenSigTimeoutTime" BU_SG_REL_ OCU SG_ 1124 PSD_Sys_Verkehrsrichtung 1500;
BA_REL_ "GenSigTimeoutTime" BU_SG_REL_ OCU SG_ 1124 PSD_Sys_Geometrieguete 1500;
BA_REL_ "GenSigTimeoutTime" BU_SG_REL_ OCU SG_ 1124 PSD_Sys_Mapmatchingguete 1500;
BA_REL_ "GenSigTimeoutTime" BU_SG_REL_ OCU SG_ 1124 PSD_Attribut_3_Wert 1500;
BA_REL_ "GenSigTimeoutTime" BU_SG_REL_ OCU SG_ 1124 PSD_Ges_Typ 1500;
BA_REL_ "GenSigTimeoutTime" BU_SG_REL_ OCU SG_ 1124 PSD_Sys_Alter_Karte 1500;
BA_REL_ "GenSigTimeoutTime" BU_SG_REL_ OCU SG_ 1124 PSD_Ges_Spur_Geschw_Begrenzung 1500;
BA_REL_ "GenSigTimeoutTime" BU_SG_REL_ OCU SG_ 1124 PSD_Steigung_1_B_Steigung 1500;
BA_REL_ "GenSigTimeoutTime" BU_SG_REL_ OCU SG_ 1124 PSD_Attribut_4_ID 1500;
BA_REL_ "GenSigTimeoutTime" BU_SG_REL_ OCU SG_ 1124 PSD_Sys_Zielfuehrung 1500;
BA_REL_ "GenSigTimeoutTime" BU_SG_REL_ OCU SG_ 1124 PSD_Sys_US_State 1500;
BA_REL_ "GenSigTimeoutTime" BU_SG_REL_ OCU SG_ 1124 PSD_Ges_Geschwindigkeit_Gespann 1500;
BA_REL_ "GenSigTimeoutTime" BU_SG_REL_ OCU SG_ 1124 PSD_Baum_Breite_VZ 1500;
BA_REL_ "GenSigTimeoutTime" BU_SG_REL_ OCU SG_ 1124 PSD_Attribut_4_Wert 1500;
BA_REL_ "GenSigTimeoutTime" BU_SG_REL_ OCU SG_ 1124 PSD_Baum_Breite 1500;
BA_REL_ "GenSigTimeoutTime" BU_SG_REL_ OCU SG_ 1124 PSD_Ges_Geschwindigkeit_Witter 1500;
BA_REL_ "GenSigTimeoutTime" BU_SG_REL_ OCU SG_ 1124 PSD_Steigung_1_B_Vorz 1500;
BA_REL_ "GenSigTimeoutTime" BU_SG_REL_ OCU SG_ 1124 PSD_Steigung_1_B_Offset 1500;
BA_REL_ "GenSigTimeoutTime" BU_SG_REL_ OCU SG_ 1124 PSD_Sys_Quali_Geometrien 1500;
BA_REL_ "GenSigTimeoutTime" BU_SG_REL_ OCU SG_ 1124 PSD_Ges_Geschwindigkeit_Tag_Anf 1500;
BA_REL_ "GenSigTimeoutTime" BU_SG_REL_ OCU SG_ 1124 PSD_Attribut_4_Offset 1500;
BA_REL_ "GenSigTimeoutTime" BU_SG_REL_ OCU SG_ 1124 PSD_Sys_Quali_Ortsinfo 1500;
BA_REL_ "GenSigTimeoutTime" BU_SG_REL_ OCU SG_ 1124 PSD_Ges_Geschwindigkeit_Tag_Ende 1500;
BA_REL_ "GenSigTimeoutTime" BU_SG_REL_ OCU SG_ 1124 PSD_Sys_Quali_verfuegbar 1500;
BA_REL_ "GenSigTimeoutTime" BU_SG_REL_ OCU SG_ 1124 PSD_Sys_Zielfuehrung_geaendert 1500;
BA_REL_ "GenSigTimeoutTime" BU_SG_REL_ OCU SG_ 1124 PSD_Ges_Geschwindigkeit_Std_Anf 1500;
BA_REL_ "GenSigTimeoutTime" BU_SG_REL_ OCU SG_ 1124 PSD_Steigung_1_Attribute_kompl 1500;
BA_REL_ "GenSigTimeoutTime" BU_SG_REL_ OCU SG_ 1124 PSD_Sys_Geometrieguete_erweitert 1500;
BA_REL_ "GenSigTimeoutTime" BU_SG_REL_ OCU SG_ 1124 PSD_Steigung_2_Segment_ID 1500;
BA_REL_ "GenSigTimeoutTime" BU_SG_REL_ OCU SG_ 1124 PSD_Attribut_5_ID 1500;
BA_REL_ "GenSigTimeoutTime" BU_SG_REL_ OCU SG_ 1124 PSD_Ges_Geschwindigkeit_Std_Ende 1500;
BA_REL_ "GenSigTimeoutTime" BU_SG_REL_ OCU SG_ 1124 PSD_Attribut_5_Offset 1500;
BA_REL_ "GenSigTimeoutTime" BU_SG_REL_ OCU SG_ 1124 PSD_Steigung_2_Steigung 1500;
BA_REL_ "GenSigTimeoutTime" BU_SG_REL_ OCU SG_ 1124 PSD_Sys_Quali_sonstige_Attribute 1500;
BA_REL_ "GenSigTimeoutTime" BU_SG_REL_ OCU SG_ 1124 PSD_Ges_Ueberholverbot 1500;
BA_REL_ "GenSigTimeoutTime" BU_SG_REL_ OCU SG_ 1124 PSD_Sys_Quali_Steigungen 1500;
BA_REL_ "GenSigTimeoutTime" BU_SG_REL_ OCU SG_ 1124 PSD_Ges_Wechselverkehrszeichen 1500;
BA_REL_ "GenSigTimeoutTime" BU_SG_REL_ OCU SG_ 1124 PSD_Attribut_5_Wert 1500;
BA_REL_ "GenSigTimeoutTime" BU_SG_REL_ OCU SG_ 1124 PSD_Steigung_2_Vorz 1500;
BA_REL_ "GenSigTimeoutTime" BU_SG_REL_ OCU SG_ 1124 PSD_Sys_Quali_Strassenkennz 1500;
BA_REL_ "GenSigTimeoutTime" BU_SG_REL_ OCU SG_ 1124 PSD_Wechselverkehrszeichen_Typ 1500;
BA_REL_ "GenSigTimeoutTime" BU_SG_REL_ OCU SG_ 1124 PSD_Baum_Ausrichtung 1500;
BA_REL_ "GenSigTimeoutTime" BU_SG_REL_ OCU SG_ 1124 PSD_Steigung_2_Offset 1500;
BA_REL_ "GenSigTimeoutTime" BU_SG_REL_ OCU SG_ 1124 PSD_Ges_Gesetzlich_Kategorie 1500;
BA_REL_ "GenSigTimeoutTime" BU_SG_REL_ OCU SG_ 1124 PSD_Sys_Quali_Tempolimits 1500;
BA_REL_ "GenSigTimeoutTime" BU_SG_REL_ OCU SG_ 1124 PSD_Attribute_Komplett_06 1500;
BA_REL_ "GenSigTimeoutTime" BU_SG_REL_ OCU SG_ 1124 PSD_Ges_Gesetzlich_Zusatz 1500;
BA_REL_ "GenSigTimeoutTime" BU_SG_REL_ OCU SG_ 1124 PSD_Sys_Quali_Vorfahrtsregelung 1500;
BA_REL_ "GenSigTimeoutTime" BU_SG_REL_ OCU SG_ 1124 PSD_Ges_Verkehrszeichen_Quelle 1500;
BA_REL_ "GenSigTimeoutTime" BU_SG_REL_ OCU SG_ 1124 PSD_Steigung_2_Attribute_kompl 1500;
BA_REL_ "GenSigTimeoutTime" BU_SG_REL_ OCU SG_ 1124 PSD_Ges_Attribute_Komplett 1500;
BA_REL_ "GenSigTimeoutTime" BU_SG_REL_ OCU SG_ 1616 RA_Radio_on 5000;
BA_REL_ "GenSigTimeoutTime" BU_SG_REL_ OCU SG_ 1616 RA_Frequency 5000;
BA_REL_ "GenSigTimeoutTime" BU_SG_REL_ RDK_RS3 SG_ 2600468496 NM_Gateway_NM_State 2000;
BA_REL_ "GenSigTimeoutTime" BU_SG_REL_ RDK_RS3 SG_ 2600468595 NM_Info_El_NM_State 2000;
BA_REL_ "GenSigTimeoutTime" BU_SG_REL_ RDK_RS3 SG_ 2600468644 NM_LSH_NM_State 2000;
BA_REL_ "GenSigTimeoutTime" BU_SG_REL_ RDK_RS3 SG_ 2600468586 NM_STH_NM_State 2000;
BA_REL_ "GenSigTimeoutTime" BU_SG_REL_ Sound_MIB_ab_Gen3 SG_ 2600468496 NM_Gateway_NM_State 2000;
BA_REL_ "GenSigTimeoutTime" BU_SG_REL_ Sound_MIB_ab_Gen3 SG_ 2600468595 NM_Info_El_NM_State 2000;
BA_REL_ "GenSigTimeoutTime" BU_SG_REL_ Sound_MIB_ab_Gen3 SG_ 2600468644 NM_LSH_NM_State 2000;
BA_REL_ "GenSigTimeoutTime" BU_SG_REL_ Sound_MIB_ab_Gen3 SG_ 2600468491 NM_RDK_NM_State 2000;
BA_REL_ "GenSigTimeoutTime" BU_SG_REL_ Sound_MIB_ab_Gen3 SG_ 2600468586 NM_STH_NM_State 2000;
BA_REL_ "GenSigTimeoutTime" BU_SG_REL_ STH SG_ 2600468496 NM_Gateway_NM_State 2000;
BA_REL_ "GenSigTimeoutTime" BU_SG_REL_ STH SG_ 2600468595 NM_Info_El_NM_State 2000;
BA_REL_ "GenSigTimeoutTime" BU_SG_REL_ STH SG_ 2600468644 NM_LSH_NM_State 2000;
BA_REL_ "GenSigTimeoutTime" BU_SG_REL_ STH SG_ 2600468491 NM_RDK_NM_State 2000;
BA_REL_ "GenSigTimeoutTime" BU_SG_REL_ ZR_MIB_EINSTIEG_ab_Gen3 SG_ 2600468496 NM_Gateway_NM_State 2000;
BA_REL_ "GenSigTimeoutTime" BU_SG_REL_ ZR_MIB_EINSTIEG_ab_Gen3 SG_ 2600468496 NM_Gateway_Car_Wakeup 2000;
BA_REL_ "GenSigTimeoutTime" BU_SG_REL_ ZR_MIB_EINSTIEG_ab_Gen3 SG_ 2600468644 NM_LSH_NM_State 2000;
BA_REL_ "GenSigTimeoutTime" BU_SG_REL_ ZR_MIB_EINSTIEG_ab_Gen3 SG_ 2600468491 NM_RDK_NM_State 2000;
BA_REL_ "GenSigTimeoutTime" BU_SG_REL_ ZR_MIB_EINSTIEG_ab_Gen3 SG_ 2600468586 NM_STH_NM_State 2000;
BA_REL_ "GenSigTimeoutTime" BU_SG_REL_ ZR_MIB_EINSTIEG_ab_Gen3 SG_ 2589283909 NR_01_CAL_Text_Request 5000;
BA_REL_ "GenSigTimeoutTime" BU_SG_REL_ ZR_MIB_EINSTIEG_ab_Gen3 SG_ 2589283909 NR_01_CAL_Text_Data_1 5000;
BA_REL_ "GenSigTimeoutTime" BU_SG_REL_ ZR_MIB_EINSTIEG_ab_Gen3 SG_ 2589283910 NR_01_CAL_Text_Data_2 5000;
BA_REL_ "GenSigTimeoutTime" BU_SG_REL_ ZR_MIB_EINSTIEG_ab_Gen3 SG_ 2589283911 NR_01_CAL_Text_Data_3 5000;
BA_REL_ "GenSigTimeoutTime" BU_SG_REL_ ZR_MIB_EINSTIEG_ab_Gen3 SG_ 2589283912 NR_02_CAL_Text_Request 5000;
BA_REL_ "GenSigTimeoutTime" BU_SG_REL_ ZR_MIB_EINSTIEG_ab_Gen3 SG_ 2589283912 NR_02_CAL_Text_Data_1 5000;
BA_REL_ "GenSigTimeoutTime" BU_SG_REL_ ZR_MIB_EINSTIEG_ab_Gen3 SG_ 2589283913 NR_02_CAL_Text_Data_2 5000;
BA_REL_ "GenSigTimeoutTime" BU_SG_REL_ ZR_MIB_EINSTIEG_ab_Gen3 SG_ 2589283914 NR_02_CAL_Text_Data_3 5000;
BA_REL_ "GenSigTimeoutTime" BU_SG_REL_ ZR_MIB_EINSTIEG_ab_Gen3 SG_ 2589283915 NR_03_CAL_Text_Request 5000;
BA_REL_ "GenSigTimeoutTime" BU_SG_REL_ ZR_MIB_EINSTIEG_ab_Gen3 SG_ 2589283915 NR_03_CAL_Text_Data_1 5000;
BA_REL_ "GenSigTimeoutTime" BU_SG_REL_ ZR_MIB_EINSTIEG_ab_Gen3 SG_ 2589283916 NR_03_CAL_Text_Data_2 5000;
BA_REL_ "GenSigTimeoutTime" BU_SG_REL_ ZR_MIB_EINSTIEG_ab_Gen3 SG_ 2589283917 NR_03_CAL_Text_Data_3 5000;
BA_REL_ "GenSigTimeoutTime" BU_SG_REL_ ZR_MIB_EINSTIEG_ab_Gen3 SG_ 2589283918 NR_04_CAL_Text_Request 5000;
BA_REL_ "GenSigTimeoutTime" BU_SG_REL_ ZR_MIB_EINSTIEG_ab_Gen3 SG_ 2589283918 NR_04_CAL_Text_Data_1 5000;
BA_REL_ "GenSigTimeoutTime" BU_SG_REL_ ZR_MIB_EINSTIEG_ab_Gen3 SG_ 2589283919 NR_04_CAL_Text_Data_2 5000;
BA_REL_ "GenSigTimeoutTime" BU_SG_REL_ ZR_MIB_EINSTIEG_ab_Gen3 SG_ 2589283920 NR_04_CAL_Text_Data_3 5000;
BA_REL_ "GenSigTimeoutTime" BU_SG_REL_ ZR_MIB_EINSTIEG_ab_Gen3 SG_ 2589284036 NR_05_CAL_Text_Request 5000;
BA_REL_ "GenSigTimeoutTime" BU_SG_REL_ ZR_MIB_EINSTIEG_ab_Gen3 SG_ 2589284036 NR_05_CAL_Text_Data_1 5000;
BA_REL_ "GenSigTimeoutTime" BU_SG_REL_ ZR_MIB_EINSTIEG_ab_Gen3 SG_ 2589284037 NR_05_CAL_Text_Data_2 5000;
BA_REL_ "GenSigTimeoutTime" BU_SG_REL_ ZR_MIB_EINSTIEG_ab_Gen3 SG_ 2589284038 NR_05_CAL_Text_Data_3 5000;
BA_REL_ "GenSigTimeoutTime" BU_SG_REL_ ZR_MIB_EINSTIEG_ab_Gen3 SG_ 2589284039 NR_06_CAL_Text_Request 5000;
BA_REL_ "GenSigTimeoutTime" BU_SG_REL_ ZR_MIB_EINSTIEG_ab_Gen3 SG_ 2589284039 NR_06_CAL_Text_Data_1 5000;
BA_REL_ "GenSigTimeoutTime" BU_SG_REL_ ZR_MIB_EINSTIEG_ab_Gen3 SG_ 2589284040 NR_06_CAL_Text_Data_2 5000;
BA_REL_ "GenSigTimeoutTime" BU_SG_REL_ ZR_MIB_EINSTIEG_ab_Gen3 SG_ 2589284041 NR_06_CAL_Text_Data_3 5000;
BA_REL_ "GenSigTimeoutTime" BU_SG_REL_ ZR_MIB_EINSTIEG_ab_Gen3 SG_ 913 OBD_Driving_Cycle 1000;
BA_REL_ "GenSigTimeoutTime" BU_SG_REL_ ZR_MIB_EINSTIEG_ab_Gen3 SG_ 1175 PH_Anf_Audioabsenkung 1000;
BA_REL_ "GenSigTimeoutTime" BU_SG_REL_ ZR_MIB_EINSTIEG_ab_Gen3 SG_ 1355 PH_Ton_Ausgabe 5000;
BA_REL_ "GenSigTimeoutTime" BU_SG_REL_ ZR_MIB_EINSTIEG_ab_Gen3 SG_ 1355 PH_Ton_Pausenlaenge 5000;
BA_REL_ "GenSigTimeoutTime" BU_SG_REL_ ZR_MIB_EINSTIEG_ab_Gen3 SG_ 1355 PH_Ton_Richtung 5000;
BA_REL_ "GenSigTimeoutTime" BU_SG_REL_ ZR_MIB_EINSTIEG_ab_Gen3 SG_ 1355 PH_Ton_Lautstaerke 5000;
BA_REL_ "GenSigTimeoutTime" BU_SG_REL_ ZR_MIB_EINSTIEG_ab_Gen3 SG_ 2527679498 Perso_Kontonummer 5000;
BA_REL_ "GenSigTimeoutTime" BU_SG_REL_ ZR_MIB_EINSTIEG_ab_Gen3 SG_ 2527679498 Perso_Steuerung 5000;
BA_REL_ "GenSigTimeoutTime" BU_SG_REL_ ZR_MIB_EINSTIEG_ab_Gen3 SG_ 2527679498 Perso_Steuerungsparameter 5000;
BA_REL_ "GenSigTimeoutTime" BU_SG_REL_ ZR_MIB_EINSTIEG_ab_Gen3 SG_ 2527679498 Perso_Status 5000;
BA_REL_ "GenSigTimeoutTime" BU_SG_REL_ ZR_MIB_EINSTIEG_ab_Gen3 SG_ 2527679498 IAA_PSO_wake_up 5000;
BA_REL_ "GenSigTimeoutTime" BU_SG_REL_ ZR_MIB_EINSTIEG_ab_Gen3 SG_ 2527679498 IAA_Active_User_ID 5000;
BA_REL_ "GenSigTimeoutTime" BU_SG_REL_ ZR_MIB_EINSTIEG_ab_Gen3 SG_ 2527679498 IAA_Identified_User_ID 5000;
BA_REL_ "GenSigTimeoutTime" BU_SG_REL_ ZR_MIB_EINSTIEG_ab_Gen3 SG_ 2463978629 Perso_Kontonummer_02 5000;
BA_REL_ "GenSigTimeoutTime" BU_SG_REL_ ZR_MIB_EINSTIEG_ab_Gen3 SG_ 2463978629 Perso_Steuerung_02 5000;
BA_REL_ "GenSigTimeoutTime" BU_SG_REL_ ZR_MIB_EINSTIEG_ab_Gen3 SG_ 2463978629 Perso_Steuerungsparameter_02 5000;
BA_REL_ "GenSigTimeoutTime" BU_SG_REL_ ZR_MIB_EINSTIEG_ab_Gen3 SG_ 2463978629 Perso_Status_02 5000;
BA_REL_ "GenSigTimeoutTime" BU_SG_REL_ ZR_MIB_EINSTIEG_ab_Gen3 SG_ 2463978629 IAA_Active_User_ID_02 5000;
BA_REL_ "GenSigTimeoutTime" BU_SG_REL_ ZR_MIB_EINSTIEG_ab_Gen3 SG_ 2463978629 IAA_Identified_User_ID_02 5000;
BA_REL_ "GenSigTimeoutTime" BU_SG_REL_ ZR_MIB_OPTION_ab_Gen3 SG_ 2600468496 NM_Gateway_NM_State 2000;
BA_REL_ "GenSigTimeoutTime" BU_SG_REL_ ZR_MIB_OPTION_ab_Gen3 SG_ 2600468496 NM_Gateway_Car_Wakeup 2000;
BA_REL_ "GenSigTimeoutTime" BU_SG_REL_ ZR_MIB_OPTION_ab_Gen3 SG_ 2600468644 NM_LSH_NM_State 2000;
BA_REL_ "GenSigTimeoutTime" BU_SG_REL_ ZR_MIB_OPTION_ab_Gen3 SG_ 2600468491 NM_RDK_NM_State 2000;
BA_REL_ "GenSigTimeoutTime" BU_SG_REL_ ZR_MIB_OPTION_ab_Gen3 SG_ 2600468586 NM_STH_NM_State 2000;
BA_REL_ "GenSigTimeoutTime" BU_SG_REL_ ZR_MIB_OPTION_ab_Gen3 SG_ 2589283909 NR_01_CAL_Text_Request 5000;
BA_REL_ "GenSigTimeoutTime" BU_SG_REL_ ZR_MIB_OPTION_ab_Gen3 SG_ 2589283909 NR_01_CAL_Text_Data_1 5000;
BA_REL_ "GenSigTimeoutTime" BU_SG_REL_ ZR_MIB_OPTION_ab_Gen3 SG_ 2589283910 NR_01_CAL_Text_Data_2 5000;
BA_REL_ "GenSigTimeoutTime" BU_SG_REL_ ZR_MIB_OPTION_ab_Gen3 SG_ 2589283911 NR_01_CAL_Text_Data_3 5000;
BA_REL_ "GenSigTimeoutTime" BU_SG_REL_ ZR_MIB_OPTION_ab_Gen3 SG_ 2589283912 NR_02_CAL_Text_Request 5000;
BA_REL_ "GenSigTimeoutTime" BU_SG_REL_ ZR_MIB_OPTION_ab_Gen3 SG_ 2589283912 NR_02_CAL_Text_Data_1 5000;
BA_REL_ "GenSigTimeoutTime" BU_SG_REL_ ZR_MIB_OPTION_ab_Gen3 SG_ 2589283913 NR_02_CAL_Text_Data_2 5000;
BA_REL_ "GenSigTimeoutTime" BU_SG_REL_ ZR_MIB_OPTION_ab_Gen3 SG_ 2589283914 NR_02_CAL_Text_Data_3 5000;
BA_REL_ "GenSigTimeoutTime" BU_SG_REL_ ZR_MIB_OPTION_ab_Gen3 SG_ 2589283915 NR_03_CAL_Text_Request 5000;
BA_REL_ "GenSigTimeoutTime" BU_SG_REL_ ZR_MIB_OPTION_ab_Gen3 SG_ 2589283915 NR_03_CAL_Text_Data_1 5000;
BA_REL_ "GenSigTimeoutTime" BU_SG_REL_ ZR_MIB_OPTION_ab_Gen3 SG_ 2589283916 NR_03_CAL_Text_Data_2 5000;
BA_REL_ "GenSigTimeoutTime" BU_SG_REL_ ZR_MIB_OPTION_ab_Gen3 SG_ 2589283917 NR_03_CAL_Text_Data_3 5000;
BA_REL_ "GenSigTimeoutTime" BU_SG_REL_ ZR_MIB_OPTION_ab_Gen3 SG_ 2589283918 NR_04_CAL_Text_Request 5000;
BA_REL_ "GenSigTimeoutTime" BU_SG_REL_ ZR_MIB_OPTION_ab_Gen3 SG_ 2589283918 NR_04_CAL_Text_Data_1 5000;
BA_REL_ "GenSigTimeoutTime" BU_SG_REL_ ZR_MIB_OPTION_ab_Gen3 SG_ 2589283919 NR_04_CAL_Text_Data_2 5000;
BA_REL_ "GenSigTimeoutTime" BU_SG_REL_ ZR_MIB_OPTION_ab_Gen3 SG_ 2589283920 NR_04_CAL_Text_Data_3 5000;
BA_REL_ "GenSigTimeoutTime" BU_SG_REL_ ZR_MIB_OPTION_ab_Gen3 SG_ 2589284036 NR_05_CAL_Text_Request 5000;
BA_REL_ "GenSigTimeoutTime" BU_SG_REL_ ZR_MIB_OPTION_ab_Gen3 SG_ 2589284036 NR_05_CAL_Text_Data_1 5000;
BA_REL_ "GenSigTimeoutTime" BU_SG_REL_ ZR_MIB_OPTION_ab_Gen3 SG_ 2589284037 NR_05_CAL_Text_Data_2 5000;
BA_REL_ "GenSigTimeoutTime" BU_SG_REL_ ZR_MIB_OPTION_ab_Gen3 SG_ 2589284038 NR_05_CAL_Text_Data_3 5000;
BA_REL_ "GenSigTimeoutTime" BU_SG_REL_ ZR_MIB_OPTION_ab_Gen3 SG_ 2589284039 NR_06_CAL_Text_Request 5000;
BA_REL_ "GenSigTimeoutTime" BU_SG_REL_ ZR_MIB_OPTION_ab_Gen3 SG_ 2589284039 NR_06_CAL_Text_Data_1 5000;
BA_REL_ "GenSigTimeoutTime" BU_SG_REL_ ZR_MIB_OPTION_ab_Gen3 SG_ 2589284040 NR_06_CAL_Text_Data_2 5000;
BA_REL_ "GenSigTimeoutTime" BU_SG_REL_ ZR_MIB_OPTION_ab_Gen3 SG_ 2589284041 NR_06_CAL_Text_Data_3 5000;
BA_REL_ "GenSigTimeoutTime" BU_SG_REL_ ZR_MIB_OPTION_ab_Gen3 SG_ 913 OBD_Driving_Cycle 1000;
BA_REL_ "GenSigTimeoutTime" BU_SG_REL_ ZR_MIB_OPTION_ab_Gen3 SG_ 2589283656 ORU_Status 5000;
BA_REL_ "GenSigTimeoutTime" BU_SG_REL_ ZR_MIB_OPTION_ab_Gen3 SG_ 1175 PH_Anf_Audioabsenkung 1000;
BA_REL_ "GenSigTimeoutTime" BU_SG_REL_ ZR_MIB_OPTION_ab_Gen3 SG_ 1355 PH_Ton_Ausgabe 5000;
BA_REL_ "GenSigTimeoutTime" BU_SG_REL_ ZR_MIB_OPTION_ab_Gen3 SG_ 1355 PH_Ton_Pausenlaenge 5000;
BA_REL_ "GenSigTimeoutTime" BU_SG_REL_ ZR_MIB_OPTION_ab_Gen3 SG_ 1355 PH_Ton_Richtung 5000;
BA_REL_ "GenSigTimeoutTime" BU_SG_REL_ ZR_MIB_OPTION_ab_Gen3 SG_ 1355 PH_Ton_Lautstaerke 5000;
BA_REL_ "GenSigTimeoutTime" BU_SG_REL_ ZR_MIB_OPTION_ab_Gen3 SG_ 2527679498 Perso_Kontonummer 5000;
BA_REL_ "GenSigTimeoutTime" BU_SG_REL_ ZR_MIB_OPTION_ab_Gen3 SG_ 2527679498 Perso_Steuerung 5000;
BA_REL_ "GenSigTimeoutTime" BU_SG_REL_ ZR_MIB_OPTION_ab_Gen3 SG_ 2527679498 Perso_Steuerungsparameter 5000;
BA_REL_ "GenSigTimeoutTime" BU_SG_REL_ ZR_MIB_OPTION_ab_Gen3 SG_ 2527679498 Perso_Status 5000;
BA_REL_ "GenSigTimeoutTime" BU_SG_REL_ ZR_MIB_OPTION_ab_Gen3 SG_ 2527679498 IAA_PSO_wake_up 5000;
BA_REL_ "GenSigTimeoutTime" BU_SG_REL_ ZR_MIB_OPTION_ab_Gen3 SG_ 2527679498 IAA_Active_User_ID 5000;
BA_REL_ "GenSigTimeoutTime" BU_SG_REL_ ZR_MIB_OPTION_ab_Gen3 SG_ 2527679498 IAA_Identified_User_ID 5000;
BA_REL_ "GenSigTimeoutTime" BU_SG_REL_ ZR_MIB_OPTION_ab_Gen3 SG_ 2463978629 IAA_Active_User_ID_02 5000;
BA_REL_ "GenSigTimeoutTime" BU_SG_REL_ ZR_MIB_OPTION_ab_Gen3 SG_ 2463978629 IAA_Identified_User_ID_02 5000;
BA_REL_ "GenSigTimeoutTime" BU_SG_REL_ ZR_MIB_TOP_ab_Gen3 SG_ 2600468496 NM_Gateway_NM_State 2000;
BA_REL_ "GenSigTimeoutTime" BU_SG_REL_ ZR_MIB_TOP_ab_Gen3 SG_ 2600468496 NM_Gateway_Car_Wakeup 2000;
BA_REL_ "GenSigTimeoutTime" BU_SG_REL_ ZR_MIB_TOP_ab_Gen3 SG_ 2600468644 NM_LSH_NM_State 2000;
BA_REL_ "GenSigTimeoutTime" BU_SG_REL_ ZR_MIB_TOP_ab_Gen3 SG_ 2600468491 NM_RDK_NM_State 2000;
BA_REL_ "GenSigTimeoutTime" BU_SG_REL_ ZR_MIB_TOP_ab_Gen3 SG_ 2600468586 NM_STH_NM_State 2000;
BA_REL_ "GenSigTimeoutTime" BU_SG_REL_ ZR_MIB_TOP_ab_Gen3 SG_ 2589283909 NR_01_CAL_Text_Request 5000;
BA_REL_ "GenSigTimeoutTime" BU_SG_REL_ ZR_MIB_TOP_ab_Gen3 SG_ 2589283909 NR_01_CAL_Text_Data_1 5000;
BA_REL_ "GenSigTimeoutTime" BU_SG_REL_ ZR_MIB_TOP_ab_Gen3 SG_ 2589283910 NR_01_CAL_Text_Data_2 5000;
BA_REL_ "GenSigTimeoutTime" BU_SG_REL_ ZR_MIB_TOP_ab_Gen3 SG_ 2589283911 NR_01_CAL_Text_Data_3 5000;
BA_REL_ "GenSigTimeoutTime" BU_SG_REL_ ZR_MIB_TOP_ab_Gen3 SG_ 2589283912 NR_02_CAL_Text_Request 5000;
BA_REL_ "GenSigTimeoutTime" BU_SG_REL_ ZR_MIB_TOP_ab_Gen3 SG_ 2589283912 NR_02_CAL_Text_Data_1 5000;
BA_REL_ "GenSigTimeoutTime" BU_SG_REL_ ZR_MIB_TOP_ab_Gen3 SG_ 2589283913 NR_02_CAL_Text_Data_2 5000;
BA_REL_ "GenSigTimeoutTime" BU_SG_REL_ ZR_MIB_TOP_ab_Gen3 SG_ 2589283914 NR_02_CAL_Text_Data_3 5000;
BA_REL_ "GenSigTimeoutTime" BU_SG_REL_ ZR_MIB_TOP_ab_Gen3 SG_ 2589283915 NR_03_CAL_Text_Request 5000;
BA_REL_ "GenSigTimeoutTime" BU_SG_REL_ ZR_MIB_TOP_ab_Gen3 SG_ 2589283915 NR_03_CAL_Text_Data_1 5000;
BA_REL_ "GenSigTimeoutTime" BU_SG_REL_ ZR_MIB_TOP_ab_Gen3 SG_ 2589283916 NR_03_CAL_Text_Data_2 5000;
BA_REL_ "GenSigTimeoutTime" BU_SG_REL_ ZR_MIB_TOP_ab_Gen3 SG_ 2589283917 NR_03_CAL_Text_Data_3 5000;
BA_REL_ "GenSigTimeoutTime" BU_SG_REL_ ZR_MIB_TOP_ab_Gen3 SG_ 2589283918 NR_04_CAL_Text_Request 5000;
BA_REL_ "GenSigTimeoutTime" BU_SG_REL_ ZR_MIB_TOP_ab_Gen3 SG_ 2589283918 NR_04_CAL_Text_Data_1 5000;
BA_REL_ "GenSigTimeoutTime" BU_SG_REL_ ZR_MIB_TOP_ab_Gen3 SG_ 2589283919 NR_04_CAL_Text_Data_2 5000;
BA_REL_ "GenSigTimeoutTime" BU_SG_REL_ ZR_MIB_TOP_ab_Gen3 SG_ 2589283920 NR_04_CAL_Text_Data_3 5000;
BA_REL_ "GenSigTimeoutTime" BU_SG_REL_ ZR_MIB_TOP_ab_Gen3 SG_ 2589284036 NR_05_CAL_Text_Request 5000;
BA_REL_ "GenSigTimeoutTime" BU_SG_REL_ ZR_MIB_TOP_ab_Gen3 SG_ 2589284036 NR_05_CAL_Text_Data_1 5000;
BA_REL_ "GenSigTimeoutTime" BU_SG_REL_ ZR_MIB_TOP_ab_Gen3 SG_ 2589284037 NR_05_CAL_Text_Data_2 5000;
BA_REL_ "GenSigTimeoutTime" BU_SG_REL_ ZR_MIB_TOP_ab_Gen3 SG_ 2589284038 NR_05_CAL_Text_Data_3 5000;
BA_REL_ "GenSigTimeoutTime" BU_SG_REL_ ZR_MIB_TOP_ab_Gen3 SG_ 2589284039 NR_06_CAL_Text_Request 5000;
BA_REL_ "GenSigTimeoutTime" BU_SG_REL_ ZR_MIB_TOP_ab_Gen3 SG_ 2589284039 NR_06_CAL_Text_Data_1 5000;
BA_REL_ "GenSigTimeoutTime" BU_SG_REL_ ZR_MIB_TOP_ab_Gen3 SG_ 2589284040 NR_06_CAL_Text_Data_2 5000;
BA_REL_ "GenSigTimeoutTime" BU_SG_REL_ ZR_MIB_TOP_ab_Gen3 SG_ 2589284041 NR_06_CAL_Text_Data_3 5000;
BA_REL_ "GenSigTimeoutTime" BU_SG_REL_ ZR_MIB_TOP_ab_Gen3 SG_ 913 OBD_Driving_Cycle 1000;
BA_REL_ "GenSigTimeoutTime" BU_SG_REL_ ZR_MIB_TOP_ab_Gen3 SG_ 2589283656 ORU_Status 5000;
BA_REL_ "GenSigTimeoutTime" BU_SG_REL_ ZR_MIB_TOP_ab_Gen3 SG_ 1175 PH_Anf_Audioabsenkung 1000;
BA_REL_ "GenSigTimeoutTime" BU_SG_REL_ ZR_MIB_TOP_ab_Gen3 SG_ 1355 PH_Ton_Ausgabe 5000;
BA_REL_ "GenSigTimeoutTime" BU_SG_REL_ ZR_MIB_TOP_ab_Gen3 SG_ 1355 PH_Ton_Pausenlaenge 5000;
BA_REL_ "GenSigTimeoutTime" BU_SG_REL_ ZR_MIB_TOP_ab_Gen3 SG_ 1355 PH_Ton_Richtung 5000;
BA_REL_ "GenSigTimeoutTime" BU_SG_REL_ ZR_MIB_TOP_ab_Gen3 SG_ 1355 PH_Ton_Lautstaerke 5000;
BA_REL_ "GenSigTimeoutTime" BU_SG_REL_ ZR_MIB_TOP_ab_Gen3 SG_ 2527679498 Perso_Kontonummer 5000;
BA_REL_ "GenSigTimeoutTime" BU_SG_REL_ ZR_MIB_TOP_ab_Gen3 SG_ 2527679498 Perso_Steuerung 5000;
BA_REL_ "GenSigTimeoutTime" BU_SG_REL_ ZR_MIB_TOP_ab_Gen3 SG_ 2527679498 Perso_Steuerungsparameter 5000;
BA_REL_ "GenSigTimeoutTime" BU_SG_REL_ ZR_MIB_TOP_ab_Gen3 SG_ 2527679498 Perso_Status 5000;
BA_REL_ "GenSigTimeoutTime" BU_SG_REL_ ZR_MIB_TOP_ab_Gen3 SG_ 2527679498 IAA_PSO_wake_up 5000;
BA_REL_ "GenSigTimeoutTime" BU_SG_REL_ ZR_MIB_TOP_ab_Gen3 SG_ 2527679498 Perso_Fahrernummer 5000;
BA_REL_ "GenSigTimeoutTime" BU_SG_REL_ ZR_MIB_TOP_ab_Gen3 SG_ 2527679498 IAA_Active_User_ID 5000;
BA_REL_ "GenSigTimeoutTime" BU_SG_REL_ ZR_MIB_TOP_ab_Gen3 SG_ 2527679498 IAA_Identified_User_ID 5000;
BA_REL_ "GenSigTimeoutTime" BU_SG_REL_ ZR_MIB_TOP_ab_Gen3 SG_ 2463978629 Perso_Kontonummer_02 5000;
BA_REL_ "GenSigTimeoutTime" BU_SG_REL_ ZR_MIB_TOP_ab_Gen3 SG_ 2463978629 Perso_Steuerung_02 5000;
BA_REL_ "GenSigTimeoutTime" BU_SG_REL_ ZR_MIB_TOP_ab_Gen3 SG_ 2463978629 Perso_Steuerungsparameter_02 5000;
BA_REL_ "GenSigTimeoutTime" BU_SG_REL_ ZR_MIB_TOP_ab_Gen3 SG_ 2463978629 Perso_Status_02 5000;
BA_REL_ "GenSigTimeoutTime" BU_SG_REL_ ZR_MIB_TOP_ab_Gen3 SG_ 2463978629 IAA_Active_User_ID_02 5000;
BA_REL_ "GenSigTimeoutTime" BU_SG_REL_ ZR_MIB_TOP_ab_Gen3 SG_ 2463978629 IAA_Identified_User_ID_02 5000;
VAL_ 2600468496 NM_Gateway_CBV_AWB 0 "Passiver_WakeUp" 1 "Aktiver_WakeUp" ;
VAL_ 2600468496 NM_Gateway_CBV_CRI 0 "NM_ohne_Clusteranforderungen" 1 "NM_mit_Clusteranforderungen" ;
VAL_ 2600468496 NM_Gateway_NM_State 0 "Init" 1 "NM_RM_aus_BSM" 2 "NM_RM_aus_PBSM" 4 "NM_NO_aus_RM" 8 "NM_NO_aus_RS" 16 "reserved" 32 "reserved" ;
VAL_ 2600468496 NM_Gateway_Car_Wakeup 0 "Inaktiv" 1 "Car_Wakeup" ;
VAL_ 2600468496 NM_Gateway_UDS_CC 0 "Inaktiv" 1 "CC_aktiv" ;
VAL_ 2600468496 NM_Gateway_NM_aktiv_KL15 0 "Inaktiv" 1 "KL15_EIN" ;
VAL_ 2600468496 NM_Gateway_NM_aktiv_Diagnose 0 "Init" 1 "Diagnose_aktiv" ;
VAL_ 2600468496 NM_Gateway_NM_aktiv_Tmin 0 "Inaktiv" 1 "Mindestaktivzeit" ;
VAL_ 2600468496 NM_Gateway_NM_aktiv_CWU 0 "kein_CWU_gesetzt" 1 "CWU_gesetzt" ;
VAL_ 2600468496 NM_Gateway_NM_aktiv_FC 0 "kein_FC_gesetzt" 1 "FC_gesetzt" ;
VAL_ 2600468496 NM_Gateway_NM_aktiv_EM 0 "inaktiv" 1 "Nachlauf_aufgrund_Energiemanagement" ;
VAL_ 2600468496 NM_Gateway_NM_aktiv_Buskopplung 0 "inaktiv" 1 "Nachlauf_aufgrund_Buskopplung" ;
VAL_ 2600468496 NM_Gateway_CAB_V14 0 "Init" 1 "CAB_01_Antrieb" 2 "CAB_02_Hybrid_Laden" 4 "CAB_03_Fahrwerk" 8 "CAB_04_Fahrerassistenz" 16 "CAB_05_Komfort" 32 "CAB_06_Anzeige" 64 "CAB_07_Connect" 128 "CAB_08_MIB" 256 "CAB_09_Standheizung" 1024 "CAB_11_VLAN_Fahrerassistenz" 2048 "CAB_12_VLAN_Komfort" 4096 "CAB_13_VLAN_Connect" 8192 "CAB_14_VLAN_Infotainment" 16384 "CAB_15_Laden" 32768 "CAB_16_Licht" ;
VAL_ 2600468595 NM_Info_El_CBV_AWB 0 "Passiver_WakeUp" 1 "Aktiver_WakeUp" ;
VAL_ 2600468595 NM_Info_El_CBV_CRI 0 "NM_ohne_Clusteranforderungen" 1 "NM_mit_Clusteranforderungen" ;
VAL_ 2600468595 NM_Info_El_NM_State 0 "Init" 1 "NM_RM_aus_BSM" 2 "NM_RM_aus_PBSM" 4 "NM_NO_aus_RM" 8 "NM_NO_aus_RS" 16 "reserved" 32 "reserved" ;
VAL_ 2600468595 NM_Info_El_Car_Wakeup 0 "Inaktiv" 1 "Car_Wakeup" ;
VAL_ 2600468595 NM_Info_El_UDS_CC 0 "Inaktiv" 1 "CC_aktiv" ;
VAL_ 2600468595 NM_Info_El_NM_aktiv_KL15 0 "Inaktiv" 1 "KL15_EIN" ;
VAL_ 2600468595 NM_Info_El_NM_aktiv_Diagnose 0 "Init" 1 "Diagnose_aktiv" ;
VAL_ 2600468595 NM_Info_El_NM_aktiv_Tmin 0 "Inaktiv" 1 "Mindestaktivzeit" ;
VAL_ 2600468595 NM_Info_El_NM_aktiv_MIBCAN 0 "Init" 1 "MIB_CAN_aktiv" ;
VAL_ 2600468595 NM_Info_El_NM_aktiv_BAP_Comm 0 "Init" 1 "BAP_Sound_aktiv" ;
VAL_ 2600468595 NM_Info_El_NM_aktiv_IAA 0 "Init" 1 "IAA_aktiv" ;
VAL_ 2600468595 NM_Info_El_NM_aktiv_SmartLight 0 "Init" 1 "SmartLight_aktiv" ;
VAL_ 2600468595 NM_Info_El_NM_aktiv_Applikation 0 "nicht_aktiv" 1 "Applikationsanforderung_aktiv" ;
VAL_ 2600468595 NM_Info_El_NM_aktiv_Powerstate 0 "nicht_aktiv" 1 "Powerstate_aktiv" ;
VAL_ 2600468595 NM_Info_El_CAB_V14 0 "Init" 1 "CAB_01_Antrieb" 2 "CAB_02_Hybrid_Laden" 4 "CAB_03_Fahrwerk" 8 "CAB_04_Fahrerassistenz" 16 "CAB_05_Komfort" 32 "CAB_06_Anzeige" 64 "CAB_07_Connect" 128 "CAB_08_MIB" 256 "CAB_09_Standheizung" 1024 "CAB_11_VLAN_Fahrerassistenz" 2048 "CAB_12_VLAN_Komfort" 4096 "CAB_13_VLAN_Connect" 8192 "CAB_14_VLAN_Infotainment" 16384 "CAB_15_Laden" 32768 "CAB_16_Licht" ;
VAL_ 2600468644 NM_LSH_CBV_AWB 0 "Passiver_WakeUp" 1 "Aktiver_WakeUp" ;
VAL_ 2600468644 NM_LSH_CBV_CRI 0 "Standard_Layout" 1 "TNB_Layout" ;
VAL_ 2600468644 NM_LSH_NM_State 0 "Inaktiv" 1 "NM_RM_aus_BSM" 2 "NM_RM_aus_PBSM" 4 "NM_NO_aus_RM" 8 "NM_NO_aus_RS" ;
VAL_ 2600468644 NM_LSH_Car_Wakeup 0 "Inaktiv" 1 "Car_Wakeup" ;
VAL_ 2600468644 NM_LSH_UDS_CC 0 "CC_inaktiv" 1 "CC_aktiv" ;
VAL_ 2600468644 NM_LSH_NM_aktiv_KL15 0 "Inaktiv" 1 "KL15_EIN" ;
VAL_ 2600468644 NM_LSH_NM_aktiv_Diagnose 0 "Inaktiv" 1 "Diagnose_aktiv" ;
VAL_ 2600468644 NM_LSH_NM_aktiv_Tmin 0 "Inaktiv" 1 "Mindestaktivzeit" ;
VAL_ 2600468644 NM_LSH_NM_aktiv_EIN_AUS_Funk 0 "init" 1 "EIN_AUS_Funk_aktiv" ;
VAL_ 2600468644 NM_LSH_NM_aktiv_Datentransf_Funk 0 "init" 1 "Datentransfer_Funk_aktiv" ;
VAL_ 2600468644 NM_LSH_CAB_V14 0 "Init" 1 "CAB_01_Antrieb" 2 "CAB_02_Hybrid_Laden" 4 "CAB_03_Fahrwerk" 8 "CAB_04_Fahrerassistenz" 16 "CAB_05_Komfort" 32 "CAB_06_Anzeige" 64 "CAB_07_Connect" 128 "CAB_08_MIB" 256 "CAB_09_Standheizung" 1024 "CAB_11_VLAN_Fahrerassistenz" 2048 "CAB_12_VLAN_Komfort" 4096 "CAB_13_VLAN_Connect" 8192 "CAB_14_VLAN_Infotainment" 16384 "CAB_15_Laden" 32768 "CAB_16_Licht" ;
VAL_ 2600468491 NM_RDK_CBV_AWB 0 "Passiver_WakeUp" 1 "Aktiver_WakeUp" ;
VAL_ 2600468491 NM_RDK_CBV_CRI 0 "NM_ohne_Clusteranforderungen" 1 "NM_mit_Clusteranforderungen" ;
VAL_ 2600468491 NM_RDK_NM_State 0 "Init" 1 "NM_RM_aus_BSM" 2 "NM_RM_aus_PBSM" 4 "NM_NO_aus_RM" 8 "NM_NO_aus_RS" 16 "reserved" 32 "reserved" ;
VAL_ 2600468491 NM_RDK_Car_Wakeup 0 "Inaktiv" 1 "Car_Wakeup" ;
VAL_ 2600468491 NM_RDK_UDS_CC 0 "Inaktiv" 1 "CC_aktiv" ;
VAL_ 2600468491 NM_RDK_NM_aktiv_KL15 0 "Inaktiv" 1 "KL15_EIN" ;
VAL_ 2600468491 NM_RDK_NM_aktiv_Diagnose 0 "Init" 1 "Diagnose_aktiv" ;
VAL_ 2600468491 NM_RDK_NM_aktiv_Tmin 0 "Inaktiv" 1 "Mindestaktivzeit" ;
VAL_ 2600468491 NM_RDK_CAB_V14 0 "Init" 1 "CAB_01_Antrieb" 2 "CAB_02_Hybrid_Laden" 4 "CAB_03_Fahrwerk" 8 "CAB_04_Fahrerassistenz" 16 "CAB_05_Komfort" 32 "CAB_06_Anzeige" 64 "CAB_07_Connect" 128 "CAB_08_MIB" 256 "CAB_09_Standheizung" 1024 "CAB_11_VLAN_Fahrerassistenz" 2048 "CAB_12_VLAN_Komfort" 4096 "CAB_13_VLAN_Connect" 8192 "CAB_14_VLAN_Infotainment" 16384 "CAB_15_Laden" 32768 "CAB_16_Licht" ;
VAL_ 2600468586 NM_STH_CBV_AWB 0 "Passiver_WakeUp" 1 "Aktiver_WakeUp" ;
VAL_ 2600468586 NM_STH_CBV_CRI 0 "NM_ohne_Clusteranforderungen" 1 "NM_mit_Clusteranforderungen" ;
VAL_ 2600468586 NM_STH_NM_State 0 "Init" 1 "NM_RM_aus_BSM" 2 "NM_RM_aus_PBSM" 4 "NM_NO_aus_RM" 8 "NM_NO_aus_RS" 16 "reserved" 32 "reserved" ;
VAL_ 2600468586 NM_STH_Car_Wakeup 0 "Inaktiv" 1 "Car_Wakeup" ;
VAL_ 2600468586 NM_STH_UDS_CC 0 "Inaktiv" 1 "CC_aktiv" ;
VAL_ 2600468586 NM_STH_NM_aktiv_KL15 0 "Inaktiv" 1 "KL15_EIN" ;
VAL_ 2600468586 NM_STH_NM_aktiv_Diagnose 0 "Init" 1 "Diagnose_aktiv" ;
VAL_ 2600468586 NM_STH_NM_aktiv_Tmin 0 "Inaktiv" 1 "Mindestaktivzeit" ;
VAL_ 2600468586 NM_STH_NM_aktiv_EKP_Anf 1 "EKP_Anf_aktiv" ;
VAL_ 2600468586 NM_STH_NM_aktiv_WaPu_Anf 1 "WaPu_Anf_aktiv" ;
VAL_ 2600468586 NM_STH_NM_aktiv_EIN_AUS_Funk 1 "EIN_AUS_Funk_aktiv" ;
VAL_ 2600468586 NM_STH_NM_aktiv_Datentransf_Funk 1 "Datentransfer_Funk_aktiv" ;
VAL_ 2600468586 NM_STH_NM_aktiv_Geblaese_Anf 1 "Geblaese_Anf_aktiv" ;
VAL_ 2600468586 NM_STH_CAB_V14 0 "Init" 1 "CAB_01_Antrieb" 2 "CAB_02_Hybrid_Laden" 4 "CAB_03_Fahrwerk" 8 "CAB_04_Fahrerassistenz" 16 "CAB_05_Komfort" 32 "CAB_06_Anzeige" 64 "CAB_07_Connect" 128 "CAB_08_MIB" 256 "CAB_09_Standheizung" 1024 "CAB_11_VLAN_Fahrerassistenz" 2048 "CAB_12_VLAN_Komfort" 4096 "CAB_13_VLAN_Connect" 8192 "CAB_14_VLAN_Infotainment" 16384 "CAB_15_Laden" 32768 "CAB_16_Licht" ;
VAL_ 2589283909 NR_01_CAL_Text_Request 0 "Cal_status_display_not_active" 1 "Cal_status_display_active" ;
VAL_ 2589283912 NR_02_CAL_Text_Request 0 "Cal_status_display_not_active" 1 "Cal_status_display_active" ;
VAL_ 2589283915 NR_03_CAL_Text_Request 0 "Cal_status_display_not_active" 1 "Cal_status_display_active" ;
VAL_ 2589283918 NR_04_CAL_Text_Request 0 "Cal_status_display_not_active" 1 "Cal_status_display_active" ;
VAL_ 2589284036 NR_05_CAL_Text_Request 0 "Cal_status_display_not_active" 1 "Cal_status_display_active" ;
VAL_ 2589284039 NR_06_CAL_Text_Request 0 "Cal_status_display_not_active" 1 "Cal_status_display_active" ;
VAL_ 913 MO_Servicemodus 0 "nicht_aktiv" 1 "Service_Mode_1" 2 "Service_Mode_2" 3 "Service_Mode_3" 4 "Service_Mode_4" 5 "Service_Mode_5" 6 "Service_Mode_6" 7 "Service_Mode_7" 8 "Service_Mode_8" 9 "Service_Mode_9" 10 "Service_Mode_10" 11 "Service_Mode_11" 12 "Service_Mode_12" 13 "Service_Mode_13" 14 "Service_Mode_14" 15 "Service_Mode_15" ;
VAL_ 913 OBD_ClearMem_Inhibit 0 "FSP_Loeschen_zulaessig" 1 "FSP_Loeschen_nicht_zulaessig" ;
VAL_ 913 OBD_Sperrung_Kaltstart_Denom 0 "EVAP_Berechnung_freigegeben" 1 "EVAP_Berechnung_gesperrt" ;
VAL_ 913 MO_QBit_Aussen_Temp 0 "gueltiger_Wert" 1 "Ersatz_Init_oder_Fehlerwert" ;
VAL_ 913 OBD_Sperrung_IUMPR 0 "IUMPR_Berechnung_freigegeben" 1 "IUMPR_Berechnung_gesperrt" ;
VAL_ 913 OBD_Kaltstart_Denominator 0 "Denominator_nicht_hochzaehlen" 1 "Bedingungen_zum_Inkr_des_Kaltstart_Denom_erf" ;
VAL_ 913 OBD_Minimum_Trip 0 "kein_Min_Normed_Trip" 1 "Min_Normed_Trip" ;
VAL_ 913 OBD_Driving_Cycle 0 "kein_Driving_Cycle_erkannt" 1 "Driving_Cycle_erkannt" ;
VAL_ 913 OBD_Warm_Up_Cycle 0 "kein_Warm_Up_Cycle_erkannt" 1 "Warm_Up_Cycle_erkannt" ;
VAL_ 913 OBD_Normed_Trip 0 "kein_Normed_Trip" 1 "Normed_Trip" ;
VAL_ 28 OCU_WFS_Anfrage_Typ 0 "Init" ;
VAL_ 28 OCU_WFS_Anfrage_CRC 0 "Init" ;
VAL_ 28 OCU_WFS_Anfrage_Status 0 "Init" ;
VAL_ 2589283656 ORU_Warnung 0 "keine_Anzeige" 1 "Update_unvollstaendig_Prio1" 2 "Update_fehlgeschlagen_Prio1" 3 "reserviert" ;
VAL_ 2589283656 ORU_Status 0 "IDLE" 1 "PENDING" 2 "PREPARATION" 3 "PREPARATION_HV" 4 "RUNNING" 5 "RUNNING_HV" 6 "PENDING_NOTREADY" 7 "FAILURE_POWERTRAIN_DISABLED" ;
VAL_ 1175 PH_Visualisierung 0 "Aus" 1 "Angefragt" 2 "InAnzeige" 3 "Abgefordert" 6 "Init" 7 "Fehler" ;
VAL_ 1175 PDC_Tonausgabe_Front 0 "kein_Ton" 1 "Intervallton_1" 2 "Intervallton_2" 3 "Intervallton_3" 4 "Intervallton_4" 5 "Intervallton_5" 6 "Dauerton" 7 "Fehlerton" 8 "RCTATon" ;
VAL_ 1175 PDC_Tonausgabe_Heck 0 "kein_Ton" 1 "Intervallton_1" 2 "Intervallton_2" 3 "Intervallton_3" 4 "Intervallton_4" 5 "Intervallton_5" 6 "Dauerton" 7 "Fehlerton" 8 "Erstwarnton_hinten" 9 "RCTATon" ;
VAL_ 1175 PH_nachtr_Stopp_Anf 0 "nicht_angefordert" 1 "angefordert" ;
VAL_ 1175 PH_Abschaltursache 0 "keine, bzw. System aktiv" 1 "Abschaltung durch Herausnahme R-Gang" 2 "Abschaltung ueber Geschwindigkeit" 3 "Abschaltung ueber PDC-Taster" 4 "Abschaltung wegen PLA" 5 "Abschaltung durch KL 15 Bit = 0" 6 "tbd." 7 "Fehler-/gestört Zustand, System noch aktiv" ;
VAL_ 1175 PH_Opt_Anzeige_V_ein 0 "optische Anzeige vorne nicht aktiv" 1 "optische Anzeige vorne aktiviert" ;
VAL_ 1175 PH_Opt_Anzeige_H_ein 0 "Optische Anzeige aus" 1 "optische Anzeige hinten aktiviert" ;
VAL_ 1175 PH_Opt_Anz_V_Hindernis 0 "optische Anzeige vorne meldet kein Hindernis" 1 "optische Anzeige vorne meldet Hindernis im Warnbereich" ;
VAL_ 1175 PH_Opt_Anz_H_Hindernis 0 "optische Anzeige hinten meldet kein Hindernis" 1 "optische Anzeige hinten meldet Hindernis im Warnbereich" ;
VAL_ 1175 PH_Tongeber_V_aktiv 0 "Tongeber vorne nicht aktiv" 1 "Tongeber vorne  aktiv" ;
VAL_ 1175 PH_Tongeber_H_aktiv 0 "Tongeber hinten nicht aktiv" 1 "Tongeber hinten aktiv" ;
VAL_ 1175 PH_Tongeber_mute 0 "Tongeber nicht stummgeschaltet" 1 "Tongeber stummgeschaltet" ;
VAL_ 1175 PH_Anf_Audioabsenkung 0 "Keine_Audioabsenkung" 1 "Anforderung_Audioabsenkung" ;
VAL_ 1175 PH_Tongeber_H_verfuegbar 0 "nicht verfügbar" 1 "verfügbar" ;
VAL_ 1175 PLA_Anf_Aufschaltung_RVC 0 "Keine_RVC_Aufschalteanf" 1 "RVC_Aufschalteanforderung" ;
VAL_ 1175 PH_Taster 0 "Taster_nicht_gedrueckt" 1 "Taster_gedrueckt" 2 "reserviert" 3 "Fehler" ;
VAL_ 1175 PH_Anf_Verdeck 0 "Verdeckbetrieb_freigegeben" 1 "Verdeckbetrieb_sperren" 2 "reserviert" 3 "reserviert" ;
VAL_ 1175 PH_StartStopp_Info 0 "Motorlauf_nicht_notwendig_(Stoppfreigabe)" 1 "Motoranlauf_nicht_zwingend_notwendig_(Stoppverbot,keine_Startanforderung)" 2 "Motoranlauf_zwingend_notwendig_(Startanforderung)" 3 "Systemfehler" ;
VAL_ 1175 PH_Stoermeldung 0 "keine_Anzeige_kein_Gong" 1 "Textmeldung_PDC_hinten_gestoert_mit_Gong" 2 "Textmeldung_PDC_hinten_gestoert_ohne_Gong" 3 "Textmeldung_PDC_vorn_gestoert_mit_Gong" 4 "Textmeldung_PDC_vorn_gestoert_ohne_Gong" 5 "Textmeldung_PDC_gestoert_mit_Gong" 6 "Textmeldung_PDC_gestoert_ohne_Gong" 7 "Textmeldung_PDC_seitlich_gestoert_mit_Gong" 8 "Textmeldung_PDC_seitlich_gestoert_ohne_Gong" ;
VAL_ 1175 PH_defekt 0 "PH aktiv" 1 "PH wurde aufgrund eines Defektes deaktiviert" ;
VAL_ 1175 PH_gestoert 0 "PH aktiv" 1 "PH wurde auf Grund einer Stoerung tempraer deaktiviert" ;
VAL_ 1175 PH_Systemzustand 0 "Anlage aus" 1 "Anlage durch einlegen R-Gang aktiviert" 2 "Anlage manuell durch Taster aktiviert" 3 "Anlage automatisch aktiviert" 4 "Anlage durch ARA aktiviert" 6 "Init - Initialisierungsphase nach Kl. 15 ein / Reset" 7 "Fehler-/gestört Zustand, System noch aktiv" ;
VAL_ 1175 PH_Display_Kundenwunsch 0 "Anzeige aus" 1 "Grafik" 2 "Rear View" 3 "automatisch" ;
VAL_ 1355 RBFMA_PaCo_BrakeIntervention 0 "Inactive" 1 "Active_Rear" 2 "Active_Front" 3 "Active_Left" 4 "Active_Right" ;
VAL_ 1355 RBFMA_PaCo_MainState 0 "Init" 1 "InOperation_NoError" 2 "Eingeschraenkt" 7 "Fehler" ;
VAL_ 1355 RAB_PaCo_FunctionState 0 "nicht_verfuegbar" 1 "im_Hintergrund" 2 "in_Anzeige" 3 "in_Aktivierung" 4 "in_Regelung" ;
VAL_ 1355 RBF_Anf_Meldungen 0 "Init" 1 "RBF_eingeschraenkt_Sensorsicht" 2 "RBF_eingeschraenkt_Reinigung" 3 "RBF_nicht_verfuegbar" 4 "RBF_Notbremsung" 5 "RBF_zurzeit_eingeschraenkt" 6 "RBF_eingeschraenkt_reinigen" ;
VAL_ 1355 PH_Verschmutzungsmeldung 0 "keine_Anzeige_kein_Gong" 1 "Textmeldung_PDC_hinten_verschmutzt_mit_Gong" 2 "Textmeldung_PDC_hinten_verschmutzt_ohne_Gong" 3 "Textmeldung_PDC_vorn_verschmutzt_mit_Gong" 4 "Textmeldung_PDC_vorn_verschmutzt_ohne_Gong" 5 "Textmeldung_PDC_verschmutzt_mit_Gong" 6 "Textmeldung_PDC_verschmutzt_ohne_Gong" 7 "Textmeldung_PDC_seitlich_verschmutzt_mit_Gong" 8 "Textmeldung_PDC_seitlich_verschmutzt_ohne_Gong" ;
VAL_ 1355 PH_Aufschaltursache 0 "Anlage aus" 1 "Anlage durch einlegen R-Gang aktiviert" 2 "Anlage manuell durch Taster aktiviert" 3 "Anlage automatisch aktiviert" 4 "Anlage durch ARA aktiviert" 5 "Rueckwaertsrollen" 6 "Anlage_durch_PLA_aktiviert" 7 "Anlage_durch_IPA_aktiviert" 8 "Anlage_durch_FA_aktiviert" 9 "Anlage_durch_RBF_oder_MA_aktiviert" 10 "Anlage_durch_Smartphone_aktiviert" 11 "Anlage_durch_Jokertaste_aktiviert" 12 "Anlage_durch_Favoritentasten_aktiviert" 13 "Anlage_durch_SideViewTaster_aktiviert" 14 "Anlage_durch_RCTA_aktiviert" 15 "Anlage_durch_KAS_aktiviert" 16 "Anlage_durch_AWC_aktiviert" 30 "Init_Initialisierungsphase_nach_Kl_15_ein_oder_Reset" 31 "Fehler_gestoerter_Zustand_System_noch_aktiv" ;
VAL_ 1355 PH_Ton_Ausgabe 0 "Init" 1 "Intervallton_vorne" 2 "Intervallton_hinten" 3 "Dauerton_vorne" 4 "Dauerton_hinten" 5 "Quittierungston" 6 "Reserviert" 7 "Fehler" ;
VAL_ 1355 PH_Ton_Pausenlaenge 0 "Init" 1 "Pause_5ms" 2 "Pause_10ms" 3 "Pause_15ms" 100 "Pause_500ms" 101 "Reserviert" 126 "Reserviert" 127 "Fehler" ;
VAL_ 1355 APSOPS_PaCo_ObstacleDetectRear 0 "None" 1 "LongDistance_OutsideDriveTube" 2 "LongDistance_InsideDriveTube" 3 "ShortDistance_OutsideDriveTube" 4 "ShortDistance_InsideDriveTube" ;
VAL_ 1355 APSOPS_PaCo_ObstacleDetectFront 0 "None" 1 "LongDistance_OutsideDriveTube" 2 "LongDistance_InsideDriveTube" 3 "ShortDistance_OutsideDriveTube" 4 "ShortDistance_InsideDriveTube" ;
VAL_ 1355 APSOPS_PaCo_Button 0 "Init_or_not_equipped" 1 "Button_not_pressed" 2 "Button_pressed_debounced" 3 "Error" ;
VAL_ 1355 APSOPS_PaCo_MainState 0 "Init" 1 "InOperation_NoError" 7 "Fehler" ;
VAL_ 1355 APSOPS_PaCo_FunctionState 0 "No_Error" 1 "Sensor_Defect" 2 "Sensor_Contaminated" ;
VAL_ 1355 APSOPS_PaCo_ApproachingRear 0 "No_Obstacle_Approaching" 1 "Obstacle_Approaching" ;
VAL_ 1355 APSOPS_PaCo_ApproachingFront 0 "No_Obstacle_Approaching" 1 "Obstacle_Approaching" ;
VAL_ 1355 APS_PaCo_WarningTones 0 "Not_Possible" 1 "Possible" ;
VAL_ 1355 PH_Ton_Richtung 0 "vorne" 1 "vorne_rechts" 2 "rechts" 3 "rechts_hinten" 4 "hinten" 5 "hinten_links" 6 "links" 7 "vorne_links" ;
VAL_ 1355 PH_Ton_Lautstaerke 0 "Minimallautstaerke" 1 "Lautstaerke_1" 2 "Lautstaerke_2" 3 "Lautstaerke_3" 4 "Lautstaerke_4" 5 "Lautstaerke_5" 6 "Lautstaerke_6" 7 "Maximallautstaerke" ;
VAL_ 1355 PH_WAH_Meldung 0 "Init" 1 "Fehlermeldung_bei_Nichtverfuegbarkeit_mit_Gong" 2 "Fehlermeldung_bei_Nichtverfuegbarkeit_ohne_Gong" 3 "Anzeige_dass_Fahrzeug_erkannt_wurde_und_Funktion_aktiv_ist" 4 "Wiederanfahrhinweis_mit_Gong" 5 "Wiederanfahrhinweis_ohne_Gong" ;
VAL_ 1355 RBF_PaCo_Anf_Meldungen 0 "Init" 1 "RBF_eingeschraenkt_Sensorsicht" 2 "RBF_eingeschraenkt_Reinigung" 3 "RBF_nicht_verfuegbar" 4 "RBF_Notbremsung" 5 "RBF_zurzeit_eingeschraenkt" 6 "RBF_eingeschraenkt_reinigen" ;
VAL_ 1355 RBF_PMO_Bereich_erkannt 0 "Nicht_erkannt" 1 "Erkannt" ;
VAL_ 2527679498 Perso_Kontonummer 0 "kein_Benutzerkonto" 1 "Benutzerkonto_1" 2 "Benutzerkonto_2" 3 "Benutzerkonto_3" 4 "Benutzerkonto_4" 5 "Benutzerkonto_5" 6 "Benutzerkonto_6" 7 "Benutzerkonto_7" ;
VAL_ 2527679498 Perso_Steuerung 0 "keine_Steuerung" 1 "Reset_alle_Konten" 2 "Reset_aktives_Konto" 3 "Kopiere_aktives_Konto_nach" 4 "Wiederherstellen_aktives_Konto" 5 "Aktivieren_aktives_Konto" 6 "Reset_Konto" 7 "Reset_alle_Fahrer" 8 "Reset_aktiver_Fahrer" 9 "Reset_Fahrer" ;
VAL_ 2527679498 Perso_Steuerungsparameter 0 "kein_Parameter" 1 "Benutzerkonto_1" 2 "Benutzerkonto_2" 3 "Benutzerkonto_3" 4 "Benutzerkonto_4" 5 "Benutzerkonto_5" 6 "Benutzerkonto_6" 7 "Benutzerkonto_7" ;
VAL_ 2527679498 Perso_Status 0 "deaktiviert" 1 "PSO_1x_aktiviert" 2 "PSO_2x_aktiviert" ;
VAL_ 2527679498 Perso_Bedienstelle 0 "Init" 1 "Kombiinstrument" 2 "ABT" ;
VAL_ 2527679498 Perso_Freigabe_Verstellung 0 "Init" 1 "freigegeben" ;
VAL_ 2527679498 Perso_Aktiv 0 "deaktiviert" 1 "aktiviert" ;
VAL_ 2527679498 IAA_PSO_wake_up 0 "wake_up_inactive" 1 "wake_up_active" ;
VAL_ 2527679498 Perso_Fahrernummer 0 "kein_Fahrer" 1 "Fahrer_1" 2 "Fahrer_2" 3 "Fahrer_3" 4 "Fahrer_4" 5 "Fahrer_5" 6 "Fahrer_6" 7 "Fahrer_7" ;
VAL_ 2527679498 Perso_Schreibschutz 0 "Schreibschutz_deaktiviert" 1 "Schreibschutz_aktiviert" ;
VAL_ 2463978629 Perso_Kontonummer_02 0 "kein_Benutzerkonto" 1 "Benutzerkonto_1" 2 "Benutzerkonto_2" 3 "Benutzerkonto_3" 4 "Benutzerkonto_4" 5 "Benutzerkonto_5" 6 "Benutzerkonto_6" 7 "Benutzerkonto_7" ;
VAL_ 2463978629 Perso_Steuerung_02 0 "keine_Steuerung" 1 "Reset_alle_Konten" 2 "Reset_aktives_Konto" 3 "Kopiere_aktives_Konto_nach" 4 "Wiederherstellen_aktives_Konto" 5 "Aktivieren_aktives_Konto" 6 "Reset_Konto" 7 "Reset_alle_Fahrer" 8 "Reset_aktiver_Fahrer" 9 "Reset_Fahrer" ;
VAL_ 2463978629 Perso_Steuerungsparameter_02 0 "kein_Parameter" 1 "Benutzerkonto_1" 2 "Benutzerkonto_2" 3 "Benutzerkonto_3" 4 "Benutzerkonto_4" 5 "Benutzerkonto_5" 6 "Benutzerkonto_6" 7 "Benutzerkonto_7" ;
VAL_ 2463978629 Perso_Status_02 0 "InitWert_deaktiviert" 1 "PSO_1x_aktiviert" 2 "PSO_2x_aktiviert" ;
VAL_ 2463978629 Perso_Bedienstelle_02 0 "Init" 1 "Kombiinstrument" 2 "ABT" ;
VAL_ 2463978629 Perso_Freigabe_Verstellung_02 0 "Init" 1 "freigegeben" ;
VAL_ 2463978629 Perso_Aktiv_02 0 "deaktiviert" 1 "aktiviert" ;
VAL_ 2463978629 Perso_Fahrernummer_02 0 "kein_Fahrer" 1 "Fahrer_1" 2 "Fahrer_2" 3 "Fahrer_3" 4 "Fahrer_4" 5 "Fahrer_5" 6 "Fahrer_6" 7 "Fahrer_7" ;
VAL_ 2463978629 Perso_Schreibschutz_02 0 "Schreibschutz_deaktiviert" 1 "Schreibschutz_aktiviert" ;
VAL_ 319 PreCrash_Charisma_FahrPr 0 "keine_Funktion" 1 "Programm_1" 2 "Programm_2" 3 "Programm_3" 4 "Programm_4" 5 "Programm_5" 6 "Programm_6" 7 "Programm_7" 8 "Programm_8" 9 "Programm_9" 10 "Programm_10" 11 "Programm_11" 12 "Programm_12" 13 "Programm_13" 14 "Programm_14" 15 "Programm_15" ;
VAL_ 319 PreCrash_Charisma_Status 0 "Init" 1 "verfuegbar" 2 "nicht_verfuegbar" 3 "asynchron_durch_Fahrerwunsch" ;
VAL_ 319 PreCrash_Schiebedach_schliessen 0 "keine_Schliessung" 1 "Schliessung_angefordert" ;
VAL_ 319 PreCrash_Fenster_schliessen 0 "keine_Schliessung" 1 "Schliessung_angefordert" ;
VAL_ 319 PreCrash_Blinken 0 "keine_Blinkanforderung" 1 "Warnblinken" 2 "RECAS_Blinken" 3 "Notbremsblinken" ;
VAL_ 319 SC_PreSense_FCWP 0 "Warnung_gilt_fuer_Objekte" 1 "Warnung_gitl_fuer_Fussgaenger" ;
VAL_ 319 PreCrash_Tueren_Verriegeln 0 "keine_Anforderung" 1 "Tueren_Verriegeln" ;
VAL_ 319 PreCrash_FS_Laengsverstellung 0 "nicht_angefordert" 1 "angefordert" ;
VAL_ 319 PreCrash_Anforderung_AFR 0 "keine_Anforderung" 1 "linke_Seite" 2 "rechte_Seite" 3 "Vorderachse" 4 "Hinterachse" 5 "Vorwarnung" 7 "Init" ;
VAL_ 319 SC_PreCrash_LED 0 "keine_Anzeige" 1 "Stufe_1_glimmen" 2 "Stufe_2_leuchten" 3 "Stufe_3_blinken" ;
VAL_ 319 PreCrash_FS_Pneumatik_ansteuern 0 "keine_Anforderung" 1 "Pneumatik_ansteuern" ;
VAL_ 319 PreCrash_BFS_Pneumatik_ansteuern 0 "keine_Anforderung" 1 "Pneumatik_ansteuern" ;
VAL_ 319 PreCrash_Fo_Pneumatik_ansteuern 0 "keine_Anforderung" 1 "Pneumatik_ansteuern" ;
VAL_ 319 PreCrash_FS_Sitzlehne_verfahren 0 "keine_Anforderung" 1 "reserviert" 2 "reserviert" 3 "Sitzlehnenkopf_in_pos_xRichtung_verfahrenvor" 4 "Sitzlehnenkopf_in_neg_xRichtung_verfahrenzurueck" 6 "reserviert" 7 "Lehnenkopfverstellung_ansteuern" ;
VAL_ 319 PreCrash_BFS_Sitzlehne_verfahren 0 "keine_Anforderung" 1 "reserviert" 2 "reserviert" 3 "Sitzlehnenkopf_in_pos_xRichtung_verfahrenvor" 4 "Sitzlehnenkopf_in_neg_xRichtung_verfahrenzurueck" 6 "reserviert" 7 "Lehnenkopfverstellung_ansteuern" ;
VAL_ 319 PreCrash_Fo_Sitzlehne_verfahren 0 "keine_Anforderung" 1 "reserviert" 2 "reserviert" 3 "Sitzlehnenkopf_in_pos_xRichtung_verfahrenvor" 4 "Sitzlehnenkopf_in_neg_xRichtung_verfahrenzurueck" ;
VAL_ 319 PreCrash_FS_KSV_verfahren 0 "keine_Anforderung" 1 "in_pos_xRichtung_verfahren" 2 "in_neg_xRichung_verfahren" 3 "in_pos_zRichtung_verfahren" 4 "in_neg_zRichtung_verfahren" 5 "in_pos_xRichtung_und_neg_zRichtung_verfahren" 6 "in_pos_x_Richtung_und_pos_zRichtung_verfahren" 7 "in_neg_xRichtung_und_neg_zRichtung_verfahren" 8 "in_neg_xRichtung_und_pos_zRichtung_verfahren" 9 "Kopfstuetze_ansteuern" ;
VAL_ 319 PreCrash_BFS_KSV_verfahren 0 "keine_Anforderung" 1 "in_pos_xRichtung_verfahren" 2 "in_neg_xRichung_verfahren" 3 "in_pos_zRichtung_verfahren" 4 "in_neg_zRichtung_verfahren" 5 "in_pos_xRichtung_und_neg_zRichtung_verfahren" 6 "in_pos_x_Richtung_und_pos_zRichtung_verfahren" 7 "in_neg_xRichtung_und_neg_zRichtung_verfahren" 8 "in_neg_xRichtung_und_pos_zRichtung_verfahren" 9 "Kopfstuetze_ansteuern" ;
VAL_ 319 PreCrash_Fo_KSV_verfahren 0 "keine_Anforderung" 1 "in_pos_xRichtung_verfahren" 2 "in_neg_xRichung_verfahren" 3 "in_pos_zRichtung_verfahren" 4 "in_neg_zRichtung_verfahren" 5 "in_pos_xRichtung_und_neg_zRichtung_verfahren" 6 "in_pos_x_Richtung_und_pos_zRichtung_verfahren" 7 "in_neg_xRichtung_und_neg_zRichtung_verfahren" 8 "in_neg_xRichtung_und_pos_zRichtung_verfahren" ;
VAL_ 319 PreCrash_BFS_Laengsverstellung 0 "nicht_angefordert" 1 "angefordert" ;
VAL_ 319 SC_PreCrash_Warnung 0 "keine_Anzeige" 1 "latente_Vorwarnung" 2 "Vorwarnung" 3 "Akutwarnung" 4 "Eingriff" 5 "Fahreruebernahmeaufforderung" 6 "Abbiegewarnung" 7 "Basiseingriff" 8 "Heckeingriff" ;
VAL_ 319 SC_PreCrash_Texte 0 "keine_Anzeige" 1 "Systemstoerung" 2 "keine_Sensorsicht" 3 "Demomodus" 4 "System_aus" 5 "Anhaengerbetrieb" 6 "ESC_aus" 7 "zurzeit_eingeschraenkt" 8 "zurzeit_eingeschraenkt_ESP_Aus" 9 "Initialisierung" ;
VAL_ 1122 PSD_Segment_ID 0 "keine Segmentinformationen vorhanden" 1 "Fehlerwert" ;
VAL_ 1122 PSD_Vorgaenger_Segment_ID 0 "keine Segmentinformation vorhanden" 1 "Fehlerwert" ;
VAL_ 1122 PSD_Strassenkategorie 0 "Rest_Feldweg_Schotterweg_Privatweg" 1 "Ortsstraße" 2 "Kreisstraße" 3 "Landstraße" 4 "Bundesstraße" 5 "Autobahn" 7 "Init" ;
VAL_ 1122 PSD_Endkruemmung 255 "Gerade" ;
VAL_ 1122 PSD_Endkruemmung_Vorz 0 "Kruemmung_positiv" 1 "Kruemmung_negativ" ;
VAL_ 1122 PSD_Idenditaets_ID 0 "keine_Segment_Informationen_vorhanden" 1 "Fehler" ;
VAL_ 1122 PSD_ADAS_Qualitaet 0 "keine_ADAS_Qualitaet" 1 "ADAS_Qualitaet" ;
VAL_ 1122 PSD_wahrscheinlichster_Pfad 0 "Pfad_mit_geringer_Wahrscheinlichkeit" 1 "wahrscheinlichster_Pfad" ;
VAL_ 1122 PSD_Geradester_Pfad 0 "nicht_geradester_PFad" 1 "geradester_Pfad" ;
VAL_ 1122 PSD_Fahrspuren_Anzahl 0 "Einbahnstrasse_in_falsche_Richtung" 1 "eine_Fahrspur" 2 "zwei_Fahrspuren" 3 "drei_Fahrspuren" 4 "vier_Fahrspuren" 5 "fuenf_Fahrspuren" 6 "sechs_Fahrspuren" 7 "mehr_als_sechs_Fahrspuren" ;
VAL_ 1122 PSD_Bebauung 0 "ausserhalb_bebauten_Gebietes" 1 "innerhalb_bebauten_Gebietes" ;
VAL_ 1122 PSD_Segment_Komplett 0 "Segment_Attribute_nicht_komplett" 1 "Segment_Attribute_komplett" ;
VAL_ 1122 PSD_Rampe 0 "Strasse_mit_Gegenverkehr" 1 "Auffahrt_Einbahnstr" 2 "Abfahrt_Einbahnstr" 3 "Einbahnstrasse" ;
VAL_ 1122 PSD_Anfangskruemmung 255 "Gerade" ;
VAL_ 1122 PSD_Anfangskruemmung_Vorz 0 "positiv" 1 "negativ" ;
VAL_ 1122 PSD_Abzweigerichtung 0 "rects_abzweigende_Strasse" 1 "links_abzweigende_Strasse" ;
VAL_ 1123 PSD_Pos_Segment_ID 0 "keine Position gegeben" 1 "Fehlerwert" ;
VAL_ 1123 PSD_Pos_Standort_Eindeutig 0 "mehrdeutiger_Standort" 1 "eindeutiger_Standort" ;
VAL_ 1123 PSD_Pos_Fehler_Laengsrichtung 0 "Init" 1 "< 2m" 2 "< 5m" 3 "< 10m" 4 "< 20m" 5 "< 50m" 6 "> 50m" 7 "Off-Road" ;
VAL_ 1123 PSD_Pos_Fahrspur 0 "unbekannt" 1 "Erste_Spur_von_rechts" 2 "Zweite_Spur_von_rechts" 3 "Dritte_Spur_von_rechts" 4 "Vierte_Spur_von_rechts" 5 "Fuenfte_Spur_von_rechts" 6 "Sechte_Spur_von_rechts" 7 "Siebte_oder_weitere_Spur_von_rechts" ;
VAL_ 1123 PSD_Attribut_Segment_ID_05 0 "keine_Segment_Information" 1 "Fehler" ;
VAL_ 1123 PSD_Attribut_1_ID 0 "keine_Information" ;
VAL_ 1123 PSD_Attribut_2_ID 0 "keine_Information" ;
VAL_ 1123 PSD_Attribute_Komplett_05 0 "Attribute_nicht_komplett" 1 "Attribute_komplett" ;
VAL_ 1124 PSD_06_Mux 0 "Init" ;
VAL_ 1124 PSD_Sys_Segment_ID 0 "keine Segmentinformationen vorhanden" 1 "nicht zulaessig" ;
VAL_ 1124 PSD_Attribut_Segment_ID 0 "keine_Segment_Information_vorhanden" 1 "Fehler" ;
VAL_ 1124 PSD_Ges_Segment_ID 0 "keine Segmentinformationen vorhanden" 1 "nicht zulaessig" ;
VAL_ 1124 PSD_Baum_Laenge_VZ 0 "Ost" 1 "West" ;
VAL_ 1124 PSD_Steigung_1_Segment_ID 0 "keine_Segment_Information_vorhanden" 1 "Fehler" ;
VAL_ 1124 PSD_Baum_Laenge 33554431 "keine_GPS_Information" ;
VAL_ 1124 PSD_Attribut_3_ID 0 "keine_Information" ;
VAL_ 1124 PSD_Steigung_1_A_Steigung 126 "mehr_als_15_Prozent" 127 "Steigung_unbekannt" ;
VAL_ 1124 PSD_Ges_Geschwindigkeit 0 "Kein Geschwindigkeitsgebot" 1 "0 km/h < v_max <  5 km/h" 2 "5 km/h < v_max < 10km/h" 3 "10 km/h < v_max < 15 km/h" 4 "15 km/h < v_max < 20 km/h" 5 "20 km/h < v_max < 25 km/h" 6 "25 km/h < v_max < 30 km/h" 7 "30 km/h < v_max < 35 km/h" 8 "35 km/h < v_max < 40 km/h" 9 "40 km/h < v_max < 45 km/h" 10 "45 km/h < v_max < 50 km/h" 11 "50 km/h < v_max < 60 km/h" 12 "60 km/h < v_max < 70 km/h" 13 "70 km/h < v_max < 80 km/h" 14 "80 km/h < v_max < 90 km/h" 15 "90 km/h < v_max < 100 km/h" 16 "100 km/h < v_max < 110 km/h" 17 "110 km/h < v_max < 120 km/h" 18 " 120 km/h < v_max < 130 km/h" 19 "130 km/h < v_max < 140 km/h" 20 "140 km/h < v_max < 150 km/h" 21 "150 km/h < v_max < 160 km/h" 22 "160 km/h < v_max" 23 "Geschwindigkeitsgebot aufgehoben" 24 "..0x1F ungültig" ;
VAL_ 1124 PSD_Steigung_1_A_Vorz 0 "Gefaelle" 1 "Steigung" ;
VAL_ 1124 PSD_Sys_Geschwindigkeit_Einheit 0 "km/h" 1 "mph" ;
VAL_ 1124 PSD_Sys_Verkehrsrichtung 0 "Rechtsverkehr" 1 "Linksverkehr" ;
VAL_ 1124 PSD_Sys_Geometrieguete 0 "Geringe_Guete" 1 "tbd" 2 "tbd" 3 "Hohe_Guete" ;
VAL_ 1124 PSD_Sys_Mapmatchingguete 0 "geringe_Guete" 1 "res" 2 "res" 3 "hohe_Guete" ;
VAL_ 1124 PSD_Ges_Typ 0 "Geschw_Klasse_des_Kartendatensuppliers" 1 "Explizit_abgeleiteten_Begrenzung" 2 "Durch_Gesetzg_vorgeg_allgem_Gebot_fuer_uebertr_Rahmenbed" 3 "Init" ;
VAL_ 1124 PSD_Sys_Alter_Karte 0 "kleiner_1_Jahr" 1 "1_Jahr" 2 "2_Jahre" 3 "3_Jahre" 4 "4_Jahre" 5 "5_Jahre" 6 "6_Jahre" 7 "groesser_7_Jahre" ;
VAL_ 1124 PSD_Ges_Spur_Geschw_Begrenzung 0 "Gebot_fuer_alle_spuren_gueltig" ;
VAL_ 1124 PSD_Steigung_1_B_Steigung 126 "mehr_als_15_Prozent" 127 "Steigung_unbekannt" ;
VAL_ 1124 PSD_Attribut_4_ID 0 "keine_Information" ;
VAL_ 1124 PSD_Sys_Zielfuehrung 0 "Zielfuehrung nicht aktiv" 1 "Zielfuehrung aktiv" ;
VAL_ 1124 PSD_Sys_US_State 0 "kein_US_State" 1 "Alabama" 2 "Alaska" 3 "Arkansas" 4 "Arizona" 5 "California" 6 "Colorado" 7 "Conneticut" 8 "District_of_Columbia" 9 "Delaware" 10 "Florida" 11 "Georgia" 12 "Hawaii" 13 "Idaho" 14 "Illinois" 15 "Iowa" 16 "Indiana" 17 "Kansas" 18 "Kentucky" 19 "Louisiana" 20 "Massachusetts" 21 "Maryland" 22 "Maine" 23 "Michigan" 24 "Minnesota" 25 "Missouri" 26 "Mississippi" 27 "Montana" 28 "North_Carolina" 29 "North_Dakota" 30 "Nebraska" 31 "Nevada" 32 "New_Hampshire" 33 "New_Jersey" 34 "New_Mexico" 35 "New_York" 36 "Ohio" 37 "Oklahoma" 38 "Oregon" 39 "Pennsylvania" 40 "Puerto_Rico" 41 "Rhode_Island" 42 "South_Carolina" 43 "South_Dakota" 44 "Tennessee" 45 "Texas" 46 "Utah" 47 "Virginia" 48 "Virgin_Islands" 49 "Vermont" 50 "Washington" 51 "Wisconsin" 52 "West_Virginia" 53 "Wyoming" ;
VAL_ 1124 PSD_Ges_Geschwindigkeit_Gespann 0 "alle Fahrzeuge" 1 "PKW mit Gespann" 2 "LKW, Busse, etc." ;
VAL_ 1124 PSD_Baum_Breite_VZ 0 "Nord" 1 "Sued" ;
VAL_ 1124 PSD_Ges_Geschwindigkeit_Witter 0 "Witterungsunabhängig" 1 "Nässe, Regen, Niederschlag" 2 "Glätte" 3 "Nebel" ;
VAL_ 1124 PSD_Steigung_1_B_Vorz 0 "Gefaelle" 1 "Steigung" ;
VAL_ 1124 PSD_Ges_Geschwindigkeit_Tag_Anf 0 "kein Beginn definiert" 1 "Montag" 2 "Dienstag" 3 "Mittwoch" 4 "Donnerstag" 5 "Freitag" 6 "Samstag" 7 "Sonntag" ;
VAL_ 1124 PSD_Ges_Geschwindigkeit_Tag_Ende 0 "kein Ende definiert" 1 "Montag" 2 "Dienstag" 3 "Mittwoch" 4 "Donnerstag" 5 "Freitag" 6 "Samstag" 7 "Sonntag" ;
VAL_ 1124 PSD_Sys_Quali_verfuegbar 0 "Qualitaetskriterien_nicht_verfuegbar" 1 "Qualitaetskriterien_verfuegbar" ;
VAL_ 1124 PSD_Sys_Zielfuehrung_geaendert 0 "Zielfuehrung_nicht_geaendert" 1 "Zielfuehrung_geaendert" ;
VAL_ 1124 PSD_Ges_Geschwindigkeit_Std_Anf 25 "kein Beginn für stundenweise Einschränkungen" ;
VAL_ 1124 PSD_Steigung_1_Attribute_kompl 0 "Steigungen_nicht_komplett" 1 "Steigungen_komplett" ;
VAL_ 1124 PSD_Sys_Geometrieguete_erweitert 0 "Init" ;
VAL_ 1124 PSD_Steigung_2_Segment_ID 0 "keine_Segment_Information_vorhanden" 1 "Fehler" ;
VAL_ 1124 PSD_Attribut_5_ID 0 "keine_Information" ;
VAL_ 1124 PSD_Ges_Geschwindigkeit_Std_Ende 25 "kein Ende für stundenweise Einschränkungen" ;
VAL_ 1124 PSD_Steigung_2_Steigung 126 "mehr_als_15_Prozent" 127 "Steigung_unbekannt" ;
VAL_ 1124 PSD_Ges_Ueberholverbot 0 "kein Überholverbot" 1 "alle Fahrzeuge" 2 "Überholverbot für PKW mit Gespann" 3 "Überholverbot für LKW, Busse, etc." ;
VAL_ 1124 PSD_Ges_Wechselverkehrszeichen 0 "Kein Wechselverkehrszeichen" 1 "Wechselverkehrszeichen links" 2 "Wechselverkehrszeichen rechts" 3 "Wechselverkehrszeichen links und rechts" 4 "Wechselverkerhszeichen über der Fahrbahn" ;
VAL_ 1124 PSD_Steigung_2_Vorz 0 "Gefaelle" 1 "Steigung" ;
VAL_ 1124 PSD_Wechselverkehrszeichen_Typ 0 "kein_Wechselverkehrszeichen" 1 "LED_Wechselverkehrszeichen" 2 "nicht_LED_Wechselverkehrszeichen" ;
VAL_ 1124 PSD_Ges_Gesetzlich_Kategorie 0 "kein_legales_Verbot" 1 "innerorts" 2 "ausserorts" 3 "Autobahn" ;
VAL_ 1124 PSD_Attribute_Komplett_06 0 "Attribute_nicht_komplett" 1 "Attribute_komplett" ;
VAL_ 1124 PSD_Ges_Gesetzlich_Zusatz 0 "kein_Zusatz_zu_legalem_Gebot" 1 "Anhaenger_Klasse_1" 2 "Anhaenger_Klasse_2" ;
VAL_ 1124 PSD_Ges_Verkehrszeichen_Quelle 0 "VZA_kein_Onlinedienst" 1 "nur_VZA" 2 "nur_VZO" 3 "VZA_und_VZO" ;
VAL_ 1124 PSD_Steigung_2_Attribute_kompl 0 "Steigungen_nicht_komplett" 1 "Steigungen_komplett" ;
VAL_ 1124 PSD_Ges_Attribute_Komplett 0 "Attribute_nicht_komplett" 1 "Attribute_komplett" ;
VAL_ 1125 PSD_LR_01_MUX 0 "Init" ;
VAL_ 1125 PSD_LR_Attribut_1_Wert 0 "Init" ;
VAL_ 1125 PSD_LR_Steigung_1_Vorz 0 "Gefaelle" 1 "Steigung" ;
VAL_ 1125 PSD_LR_Globale_Steigung_Vorz 0 "Gefaelle" 1 "Steigung" ;
VAL_ 1125 PSD_LR_Attribut_2_Wert 0 "Init" ;
VAL_ 1125 PSD_LR_Steigung_2_Vorz 0 "Gefaelle" 1 "Steigung" ;
VAL_ 1125 PSD_LR_Attribut_3_Wert 0 "Init" ;
VAL_ 1125 PSD_LR_Steigung_3_Vorz 0 "Gefaelle" 1 "Steigung" ;
VAL_ 1125 PSD_LR_Reset 0 "kein Reset" 1 "Reset" ;
VAL_ 1616 RA_Radio_Error_Flag 0 "kein_KD_Fehler" 1 "KD_Fehler" ;
VAL_ 1616 RA_Frequency_unit 0 "1_kHz" 1 "100_kHz" ;
VAL_ 1616 RA_AM_Tuning 0 "frequency_locked" 1 "AM_tuning" ;
